VERSION ""

NS_ :

BS_:

BU_:

BO_ 2566631678 DCACAI5CFG1: 13 Vector__XXX
 SG_ DCACAssIvt5ACSdDtFqCdStt : 96|8@1+ (1,0) [0|250] "Hz" Vector__XXX
 SG_ DCACAssIvt5ACSdRMSCtMxLtStt : 48|16@1+ (0.03125,0) [0|2007.96875] "Arms" Vector__XXX
 SG_ DCACAssIvt5ACSdRMSVtMxLtStt : 32|16@1+ (0.03125,0) [0|2007.96875] "Vrms" Vector__XXX
 SG_ DCACAssIvt5DCSdCtMLtStt : 80|16@1+ (0.05,-3212.75) [-3212.75|0] "A" Vector__XXX
 SG_ DCACAssIvt5DCSdCtMxLtStt : 16|16@1+ (0.05,0) [0|3212.75] "A" Vector__XXX
 SG_ DCACAssIvt5DCSdVtMLtStt : 0|16@1+ (0.05,0) [0|3212.75] "V" Vector__XXX
 SG_ DCACAssIvt5DCSdVtMxLtStt : 64|16@1+ (0.05,0) [0|3212.75] "V" Vector__XXX

BO_ 2566631934 DCACAI5LD: 8 Vector__XXX
 SG_ DCACAssrInvrtr5TtlDCInptChrg : 0|32@1+ (100,0) [0|421108121500] "Ah" Vector__XXX
 SG_ DCACAssrInvrtr5TtlDCInptEnrg : 32|32@1+ (100,0) [0|421108121500] "Watt-hour" Vector__XXX

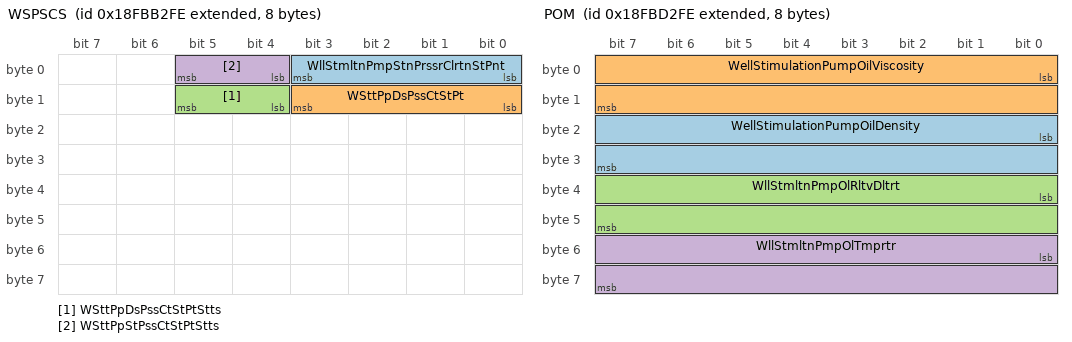
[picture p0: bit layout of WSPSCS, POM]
BO_ 2566632190 WSPSCS: 8 Vector__XXX
 SG_ WllStmltnPmpStnPrssrClrtnStPnt : 0|4@1+ (1,0) [0|15] "" Vector__XXX
 SG_ WSttPpDsPssCtStPt : 8|4@1+ (1,0) [0|15] "" Vector__XXX
 SG_ WSttPpDsPssCtStPtStts : 12|2@1+ (1,0) [0|3] "" Vector__XXX
 SG_ WSttPpStPssCtStPtStts : 4|2@1+ (1,0) [0|3] "" Vector__XXX

BO_ 2566632446 WSPFV: 8 Vector__XXX
 SG_ WllStmltnPmpTrpFldPmpd : 32|32@1+ (0.5,0) [0|2105540607.5] "l" Vector__XXX
 SG_ WllStmltnPmpTtlFldPmpd : 0|32@1+ (0.5,0) [0|2105540607.5] "l" Vector__XXX

BO_ 2566632702 WSPSN: 200 Vector__XXX
 SG_ WllStmltnPmpFldEndSrlNmr : 8|8@1+ (1,0) [0|255] "ASCII" Vector__XXX
 SG_ WllStmltnPmpPwrEndSrlNmr : 0|8@1+ (1,0) [0|255] "ASCII" Vector__XXX

BO_ 2566632958 WSPH2: 8 Vector__XXX
 SG_ WllStmltnPmpFldEndTrpHrs : 0|32@1+ (1,0) [0|4211081215] "s" Vector__XXX
 SG_ WllStmltnPmpPwrEndTrpHrs : 32|32@1+ (1,0) [0|4211081215] "s" Vector__XXX

BO_ 2566633214 AT1OG4: 8 Vector__XXX
 SG_ Aftrtrtmnt1OtltOxgnPmpngCrrnt : 0|16@1+ (0.001,-32.127) [-32.127|32.128] "mA" Vector__XXX
 SG_ Atttt1OttNOxSsPttAPssAst : 16|16@1+ (0.1,0) [0|6425.5] "kPa" Vector__XXX

BO_ 2566633470 AT1IG4: 8 Vector__XXX
 SG_ Aftrtrtmnt1IntkOxgnPmpngCrrnt : 0|16@1+ (0.001,-32.127) [-32.127|32.128] "mA" Vector__XXX
 SG_ Atttt1ItNOxSsPttAPssAst : 16|16@1+ (0.1,0) [0|6425.5] "kPa" Vector__XXX

BO_ 2566633726 DCDC4LD: 16 Vector__XXX
 SG_ DCDC4TotalHighSideCharge : 64|32@1+ (100,0) [0|421108121500] "Ah" Vector__XXX
 SG_ DCDC4TotalHighSideEnergy : 0|32@1+ (100,0) [0|421108121500] "Watt-hour" Vector__XXX
 SG_ DCDC4TotalLowSideCharge : 96|32@1+ (100,0) [0|421108121500] "Ah" Vector__XXX
 SG_ DCDC4TotalLowSideEnergy : 32|32@1+ (100,0) [0|421108121500] "Watt-hour" Vector__XXX

BO_ 2566633982 DCDC4CFG1: 19 Vector__XXX
 SG_ DCDC4HghSdCrrntMxmmLmtSttng : 32|16@1+ (0.05,0) [0|3212.75] "A" Vector__XXX
 SG_ DCDC4HghSdVltgMnmmLmtSttng : 0|16@1+ (0.05,0) [0|3212.75] "V" Vector__XXX
 SG_ DCDC4HghSdVltgMxmmLmtSttng : 16|16@1+ (0.05,0) [0|3212.75] "V" Vector__XXX
 SG_ DCDC4LwSdCrrntMxmmLmtSttng : 80|16@1+ (0.05,0) [0|3212.75] "A" Vector__XXX
 SG_ DCDC4LwSdVltgBkDfltSttng : 136|16@1+ (0.01,0) [0|642.55] "V" Vector__XXX
 SG_ DCDC4LwSdVltgMnmmLmtSttng : 48|16@1+ (0.01,0) [0|642.55] "V" Vector__XXX
 SG_ DCDC4LwSdVltgMxmmLmtSttng : 64|16@1+ (0.01,0) [0|642.55] "V" Vector__XXX
 SG_ DCDC4SLIBttrTmprtrMxmmLmtSttng : 128|8@1+ (1,-40) [-40|210] "degC" Vector__XXX
 SG_ DCDC4SLIBttTCCtMxLtStt : 112|16@1+ (0.05,0) [0|3212.75] "A" Vector__XXX
 SG_ DCDC4SLIBttTVtMxLtStt : 96|16@1+ (0.01,0) [0|642.55] "V" Vector__XXX

BO_ 2566635262 DCDC3LD: 16 Vector__XXX
 SG_ DCDC3TotalHighSideCharge : 64|32@1+ (100,0) [0|421108121500] "Ah" Vector__XXX
 SG_ DCDC3TotalHighSideEnergy : 0|32@1+ (100,0) [0|421108121500] "Watt-hour" Vector__XXX
 SG_ DCDC3TotalLowSideCharge : 96|32@1+ (100,0) [0|421108121500] "Ah" Vector__XXX
 SG_ DCDC3TotalLowSideEnergy : 32|32@1+ (100,0) [0|421108121500] "Watt-hour" Vector__XXX

BO_ 2566635518 DCDC3CFG1: 19 Vector__XXX
 SG_ DCDC3HghSdCrrntMxmmLmtSttng : 32|16@1+ (0.05,0) [0|3212.75] "A" Vector__XXX
 SG_ DCDC3HghSdVltgMnmmLmtSttng : 0|16@1+ (0.05,0) [0|3212.75] "V" Vector__XXX
 SG_ DCDC3HghSdVltgMxmmLmtSttng : 16|16@1+ (0.05,0) [0|3212.75] "V" Vector__XXX
 SG_ DCDC3LwSdCrrntMxmmLmtSttng : 80|16@1+ (0.05,0) [0|3212.75] "A" Vector__XXX
 SG_ DCDC3LwSdVltgBkDfltSttng : 136|16@1+ (0.01,0) [0|642.55] "V" Vector__XXX
 SG_ DCDC3LwSdVltgMnmmLmtSttng : 48|16@1+ (0.01,0) [0|642.55] "V" Vector__XXX
 SG_ DCDC3LwSdVltgMxmmLmtSttng : 64|16@1+ (0.01,0) [0|642.55] "V" Vector__XXX
 SG_ DCDC3SLIBttrTmprtrMxmmLmtSttng : 128|8@1+ (1,-40) [-40|210] "degC" Vector__XXX
 SG_ DCDC3SLIBttTCCtMxLtStt : 112|16@1+ (0.05,0) [0|3212.75] "A" Vector__XXX
 SG_ DCDC3SLIBttTVtMxLtStt : 96|16@1+ (0.01,0) [0|642.55] "V" Vector__XXX

BO_ 2566636798 DCDC2LD: 16 Vector__XXX
 SG_ DCDC2TotalHighSideCharge : 64|32@1+ (100,0) [0|421108121500] "Ah" Vector__XXX
 SG_ DCDC2TotalHighSideEnergy : 0|32@1+ (100,0) [0|421108121500] "Watt-hour" Vector__XXX
 SG_ DCDC2TotalLowSideCharge : 96|32@1+ (100,0) [0|421108121500] "Ah" Vector__XXX
 SG_ DCDC2TotalLowSideEnergy : 32|32@1+ (100,0) [0|421108121500] "Watt-hour" Vector__XXX

BO_ 2566637054 DCDC2CFG1: 19 Vector__XXX
 SG_ DCDC2HghSdCrrntMxmmLmtSttng : 32|16@1+ (0.05,0) [0|3212.75] "A" Vector__XXX
 SG_ DCDC2HghSdVltgMnmmLmtSttng : 0|16@1+ (0.05,0) [0|3212.75] "V" Vector__XXX
 SG_ DCDC2HghSdVltgMxmmLmtSttng : 16|16@1+ (0.05,0) [0|3212.75] "V" Vector__XXX
 SG_ DCDC2LwSdCrrntMxmmLmtSttng : 80|16@1+ (0.05,0) [0|3212.75] "A" Vector__XXX
 SG_ DCDC2LwSdVltgBkDfltSttng : 136|16@1+ (0.01,0) [0|642.55] "V" Vector__XXX
 SG_ DCDC2LwSdVltgMnmmLmtSttng : 48|16@1+ (0.01,0) [0|642.55] "V" Vector__XXX
 SG_ DCDC2LwSdVltgMxmmLmtSttng : 64|16@1+ (0.01,0) [0|642.55] "V" Vector__XXX
 SG_ DCDC2SLIBttrTmprtrMxmmLmtSttng : 128|8@1+ (1,-40) [-40|210] "degC" Vector__XXX
 SG_ DCDC2SLIBttTCCtMxLtStt : 112|16@1+ (0.05,0) [0|3212.75] "A" Vector__XXX
 SG_ DCDC2SLIBttTVtMxLtStt : 96|16@1+ (0.01,0) [0|642.55] "V" Vector__XXX

BO_ 2566638590 EEPCSI: 8 Vector__XXX
 SG_ ExhstPrtltCntrlSstmDgnstCnt : 32|32@1+ (1,0) [0|4211081215] "count" Vector__XXX
 SG_ ExhstPrtltCntrlSstmDgnstTm : 0|32@1+ (1,0) [0|4211081215] "s" Vector__XXX

BO_ 2566638846 WSPH: 16 Vector__XXX
 SG_ WllStmltnPmpMntnnIntrvlHrs : 0|32@1+ (1,0) [0|4211081215] "s" Vector__XXX
 SG_ WllStmltnPmpPkngOprtnHrs : 64|32@1+ (1,0) [0|4211081215] "s" Vector__XXX
 SG_ WllStmltnPmpVlvOprtnHrs : 32|32@1+ (1,0) [0|4211081215] "s" Vector__XXX
 SG_ WllStmltnPmpVlvStOprtnHrs : 96|32@1+ (1,0) [0|4211081215] "s" Vector__XXX

BO_ 2566639102 WSPT2: 19 Vector__XXX
 SG_ WllStmltnPmpPlngrFrngOrdrSttng : 144|4@1+ (1,0) [0|15] "" Vector__XXX
 SG_ WllStmltnPmpRdLdHghThrshldSttng : 128|16@1+ (5,0) [0|321275] "kN" Vector__XXX
 SG_ WSttPpCstSpdHTsdStt : 112|16@1+ (0.125,0) [0|8031.875] "rpm" Vector__XXX
 SG_ WSttPpCstSpdLwTsdStt : 96|16@1+ (0.125,0) [0|8031.875] "rpm" Vector__XXX
 SG_ WSttPpDsPssHTsdStt : 80|16@1+ (5,0) [0|321275] "kPa" Vector__XXX
 SG_ WSttPpGBxOPssHTsdStt : 16|16@1+ (0.1,0) [0|6425.5] "kPa" Vector__XXX
 SG_ WSttPpGBxOPssLwTsdStt : 0|16@1+ (0.1,0) [0|6425.5] "kPa" Vector__XXX
 SG_ WSttPpGBxOTptHTsdStt : 40|8@1+ (1,-40) [-40|210] "degC" Vector__XXX
 SG_ WSttPpGBxOTptLwTsdStt : 32|8@1+ (1,-40) [-40|210] "degC" Vector__XXX
 SG_ WSttPpStPssHTsdStt : 64|16@1+ (0.1,-3212.7) [-3212.7|3212.8] "kPa" Vector__XXX
 SG_ WSttPpStPssLwTsdStt : 48|16@1+ (0.1,-3212.7) [-3212.7|3212.8] "kPa" Vector__XXX

BO_ 2566639614 DCDC1LD: 16 Vector__XXX
 SG_ DCDC1TotalHighSideCharge : 64|32@1+ (100,0) [0|421108121500] "Ah" Vector__XXX
 SG_ DCDC1TotalHighSideEnergy : 0|32@1+ (100,0) [0|421108121500] "Watt-hour" Vector__XXX
 SG_ DCDC1TotalLowSideCharge : 96|32@1+ (100,0) [0|421108121500] "Ah" Vector__XXX
 SG_ DCDC1TotalLowSideEnergy : 32|32@1+ (100,0) [0|421108121500] "Watt-hour" Vector__XXX

BO_ 2566639870 DCDC1CFG1: 19 Vector__XXX
 SG_ DCDC1HghSdCrrntMxmmLmtSttng : 32|16@1+ (0.05,0) [0|3212.75] "A" Vector__XXX
 SG_ DCDC1HghSdVltgMnmmLmtSttng : 0|16@1+ (0.05,0) [0|3212.75] "V" Vector__XXX
 SG_ DCDC1HghSdVltgMxmmLmtSttng : 16|16@1+ (0.05,0) [0|3212.75] "V" Vector__XXX
 SG_ DCDC1LwSdCrrntMxmmLmtSttng : 80|16@1+ (0.05,0) [0|3212.75] "A" Vector__XXX
 SG_ DCDC1LwSdVltgBkDfltSttng : 136|16@1+ (0.01,0) [0|642.55] "V" Vector__XXX
 SG_ DCDC1LwSdVltgMnmmLmtSttng : 48|16@1+ (0.01,0) [0|642.55] "V" Vector__XXX
 SG_ DCDC1LwSdVltgMxmmLmtSttng : 64|16@1+ (0.01,0) [0|642.55] "V" Vector__XXX
 SG_ DCDC1SLIBttrTmprtrMxmmLmtSttng : 128|8@1+ (1,-40) [-40|210] "degC" Vector__XXX
 SG_ DCDC1SLIBttTCCtMxLtStt : 112|16@1+ (0.05,0) [0|3212.75] "A" Vector__XXX
 SG_ DCDC1SLIBttTVtMxLtStt : 96|16@1+ (0.01,0) [0|642.55] "V" Vector__XXX

BO_ 2566640382 POM: 8 Vector__XXX
 SG_ WellStimulationPumpOilDensity : 16|16@1+ (0.00003052,0) [0|1.961] "g/cc" Vector__XXX
 SG_ WellStimulationPumpOilViscosity : 0|16@1+ (0.015625,0) [0|1003.984375] "Cp" Vector__XXX
 SG_ WllStmltnPmpOlRltvDltrt : 32|16@1+ (0.0001220703125,0) [0|7.844] "" Vector__XXX
 SG_ WllStmltnPmpOlTmprtr : 48|16@1+ (0.03125,-273) [-273|1734.96875] "degC" Vector__XXX

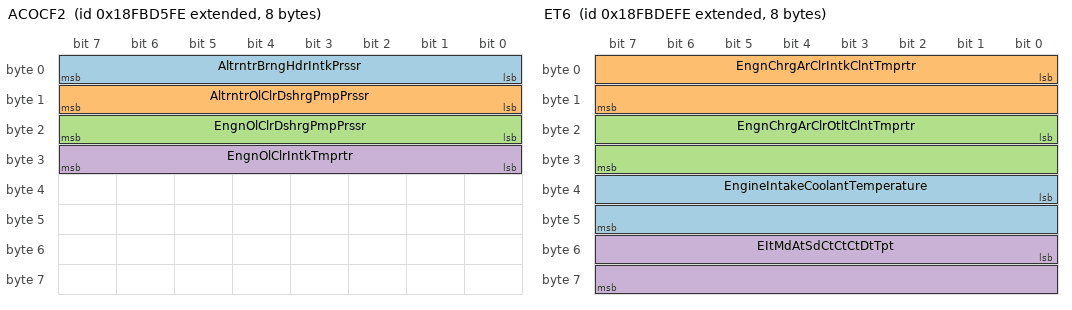
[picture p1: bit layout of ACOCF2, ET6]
BO_ 2566641150 ACOCF2: 8 Vector__XXX
 SG_ AltrntrBrngHdrIntkPrssr : 0|8@1+ (2,0) [0|500] "kPa" Vector__XXX
 SG_ AltrntrOlClrDshrgPmpPrssr : 8|8@1+ (2,0) [0|500] "kPa" Vector__XXX
 SG_ EngnOlClrDshrgPmpPrssr : 16|8@1+ (2,0) [0|500] "kPa" Vector__XXX
 SG_ EngnOlClrIntkTmprtr : 24|8@1+ (1,-40) [-40|210] "degC" Vector__XXX

BO_ 2566641406 EEC21: 8 Vector__XXX
 SG_ EngnExhstMnfldAsltPrssr1 : 0|16@1+ (0.1,0) [0|6425.5] "kPa" Vector__XXX
 SG_ EngnExhstMnfldAsltPrssr2 : 16|16@1+ (0.1,0) [0|6425.5] "kPa" Vector__XXX

BO_ 2566642942 DC4: 8 Vector__XXX
 SG_ EnableStatusofDoor21 : 4|2@1+ (1,0) [0|3] "" Vector__XXX
 SG_ EnableStatusofDoor22 : 10|2@1+ (1,0) [0|3] "" Vector__XXX
 SG_ EnableStatusofDoor23 : 16|2@1+ (1,0) [0|3] "" Vector__XXX
 SG_ EnableStatusofDoor24 : 22|2@1+ (1,0) [0|3] "" Vector__XXX
 SG_ EnableStatusofDoor25 : 28|2@1+ (1,0) [0|3] "" Vector__XXX
 SG_ EnableStatusofDoor26 : 34|2@1+ (1,0) [0|3] "" Vector__XXX
 SG_ EnableStatusofDoor27 : 40|2@1+ (1,0) [0|3] "" Vector__XXX
 SG_ EnableStatusofDoor28 : 46|2@1+ (1,0) [0|3] "" Vector__XXX
 SG_ EnableStatusofDoor29 : 52|2@1+ (1,0) [0|3] "" Vector__XXX
 SG_ EnableStatusofDoor30 : 58|2@1+ (1,0) [0|3] "" Vector__XXX
 SG_ LockStatusofDoor21 : 0|2@1+ (1,0) [0|3] "" Vector__XXX
 SG_ LockStatusofDoor22 : 6|2@1+ (1,0) [0|3] "" Vector__XXX
 SG_ LockStatusofDoor23 : 12|2@1+ (1,0) [0|3] "" Vector__XXX
 SG_ LockStatusofDoor24 : 18|2@1+ (1,0) [0|3] "" Vector__XXX
 SG_ LockStatusofDoor25 : 24|2@1+ (1,0) [0|3] "" Vector__XXX
 SG_ LockStatusofDoor26 : 30|2@1+ (1,0) [0|3] "" Vector__XXX
 SG_ LockStatusofDoor27 : 36|2@1+ (1,0) [0|3] "" Vector__XXX
 SG_ LockStatusofDoor28 : 42|2@1+ (1,0) [0|3] "" Vector__XXX
 SG_ LockStatusofDoor29 : 48|2@1+ (1,0) [0|3] "" Vector__XXX
 SG_ LockStatusofDoor30 : 54|2@1+ (1,0) [0|3] "" Vector__XXX
 SG_ OpenStatusofDoor21 : 2|2@1+ (1,0) [0|3] "" Vector__XXX
 SG_ OpenStatusofDoor22 : 8|2@1+ (1,0) [0|3] "" Vector__XXX
 SG_ OpenStatusofDoor23 : 14|2@1+ (1,0) [0|3] "" Vector__XXX
 SG_ OpenStatusofDoor24 : 20|2@1+ (1,0) [0|3] "" Vector__XXX
 SG_ OpenStatusofDoor25 : 26|2@1+ (1,0) [0|3] "" Vector__XXX
 SG_ OpenStatusofDoor26 : 32|2@1+ (1,0) [0|3] "" Vector__XXX
 SG_ OpenStatusofDoor27 : 38|2@1+ (1,0) [0|3] "" Vector__XXX
 SG_ OpenStatusofDoor28 : 44|2@1+ (1,0) [0|3] "" Vector__XXX
 SG_ OpenStatusofDoor29 : 50|2@1+ (1,0) [0|3] "" Vector__XXX
 SG_ OpenStatusofDoor30 : 56|2@1+ (1,0) [0|3] "" Vector__XXX

BO_ 2566643198 DC3: 8 Vector__XXX
 SG_ EnableStatusofDoor11 : 4|2@1+ (1,0) [0|3] "" Vector__XXX
 SG_ EnableStatusofDoor12 : 10|2@1+ (1,0) [0|3] "" Vector__XXX
 SG_ EnableStatusofDoor13 : 16|2@1+ (1,0) [0|3] "" Vector__XXX
 SG_ EnableStatusofDoor14 : 22|2@1+ (1,0) [0|3] "" Vector__XXX
 SG_ EnableStatusofDoor15 : 28|2@1+ (1,0) [0|3] "" Vector__XXX
 SG_ EnableStatusofDoor16 : 34|2@1+ (1,0) [0|3] "" Vector__XXX
 SG_ EnableStatusofDoor17 : 40|2@1+ (1,0) [0|3] "" Vector__XXX
 SG_ EnableStatusofDoor18 : 46|2@1+ (1,0) [0|3] "" Vector__XXX
 SG_ EnableStatusofDoor19 : 52|2@1+ (1,0) [0|3] "" Vector__XXX
 SG_ EnableStatusofDoor20 : 58|2@1+ (1,0) [0|3] "" Vector__XXX
 SG_ LockStatusofDoor11 : 0|2@1+ (1,0) [0|3] "" Vector__XXX
 SG_ LockStatusofDoor12 : 6|2@1+ (1,0) [0|3] "" Vector__XXX
 SG_ LockStatusofDoor13 : 12|2@1+ (1,0) [0|3] "" Vector__XXX
 SG_ LockStatusofDoor14 : 18|2@1+ (1,0) [0|3] "" Vector__XXX
 SG_ LockStatusofDoor15 : 24|2@1+ (1,0) [0|3] "" Vector__XXX
 SG_ LockStatusofDoor16 : 30|2@1+ (1,0) [0|3] "" Vector__XXX
 SG_ LockStatusofDoor17 : 36|2@1+ (1,0) [0|3] "" Vector__XXX
 SG_ LockStatusofDoor18 : 42|2@1+ (1,0) [0|3] "" Vector__XXX
 SG_ LockStatusofDoor19 : 48|2@1+ (1,0) [0|3] "" Vector__XXX
 SG_ LockStatusofDoor20 : 54|2@1+ (1,0) [0|3] "" Vector__XXX
 SG_ OpenStatusofDoor11 : 2|2@1+ (1,0) [0|3] "" Vector__XXX
 SG_ OpenStatusofDoor12 : 8|2@1+ (1,0) [0|3] "" Vector__XXX
 SG_ OpenStatusofDoor13 : 14|2@1+ (1,0) [0|3] "" Vector__XXX
 SG_ OpenStatusofDoor14 : 20|2@1+ (1,0) [0|3] "" Vector__XXX
 SG_ OpenStatusofDoor15 : 26|2@1+ (1,0) [0|3] "" Vector__XXX
 SG_ OpenStatusofDoor16 : 32|2@1+ (1,0) [0|3] "" Vector__XXX
 SG_ OpenStatusofDoor17 : 38|2@1+ (1,0) [0|3] "" Vector__XXX
 SG_ OpenStatusofDoor18 : 44|2@1+ (1,0) [0|3] "" Vector__XXX
 SG_ OpenStatusofDoor19 : 50|2@1+ (1,0) [0|3] "" Vector__XXX
 SG_ OpenStatusofDoor20 : 56|2@1+ (1,0) [0|3] "" Vector__XXX

BO_ 2566643454 ET6: 8 Vector__XXX
 SG_ EngineIntakeCoolantTemperature : 32|16@1+ (0.03125,-273) [-273|1734.96875] "degC" Vector__XXX
 SG_ EngnChrgArClrIntkClntTmprtr : 0|16@1+ (0.03125,-273) [-273|1734.96875] "degC" Vector__XXX
 SG_ EngnChrgArClrOtltClntTmprtr : 16|16@1+ (0.03125,-273) [-273|1734.96875] "degC" Vector__XXX
 SG_ EItMdAtSdCtCtCtDtTpt : 48|16@1+ (0.03125,-273) [-273|1734.96875] "degC" Vector__XXX

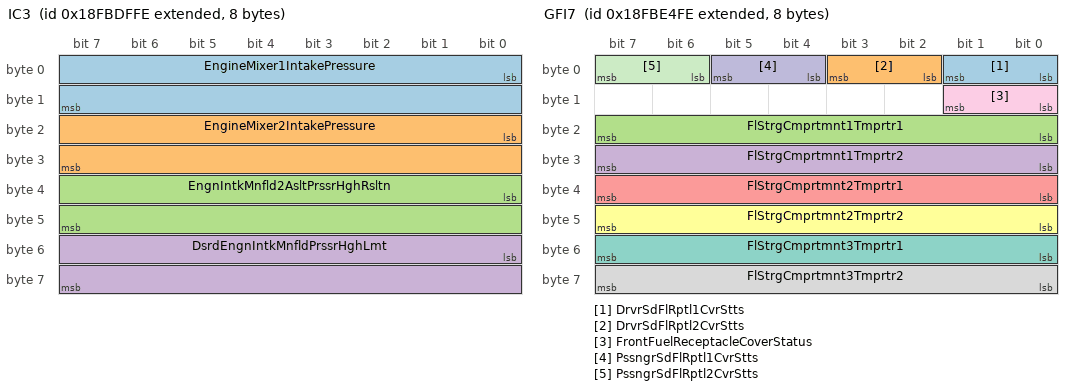
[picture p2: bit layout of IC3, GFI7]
BO_ 2566643710 IC3: 8 Vector__XXX
 SG_ EngineMixer1IntakePressure : 0|16@1+ (0.1,0) [0|6425.5] "kPa" Vector__XXX
 SG_ EngineMixer2IntakePressure : 16|16@1+ (0.1,0) [0|6425.5] "kPa" Vector__XXX
 SG_ EngnIntkMnfld2AsltPrssrHghRsltn : 32|16@1+ (0.1,0) [0|6425.5] "kPa" Vector__XXX
 SG_ DsrdEngnIntkMnfldPrssrHghLmt : 48|16@1+ (0.1,0) [0|6425.5] "kPa" Vector__XXX

BO_ 2566644990 GFI7: 8 Vector__XXX
 SG_ DrvrSdFlRptl1CvrStts : 0|2@1+ (1,0) [0|3] "" Vector__XXX
 SG_ DrvrSdFlRptl2CvrStts : 2|2@1+ (1,0) [0|3] "" Vector__XXX
 SG_ FlStrgCmprtmnt1Tmprtr1 : 16|8@1+ (1,-40) [-40|210] "degC" Vector__XXX
 SG_ FlStrgCmprtmnt1Tmprtr2 : 24|8@1+ (1,-40) [-40|210] "degC" Vector__XXX
 SG_ FlStrgCmprtmnt2Tmprtr1 : 32|8@1+ (1,-40) [-40|210] "degC" Vector__XXX
 SG_ FlStrgCmprtmnt2Tmprtr2 : 40|8@1+ (1,-40) [-40|210] "degC" Vector__XXX
 SG_ FlStrgCmprtmnt3Tmprtr1 : 48|8@1+ (1,-40) [-40|210] "degC" Vector__XXX
 SG_ FlStrgCmprtmnt3Tmprtr2 : 56|8@1+ (1,-40) [-40|210] "degC" Vector__XXX
 SG_ FrontFuelReceptacleCoverStatus : 8|2@1+ (1,0) [0|3] "" Vector__XXX
 SG_ PssngrSdFlRptl1CvrStts : 4|2@1+ (1,0) [0|3] "" Vector__XXX
 SG_ PssngrSdFlRptl2CvrStts : 6|2@1+ (1,0) [0|3] "" Vector__XXX

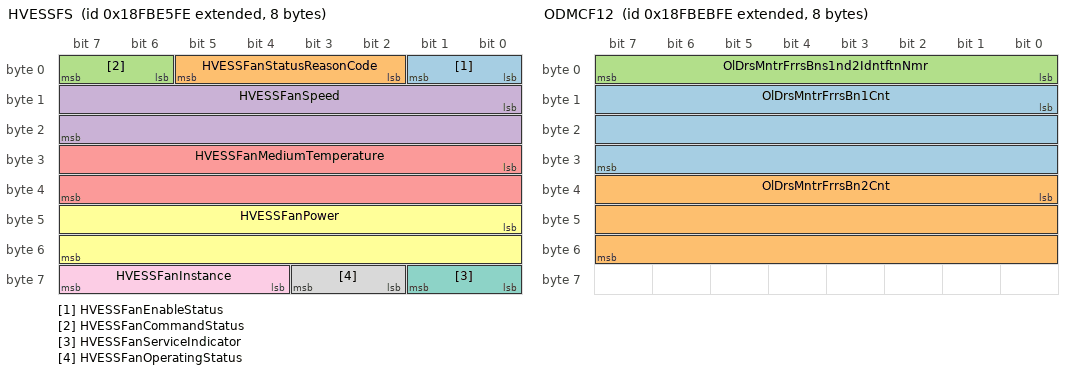
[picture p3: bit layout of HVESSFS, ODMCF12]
BO_ 2566645246 HVESSFS: 8 Vector__XXX
 SG_ HVESSFanEnableStatus : 0|2@1+ (1,0) [0|3] "" Vector__XXX
 SG_ HVESSFanStatusReasonCode : 2|4@1+ (1,0) [0|15] "" Vector__XXX
 SG_ HVESSFanCommandStatus : 6|2@1+ (1,0) [0|3] "" Vector__XXX
 SG_ HVESSFanSpeed : 8|16@1+ (0.5,0) [0|32127.5] "rpm" Vector__XXX
 SG_ HVESSFanMediumTemperature : 24|16@1+ (0.03125,-273) [-273|1734.96875] "degC" Vector__XXX
 SG_ HVESSFanPower : 40|16@1+ (0.5,0) [0|32127.5] "W" Vector__XXX
 SG_ HVESSFanServiceIndicator : 56|2@1+ (1,0) [0|3] "" Vector__XXX
 SG_ HVESSFanOperatingStatus : 58|2@1+ (1,0) [0|3] "" Vector__XXX
 SG_ HVESSFanInstance : 60|4@1+ (1,0) [0|15] "" Vector__XXX

BO_ 2566646782 ODMCF12: 8 Vector__XXX
 SG_ OlDrsMntrFrrsBn1Cnt : 8|24@1+ (1,0) [0|16449535] "count" Vector__XXX
 SG_ OlDrsMntrFrrsBn2Cnt : 32|24@1+ (1,0) [0|16449535] "count" Vector__XXX
 SG_ OlDrsMntrFrrsBns1nd2IdntftnNmr : 0|8@1+ (1,0) [0|250] "count" Vector__XXX

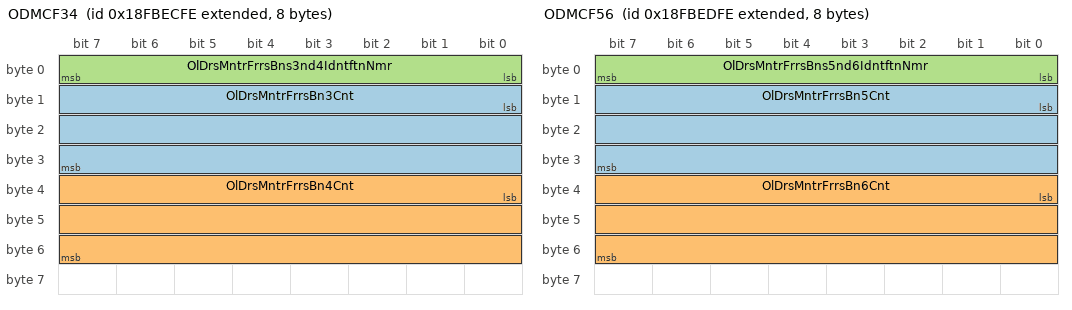
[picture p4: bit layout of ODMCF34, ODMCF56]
BO_ 2566647038 ODMCF34: 8 Vector__XXX
 SG_ OlDrsMntrFrrsBn3Cnt : 8|24@1+ (1,0) [0|16449535] "count" Vector__XXX
 SG_ OlDrsMntrFrrsBn4Cnt : 32|24@1+ (1,0) [0|16449535] "count" Vector__XXX
 SG_ OlDrsMntrFrrsBns3nd4IdntftnNmr : 0|8@1+ (1,0) [0|250] "count" Vector__XXX

BO_ 2566647294 ODMCF56: 8 Vector__XXX
 SG_ OlDrsMntrFrrsBn5Cnt : 8|24@1+ (1,0) [0|16449535] "count" Vector__XXX
 SG_ OlDrsMntrFrrsBn6Cnt : 32|24@1+ (1,0) [0|16449535] "count" Vector__XXX
 SG_ OlDrsMntrFrrsBns5nd6IdntftnNmr : 0|8@1+ (1,0) [0|250] "count" Vector__XXX

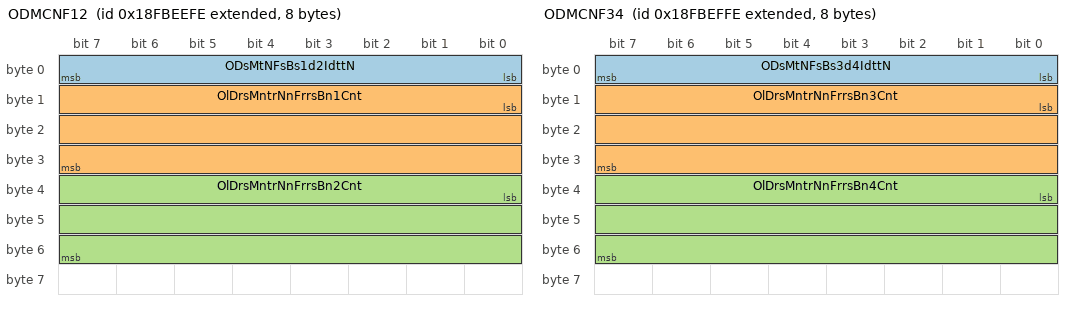
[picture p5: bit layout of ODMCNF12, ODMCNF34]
BO_ 2566647550 ODMCNF12: 8 Vector__XXX
 SG_ ODsMtNFsBs1d2IdttN : 0|8@1+ (1,0) [0|250] "count" Vector__XXX
 SG_ OlDrsMntrNnFrrsBn1Cnt : 8|24@1+ (1,0) [0|16449535] "count" Vector__XXX
 SG_ OlDrsMntrNnFrrsBn2Cnt : 32|24@1+ (1,0) [0|16449535] "count" Vector__XXX

BO_ 2566647806 ODMCNF34: 8 Vector__XXX
 SG_ ODsMtNFsBs3d4IdttN : 0|8@1+ (1,0) [0|250] "count" Vector__XXX
 SG_ OlDrsMntrNnFrrsBn3Cnt : 8|24@1+ (1,0) [0|16449535] "count" Vector__XXX
 SG_ OlDrsMntrNnFrrsBn4Cnt : 32|24@1+ (1,0) [0|16449535] "count" Vector__XXX

BO_ 2566648062 ODMCNF56: 8 Vector__XXX
 SG_ ODsMtNFsBs5d6IdttN : 0|8@1+ (1,0) [0|250] "count" Vector__XXX
 SG_ OlDrsMntrNnFrrsBn5Cnt : 8|24@1+ (1,0) [0|16449535] "count" Vector__XXX
 SG_ OlDrsMntrNnFrrsBn6Cnt : 32|24@1+ (1,0) [0|16449535] "count" Vector__XXX

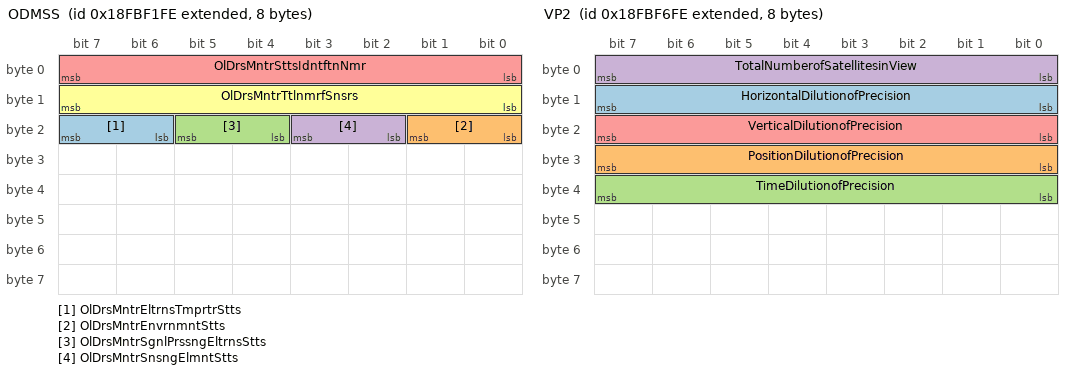
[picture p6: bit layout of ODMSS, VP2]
BO_ 2566648318 ODMSS: 8 Vector__XXX
 SG_ OlDrsMntrEltrnsTmprtrStts : 22|2@1+ (1,0) [0|3] "" Vector__XXX
 SG_ OlDrsMntrEnvrnmntStts : 16|2@1+ (1,0) [0|3] "" Vector__XXX
 SG_ OlDrsMntrSgnlPrssngEltrnsStts : 20|2@1+ (1,0) [0|3] "" Vector__XXX
 SG_ OlDrsMntrSnsngElmntStts : 18|2@1+ (1,0) [0|3] "" Vector__XXX
 SG_ OlDrsMntrSttsIdntftnNmr : 0|8@1+ (1,0) [0|250] "count" Vector__XXX
 SG_ OlDrsMntrTtlnmrfSnsrs : 8|8@1+ (1,0) [0|250] "count" Vector__XXX

BO_ 2566649086 A2DOC2: 8 Vector__XXX
 SG_ Atttt2DOCIttDPFOttDtPss : 32|16@1+ (0.1,0) [0|6425.5] "kPa" Vector__XXX
 SG_ Atttt2DsOxdtCtstItPss : 0|16@1+ (0.1,0) [0|6425.5] "kPa" Vector__XXX
 SG_ Atttt2DsOxdtCtstOttPss : 16|16@1+ (0.1,0) [0|6425.5] "kPa" Vector__XXX

BO_ 2566649342 A1DOC2: 8 Vector__XXX
 SG_ Atttt1DOCIttDPFOttDtPss : 32|16@1+ (0.1,0) [0|6425.5] "kPa" Vector__XXX
 SG_ Atttt1DsOxdtCtstItPss : 0|16@1+ (0.1,0) [0|6425.5] "kPa" Vector__XXX
 SG_ Atttt1DsOxdtCtstOttPss : 16|16@1+ (0.1,0) [0|6425.5] "kPa" Vector__XXX

BO_ 2566649598 VP2: 8 Vector__XXX
 SG_ HorizontalDilutionofPrecision : 8|8@1+ (0.1,0) [0|25] "Ratio" Vector__XXX
 SG_ PositionDilutionofPrecision : 24|8@1+ (0.1,0) [0|25] "Ratio" Vector__XXX
 SG_ TimeDilutionofPrecision : 32|8@1+ (0.1,0) [0|25] "Ratio" Vector__XXX
 SG_ TotalNumberofSatellitesinView : 0|8@1+ (1,0) [0|250] "count" Vector__XXX
 SG_ VerticalDilutionofPrecision : 16|8@1+ (0.1,0) [0|25] "Ratio" Vector__XXX

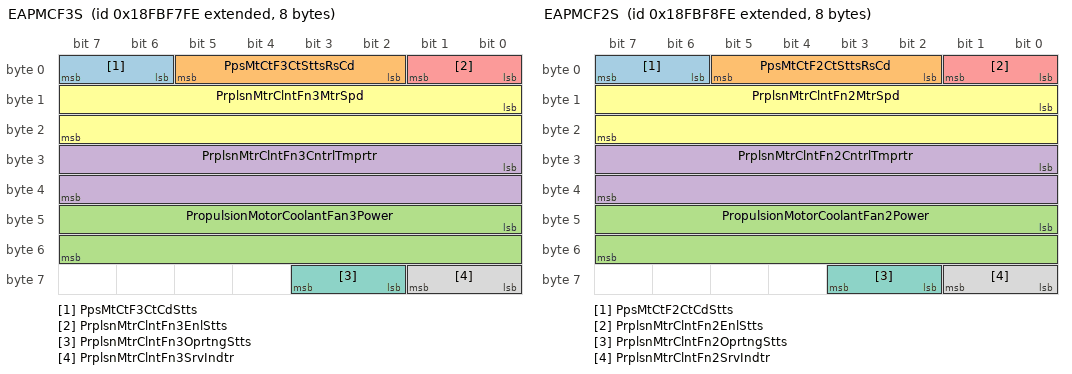
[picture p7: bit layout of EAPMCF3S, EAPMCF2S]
BO_ 2566649854 EAPMCF3S: 8 Vector__XXX
 SG_ PpsMtCtF3CtCdStts : 6|2@1+ (1,0) [0|3] "" Vector__XXX
 SG_ PpsMtCtF3CtSttsRsCd : 2|4@1+ (1,0) [0|15] "" Vector__XXX
 SG_ PropulsionMotorCoolantFan3Power : 40|16@1+ (0.5,0) [0|32127.5] "W" Vector__XXX
 SG_ PrplsnMtrClntFn3CntrlTmprtr : 24|16@1+ (0.03125,-273) [-273|1734.96875] "degC" Vector__XXX
 SG_ PrplsnMtrClntFn3EnlStts : 0|2@1+ (1,0) [0|3] "" Vector__XXX
 SG_ PrplsnMtrClntFn3MtrSpd : 8|16@1+ (0.5,0) [0|32127.5] "rpm" Vector__XXX
 SG_ PrplsnMtrClntFn3OprtngStts : 58|2@1+ (1,0) [0|3] "" Vector__XXX
 SG_ PrplsnMtrClntFn3SrvIndtr : 56|2@1+ (1,0) [0|3] "" Vector__XXX

BO_ 2566650110 EAPMCF2S: 8 Vector__XXX
 SG_ PpsMtCtF2CtCdStts : 6|2@1+ (1,0) [0|3] "" Vector__XXX
 SG_ PpsMtCtF2CtSttsRsCd : 2|4@1+ (1,0) [0|15] "" Vector__XXX
 SG_ PropulsionMotorCoolantFan2Power : 40|16@1+ (0.5,0) [0|32127.5] "W" Vector__XXX
 SG_ PrplsnMtrClntFn2CntrlTmprtr : 24|16@1+ (0.03125,-273) [-273|1734.96875] "degC" Vector__XXX
 SG_ PrplsnMtrClntFn2EnlStts : 0|2@1+ (1,0) [0|3] "" Vector__XXX
 SG_ PrplsnMtrClntFn2MtrSpd : 8|16@1+ (0.5,0) [0|32127.5] "rpm" Vector__XXX
 SG_ PrplsnMtrClntFn2OprtngStts : 58|2@1+ (1,0) [0|3] "" Vector__XXX
 SG_ PrplsnMtrClntFn2SrvIndtr : 56|2@1+ (1,0) [0|3] "" Vector__XXX

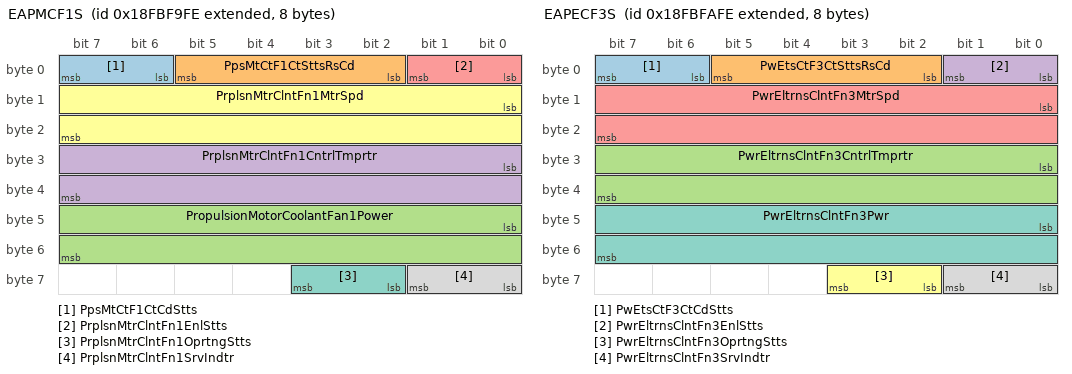
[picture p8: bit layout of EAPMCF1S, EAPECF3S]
BO_ 2566650366 EAPMCF1S: 8 Vector__XXX
 SG_ PpsMtCtF1CtCdStts : 6|2@1+ (1,0) [0|3] "" Vector__XXX
 SG_ PpsMtCtF1CtSttsRsCd : 2|4@1+ (1,0) [0|15] "" Vector__XXX
 SG_ PropulsionMotorCoolantFan1Power : 40|16@1+ (0.5,0) [0|32127.5] "W" Vector__XXX
 SG_ PrplsnMtrClntFn1CntrlTmprtr : 24|16@1+ (0.03125,-273) [-273|1734.96875] "degC" Vector__XXX
 SG_ PrplsnMtrClntFn1EnlStts : 0|2@1+ (1,0) [0|3] "" Vector__XXX
 SG_ PrplsnMtrClntFn1MtrSpd : 8|16@1+ (0.5,0) [0|32127.5] "rpm" Vector__XXX
 SG_ PrplsnMtrClntFn1OprtngStts : 58|2@1+ (1,0) [0|3] "" Vector__XXX
 SG_ PrplsnMtrClntFn1SrvIndtr : 56|2@1+ (1,0) [0|3] "" Vector__XXX

BO_ 2566650622 EAPECF3S: 8 Vector__XXX
 SG_ PwEtsCtF3CtCdStts : 6|2@1+ (1,0) [0|3] "" Vector__XXX
 SG_ PwEtsCtF3CtSttsRsCd : 2|4@1+ (1,0) [0|15] "" Vector__XXX
 SG_ PwrEltrnsClntFn3CntrlTmprtr : 24|16@1+ (0.03125,-273) [-273|1734.96875] "degC" Vector__XXX
 SG_ PwrEltrnsClntFn3EnlStts : 0|2@1+ (1,0) [0|3] "" Vector__XXX
 SG_ PwrEltrnsClntFn3MtrSpd : 8|16@1+ (0.5,0) [0|32127.5] "rpm" Vector__XXX
 SG_ PwrEltrnsClntFn3OprtngStts : 58|2@1+ (1,0) [0|3] "" Vector__XXX
 SG_ PwrEltrnsClntFn3Pwr : 40|16@1+ (0.5,0) [0|32127.5] "W" Vector__XXX
 SG_ PwrEltrnsClntFn3SrvIndtr : 56|2@1+ (1,0) [0|3] "" Vector__XXX

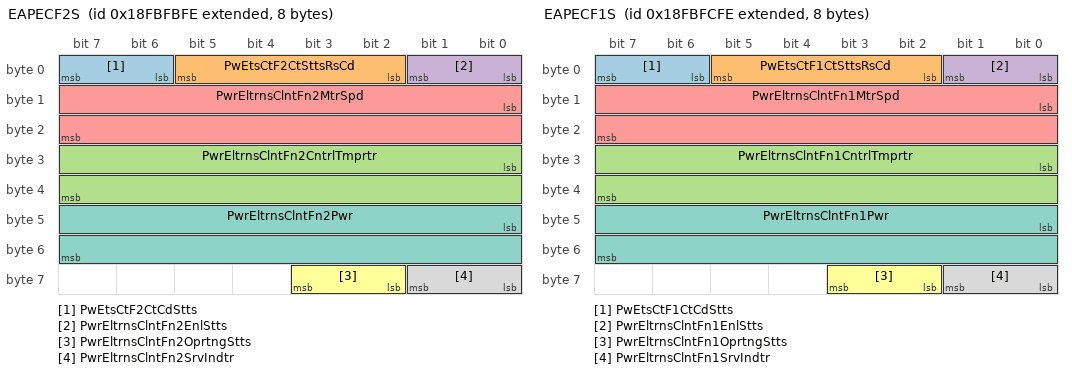
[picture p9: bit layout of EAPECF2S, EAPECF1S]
BO_ 2566650878 EAPECF2S: 8 Vector__XXX
 SG_ PwEtsCtF2CtCdStts : 6|2@1+ (1,0) [0|3] "" Vector__XXX
 SG_ PwEtsCtF2CtSttsRsCd : 2|4@1+ (1,0) [0|15] "" Vector__XXX
 SG_ PwrEltrnsClntFn2CntrlTmprtr : 24|16@1+ (0.03125,-273) [-273|1734.96875] "degC" Vector__XXX
 SG_ PwrEltrnsClntFn2EnlStts : 0|2@1+ (1,0) [0|3] "" Vector__XXX
 SG_ PwrEltrnsClntFn2MtrSpd : 8|16@1+ (0.5,0) [0|32127.5] "rpm" Vector__XXX
 SG_ PwrEltrnsClntFn2OprtngStts : 58|2@1+ (1,0) [0|3] "" Vector__XXX
 SG_ PwrEltrnsClntFn2Pwr : 40|16@1+ (0.5,0) [0|32127.5] "W" Vector__XXX
 SG_ PwrEltrnsClntFn2SrvIndtr : 56|2@1+ (1,0) [0|3] "" Vector__XXX

BO_ 2566651134 EAPECF1S: 8 Vector__XXX
 SG_ PwEtsCtF1CtCdStts : 6|2@1+ (1,0) [0|3] "" Vector__XXX
 SG_ PwEtsCtF1CtSttsRsCd : 2|4@1+ (1,0) [0|15] "" Vector__XXX
 SG_ PwrEltrnsClntFn1CntrlTmprtr : 24|16@1+ (0.03125,-273) [-273|1734.96875] "degC" Vector__XXX
 SG_ PwrEltrnsClntFn1EnlStts : 0|2@1+ (1,0) [0|3] "" Vector__XXX
 SG_ PwrEltrnsClntFn1MtrSpd : 8|16@1+ (0.5,0) [0|32127.5] "rpm" Vector__XXX
 SG_ PwrEltrnsClntFn1OprtngStts : 58|2@1+ (1,0) [0|3] "" Vector__XXX
 SG_ PwrEltrnsClntFn1Pwr : 40|16@1+ (0.5,0) [0|32127.5] "W" Vector__XXX
 SG_ PwrEltrnsClntFn1SrvIndtr : 56|2@1+ (1,0) [0|3] "" Vector__XXX

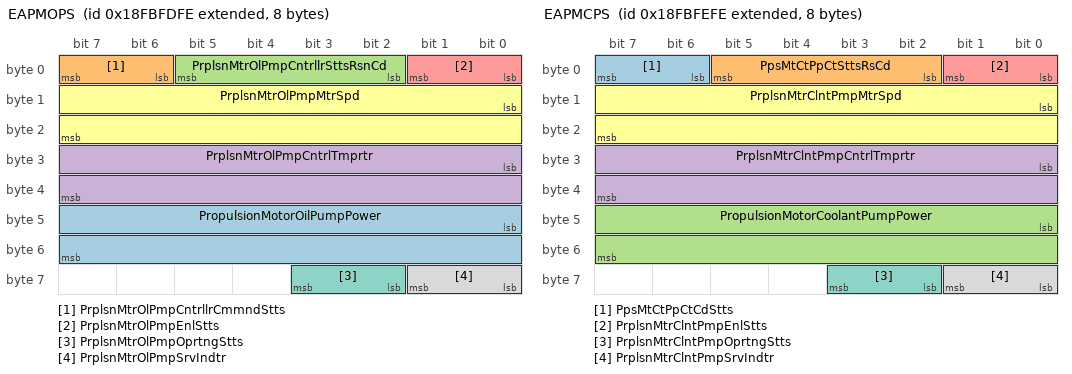
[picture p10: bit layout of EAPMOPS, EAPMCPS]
BO_ 2566651390 EAPMOPS: 8 Vector__XXX
 SG_ PropulsionMotorOilPumpPower : 40|16@1+ (0.5,0) [0|32127.5] "W" Vector__XXX
 SG_ PrplsnMtrOlPmpCntrllrCmmndStts : 6|2@1+ (1,0) [0|3] "" Vector__XXX
 SG_ PrplsnMtrOlPmpCntrllrSttsRsnCd : 2|4@1+ (1,0) [0|15] "" Vector__XXX
 SG_ PrplsnMtrOlPmpCntrlTmprtr : 24|16@1+ (0.03125,-273) [-273|1734.96875] "degC" Vector__XXX
 SG_ PrplsnMtrOlPmpEnlStts : 0|2@1+ (1,0) [0|3] "" Vector__XXX
 SG_ PrplsnMtrOlPmpMtrSpd : 8|16@1+ (0.5,0) [0|32127.5] "rpm" Vector__XXX
 SG_ PrplsnMtrOlPmpOprtngStts : 58|2@1+ (1,0) [0|3] "" Vector__XXX
 SG_ PrplsnMtrOlPmpSrvIndtr : 56|2@1+ (1,0) [0|3] "" Vector__XXX

BO_ 2566651646 EAPMCPS: 8 Vector__XXX
 SG_ PpsMtCtPpCtCdStts : 6|2@1+ (1,0) [0|3] "" Vector__XXX
 SG_ PpsMtCtPpCtSttsRsCd : 2|4@1+ (1,0) [0|15] "" Vector__XXX
 SG_ PropulsionMotorCoolantPumpPower : 40|16@1+ (0.5,0) [0|32127.5] "W" Vector__XXX
 SG_ PrplsnMtrClntPmpCntrlTmprtr : 24|16@1+ (0.03125,-273) [-273|1734.96875] "degC" Vector__XXX
 SG_ PrplsnMtrClntPmpEnlStts : 0|2@1+ (1,0) [0|3] "" Vector__XXX
 SG_ PrplsnMtrClntPmpMtrSpd : 8|16@1+ (0.5,0) [0|32127.5] "rpm" Vector__XXX
 SG_ PrplsnMtrClntPmpOprtngStts : 58|2@1+ (1,0) [0|3] "" Vector__XXX
 SG_ PrplsnMtrClntPmpSrvIndtr : 56|2@1+ (1,0) [0|3] "" Vector__XXX

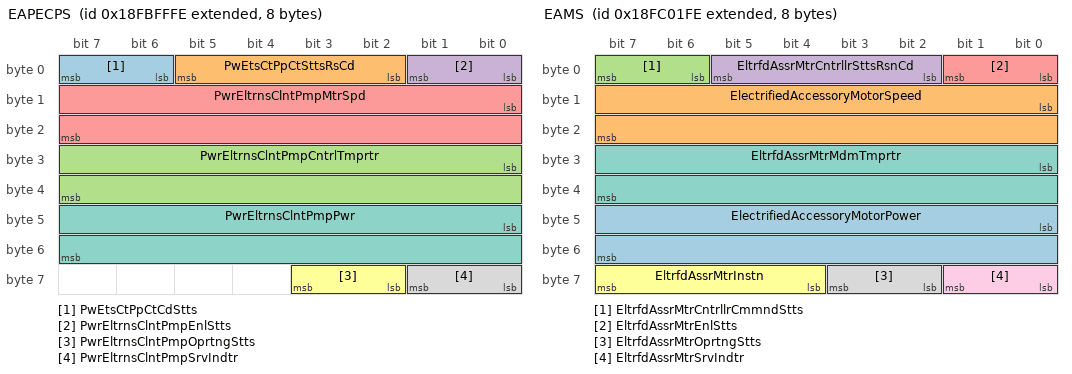
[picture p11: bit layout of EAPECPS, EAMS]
BO_ 2566651902 EAPECPS: 8 Vector__XXX
 SG_ PwEtsCtPpCtCdStts : 6|2@1+ (1,0) [0|3] "" Vector__XXX
 SG_ PwEtsCtPpCtSttsRsCd : 2|4@1+ (1,0) [0|15] "" Vector__XXX
 SG_ PwrEltrnsClntPmpCntrlTmprtr : 24|16@1+ (0.03125,-273) [-273|1734.96875] "degC" Vector__XXX
 SG_ PwrEltrnsClntPmpEnlStts : 0|2@1+ (1,0) [0|3] "" Vector__XXX
 SG_ PwrEltrnsClntPmpMtrSpd : 8|16@1+ (0.5,0) [0|32127.5] "rpm" Vector__XXX
 SG_ PwrEltrnsClntPmpOprtngStts : 58|2@1+ (1,0) [0|3] "" Vector__XXX
 SG_ PwrEltrnsClntPmpPwr : 40|16@1+ (0.5,0) [0|32127.5] "W" Vector__XXX
 SG_ PwrEltrnsClntPmpSrvIndtr : 56|2@1+ (1,0) [0|3] "" Vector__XXX

BO_ 2566652414 EAMS: 8 Vector__XXX
 SG_ ElectrifiedAccessoryMotorPower : 40|16@1+ (0.5,0) [0|32127.5] "W" Vector__XXX
 SG_ ElectrifiedAccessoryMotorSpeed : 8|16@1+ (0.5,0) [0|32127.5] "rpm" Vector__XXX
 SG_ EltrfdAssrMtrCntrllrCmmndStts : 6|2@1+ (1,0) [0|3] "" Vector__XXX
 SG_ EltrfdAssrMtrCntrllrSttsRsnCd : 2|4@1+ (1,0) [0|15] "" Vector__XXX
 SG_ EltrfdAssrMtrEnlStts : 0|2@1+ (1,0) [0|3] "" Vector__XXX
 SG_ EltrfdAssrMtrInstn : 60|4@1+ (1,0) [0|15] "" Vector__XXX
 SG_ EltrfdAssrMtrMdmTmprtr : 24|16@1+ (0.03125,-273) [-273|1734.96875] "degC" Vector__XXX
 SG_ EltrfdAssrMtrOprtngStts : 58|2@1+ (1,0) [0|3] "" Vector__XXX
 SG_ EltrfdAssrMtrSrvIndtr : 56|2@1+ (1,0) [0|3] "" Vector__XXX

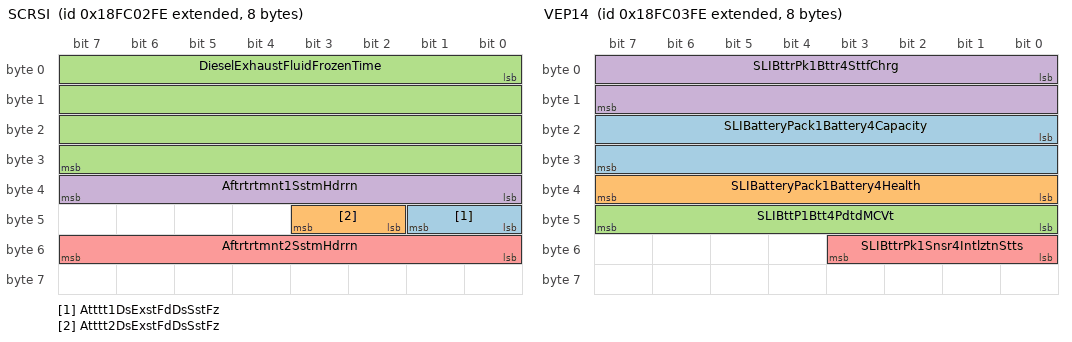
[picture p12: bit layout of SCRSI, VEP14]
BO_ 2566652670 SCRSI: 8 Vector__XXX
 SG_ Atttt1DsExstFdDsSstFz : 40|2@1+ (1,0) [0|3] "" Vector__XXX
 SG_ Atttt2DsExstFdDsSstFz : 42|2@1+ (1,0) [0|3] "" Vector__XXX
 SG_ DieselExhaustFluidFrozenTime : 0|32@1+ (1,0) [0|4211081215] "s" Vector__XXX
 SG_ Aftrtrtmnt1SstmHdrrn : 32|8@1+ (1,0) [0|250] "%" Vector__XXX
 SG_ Aftrtrtmnt2SstmHdrrn : 48|8@1+ (1,0) [0|250] "%" Vector__XXX

BO_ 2566652926 VEP14: 8 Vector__XXX
 SG_ SLIBatteryPack1Battery4Capacity : 16|16@1+ (1,0) [0|64255] "Ah" Vector__XXX
 SG_ SLIBatteryPack1Battery4Health : 32|8@1+ (0.5,0) [0|125] "%" Vector__XXX
 SG_ SLIBttP1Btt4PdtdMCVt : 40|8@1+ (0.2,0) [0|50] "V" Vector__XXX
 SG_ SLIBttrPk1Bttr4SttfChrg : 0|16@1+ (0.0025,0) [0|160.6375] "%" Vector__XXX
 SG_ SLIBttrPk1Snsr4IntlztnStts : 48|4@1+ (1,0) [0|15] "" Vector__XXX

BO_ 2566653182 VEP13: 8 Vector__XXX
 SG_ SLIBatteryPack1Battery4Voltage : 24|16@1+ (0.05,0) [0|3212.75] "V" Vector__XXX
 SG_ SLIBttrPk1Bttr4NtCrrnt : 0|16@1+ (0.05,-1600) [-1600|1612.75] "A" Vector__XXX
 SG_ SLIBttrPk1Bttr4Tmprtr : 16|8@1+ (1,-40) [-40|210] "degC" Vector__XXX

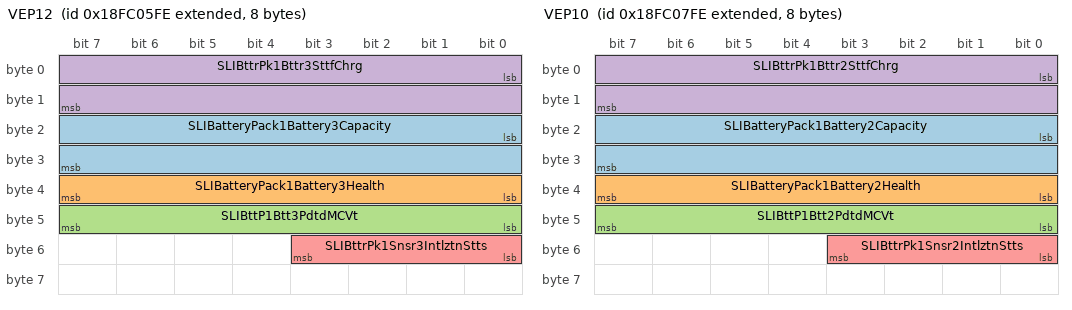
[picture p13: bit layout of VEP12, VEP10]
BO_ 2566653438 VEP12: 8 Vector__XXX
 SG_ SLIBatteryPack1Battery3Capacity : 16|16@1+ (1,0) [0|64255] "Ah" Vector__XXX
 SG_ SLIBatteryPack1Battery3Health : 32|8@1+ (0.5,0) [0|125] "%" Vector__XXX
 SG_ SLIBttP1Btt3PdtdMCVt : 40|8@1+ (0.2,0) [0|50] "V" Vector__XXX
 SG_ SLIBttrPk1Bttr3SttfChrg : 0|16@1+ (0.0025,0) [0|160.6375] "%" Vector__XXX
 SG_ SLIBttrPk1Snsr3IntlztnStts : 48|4@1+ (1,0) [0|15] "" Vector__XXX

BO_ 2566653694 VEP11: 8 Vector__XXX
 SG_ SLIBatteryPack1Battery3Voltage : 24|16@1+ (0.05,0) [0|3212.75] "V" Vector__XXX
 SG_ SLIBttrPk1Bttr3NtCrrnt : 0|16@1+ (0.05,-1600) [-1600|1612.75] "A" Vector__XXX
 SG_ SLIBttrPk1Bttr3Tmprtr : 16|8@1+ (1,-40) [-40|210] "degC" Vector__XXX

BO_ 2566653950 VEP10: 8 Vector__XXX
 SG_ SLIBatteryPack1Battery2Capacity : 16|16@1+ (1,0) [0|64255] "Ah" Vector__XXX
 SG_ SLIBatteryPack1Battery2Health : 32|8@1+ (0.5,0) [0|125] "%" Vector__XXX
 SG_ SLIBttP1Btt2PdtdMCVt : 40|8@1+ (0.2,0) [0|50] "V" Vector__XXX
 SG_ SLIBttrPk1Bttr2SttfChrg : 0|16@1+ (0.0025,0) [0|160.6375] "%" Vector__XXX
 SG_ SLIBttrPk1Snsr2IntlztnStts : 48|4@1+ (1,0) [0|15] "" Vector__XXX

BO_ 2566654206 VEP9: 8 Vector__XXX
 SG_ SLIBatteryPack1Battery2Voltage : 24|16@1+ (0.05,0) [0|3212.75] "V" Vector__XXX
 SG_ SLIBttrPk1Bttr2NtCrrnt : 0|16@1+ (0.05,-1600) [-1600|1612.75] "A" Vector__XXX
 SG_ SLIBttrPk1Bttr2Tmprtr : 16|8@1+ (1,-40) [-40|210] "degC" Vector__XXX

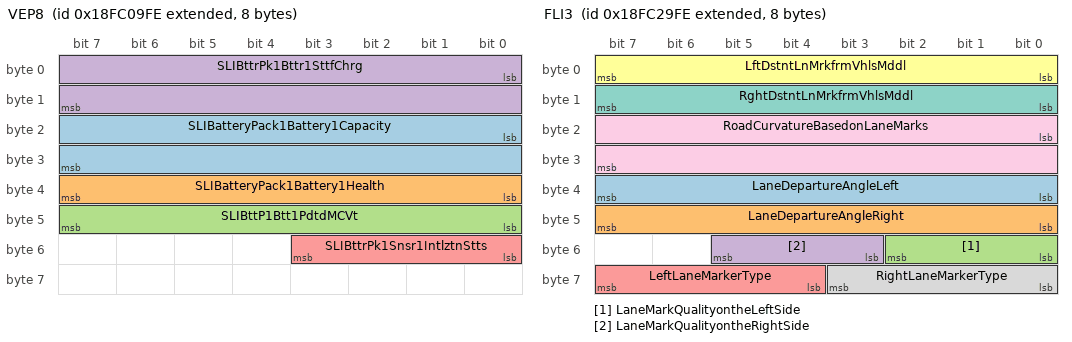
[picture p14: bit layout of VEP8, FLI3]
BO_ 2566654462 VEP8: 8 Vector__XXX
 SG_ SLIBatteryPack1Battery1Capacity : 16|16@1+ (1,0) [0|64255] "Ah" Vector__XXX
 SG_ SLIBatteryPack1Battery1Health : 32|8@1+ (0.5,0) [0|125] "%" Vector__XXX
 SG_ SLIBttP1Btt1PdtdMCVt : 40|8@1+ (0.2,0) [0|50] "V" Vector__XXX
 SG_ SLIBttrPk1Bttr1SttfChrg : 0|16@1+ (0.0025,0) [0|160.6375] "%" Vector__XXX
 SG_ SLIBttrPk1Snsr1IntlztnStts : 48|4@1+ (1,0) [0|15] "" Vector__XXX

BO_ 2566654718 VEP7: 8 Vector__XXX
 SG_ SLIBatteryPack1Battery1Voltage : 24|16@1+ (0.05,0) [0|3212.75] "V" Vector__XXX
 SG_ SLIBttrPk1Bttr1NtCrrnt : 0|16@1+ (0.05,-1600) [-1600|1612.75] "A" Vector__XXX
 SG_ SLIBttrPk1Bttr1Tmprtr : 16|8@1+ (1,-40) [-40|210] "degC" Vector__XXX

BO_ 2566654974 EEC20: 8 Vector__XXX
 SG_ AtlMxmmAvllEngnPrntFl : 16|8@1+ (0.4,0) [0|100] "%" Vector__XXX
 SG_ EsttdEPstLsssPtTqHRst : 0|16@1+ (0.0015625,0) [0|100.3984375] "%" Vector__XXX
 SG_ NmnlFrtnPrntTrqHghRsltn : 24|16@1+ (0.0015625,0) [0|100.3984375] "%" Vector__XXX

BO_ 2566655742 PHRPS: 8 Vector__XXX
 SG_ RearHitchPitchSensitivity : 8|8@1+ (0.4,0) [0|100] "%" Vector__XXX
 SG_ RearHitchRollSensitivity : 0|8@1+ (0.4,0) [0|100] "%" Vector__XXX

BO_ 2566656254 AMB3: 8 Vector__XXX
 SG_ BarometricAbsolutePressure2 : 0|16@1+ (0.1,0) [0|6425.5] "kPa" Vector__XXX
 SG_ EngineIntake2AirTemperature : 16|8@1+ (1,-40) [-40|210] "degC" Vector__XXX
 SG_ EngnPwrDrtRltvHmdtDffrn : 24|16@1+ (0.01,-321.27) [-321.27|321.28] "%" Vector__XXX

BO_ 2566656510 TGFI: 8 Vector__XXX
 SG_ EngnTtlGssFlVlmUsd : 0|32@1+ (0.5,0) [0|2105540607.5] "m*m*m" Vector__XXX
 SG_ EngnTtlGssIdlFlVlmUsd : 32|32@1+ (0.5,0) [0|2105540607.5] "m*m*m" Vector__XXX

BO_ 2566658302 PLST2: 8 Vector__XXX
 SG_ TotalPayloadTransactionCount : 0|32@1+ (1,0) [0|4211081215] "count" Vector__XXX

BO_ 2566658558 PLST1: 8 Vector__XXX
 SG_ TotalDeliveredPayloadWeight : 0|32@1+ (100,0) [0|421108121500] "kg" Vector__XXX
 SG_ TotalHaulCycleCount : 32|32@1+ (1,0) [0|4211081215] "count" Vector__XXX

BO_ 2566661118 LFC2: 8 Vector__XXX
 SG_ EngineTotalDieselFuelDemand : 0|32@1+ (0.5,0) [0|2105540607.5] "l" Vector__XXX

BO_ 2566661374 AT2T1I2: 8 Vector__XXX
 SG_ Aftrtrtmnt2DslExhstFldTnkHtr2 : 16|8@1+ (0.4,0) [0|100] "%" Vector__XXX
 SG_ Aftrtrtmnt2DslExhstFldTnkVlm2 : 0|8@1+ (0.4,0) [0|100] "%" Vector__XXX
 SG_ Atttt2DsExstFdTTpt2 : 8|8@1+ (1,-40) [-40|210] "degC" Vector__XXX

BO_ 2566661630 AT1T1I2: 8 Vector__XXX
 SG_ Aftrtrtmnt1DslExhstFldTnkHtr2 : 16|8@1+ (0.4,0) [0|100] "%" Vector__XXX
 SG_ Aftrtrtmnt1DslExhstFldTnkVlm2 : 0|8@1+ (0.4,0) [0|100] "%" Vector__XXX
 SG_ Atttt1DsExstFdTTpt2 : 8|8@1+ (1,-40) [-40|210] "degC" Vector__XXX

BO_ 2566661886 A2DEFI2: 8 Vector__XXX
 SG_ Atttt2DsExstFdCt2Tpt : 8|8@1+ (1,-40) [-40|210] "degC" Vector__XXX
 SG_ Atttt2DsExstFdCtTpt : 0|8@1+ (1,-40) [-40|210] "degC" Vector__XXX

BO_ 2566662142 A1DEFI2: 8 Vector__XXX
 SG_ Atttt1DsExstFdCt1Tpt : 0|8@1+ (1,-40) [-40|210] "degC" Vector__XXX
 SG_ Atttt1DsExstFdCt2Tpt : 8|8@1+ (1,-40) [-40|210] "degC" Vector__XXX

BO_ 2566662654 FLI3: 8 Vector__XXX
 SG_ LaneDepartureAngleLeft : 32|8@1+ (0.1,-12.5) [-12.5|12.5] "deg" Vector__XXX
 SG_ LaneDepartureAngleRight : 40|8@1+ (0.1,-12.5) [-12.5|12.5] "deg" Vector__XXX
 SG_ LaneMarkQualityontheLeftSide : 48|3@1+ (1,0) [0|7] "" Vector__XXX
 SG_ LaneMarkQualityontheRightSide : 51|3@1+ (1,0) [0|7] "" Vector__XXX
 SG_ LeftLaneMarkerType : 60|4@1+ (1,0) [0|15] "" Vector__XXX
 SG_ LftDstntLnMrkfrmVhlsMddl : 0|8@1+ (0.02,0) [0|5] "m" Vector__XXX
 SG_ RghtDstntLnMrkfrmVhlsMddl : 8|8@1+ (0.02,0) [0|5] "m" Vector__XXX
 SG_ RightLaneMarkerType : 56|4@1+ (1,0) [0|15] "" Vector__XXX
 SG_ RoadCurvatureBasedonLaneMarks : 16|16@1+ (0.0078125,-250) [-250|251.992] "1/km" Vector__XXX

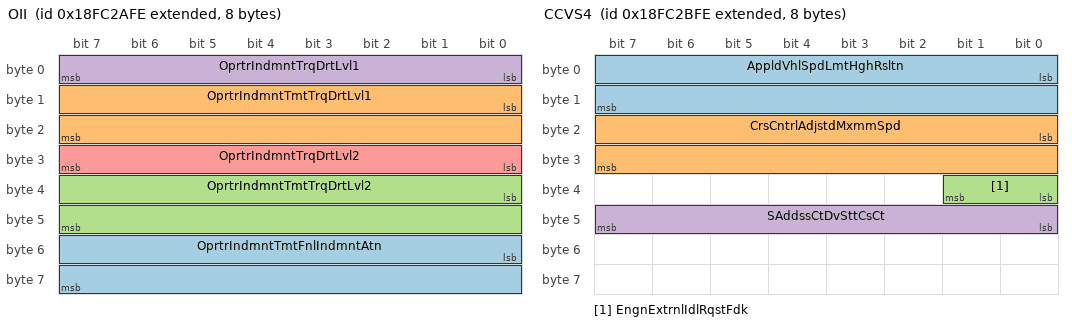
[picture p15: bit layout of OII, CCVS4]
BO_ 2566662910 OII: 8 Vector__XXX
 SG_ OprtrIndmntTmtFnlIndmntAtn : 48|16@1+ (1,0) [0|64255] "min" Vector__XXX
 SG_ OprtrIndmntTmtTrqDrtLvl1 : 8|16@1+ (1,0) [0|64255] "min" Vector__XXX
 SG_ OprtrIndmntTmtTrqDrtLvl2 : 32|16@1+ (1,0) [0|64255] "min" Vector__XXX
 SG_ OprtrIndmntTrqDrtLvl1 : 0|8@1+ (1,0) [0|250] "%" Vector__XXX
 SG_ OprtrIndmntTrqDrtLvl2 : 24|8@1+ (1,0) [0|250] "%" Vector__XXX

BO_ 2566663166 CCVS4: 8 Vector__XXX
 SG_ AppldVhlSpdLmtHghRsltn : 0|16@1+ (0.00390625,0) [0|250.996] "km/h" Vector__XXX
 SG_ CrsCntrlAdjstdMxmmSpd : 16|16@1+ (0.00390625,0) [0|250.996] "km/h" Vector__XXX
 SG_ EngnExtrnlIdlRqstFdk : 32|2@1+ (1,0) [0|3] "" Vector__XXX
 SG_ SAddssCtDvSttCsCt : 40|8@1+ (1,0) [0|255] "SA" Vector__XXX

BO_ 2566663422 BCLC: 8 Vector__XXX
 SG_ TrlrBrkClprLnngClrnAxl1Lft : 20|2@1+ (1,0) [0|3] "" Vector__XXX
 SG_ TrlrBrkClprLnngClrnAxl1Rght : 22|2@1+ (1,0) [0|3] "" Vector__XXX
 SG_ TrlrBrkClprLnngClrnAxl2Lft : 24|2@1+ (1,0) [0|3] "" Vector__XXX
 SG_ TrlrBrkClprLnngClrnAxl2Rght : 26|2@1+ (1,0) [0|3] "" Vector__XXX
 SG_ TrlrBrkClprLnngClrnAxl3Lft : 28|2@1+ (1,0) [0|3] "" Vector__XXX
 SG_ TrlrBrkClprLnngClrnAxl3Rght : 30|2@1+ (1,0) [0|3] "" Vector__XXX
 SG_ TrlrBrkClprLnngClrnAxl4Lft : 32|2@1+ (1,0) [0|3] "" Vector__XXX
 SG_ TrlrBrkClprLnngClrnAxl4Rght : 34|2@1+ (1,0) [0|3] "" Vector__XXX
 SG_ TrlrBrkClprLnngClrnAxl5Lft : 36|2@1+ (1,0) [0|3] "" Vector__XXX
 SG_ TrlrBrkClprLnngClrnAxl5Rght : 38|2@1+ (1,0) [0|3] "" Vector__XXX
 SG_ TrtrBrkClprLnngClrnAxl1Lft : 0|2@1+ (1,0) [0|3] "" Vector__XXX
 SG_ TrtrBrkClprLnngClrnAxl1Rght : 2|2@1+ (1,0) [0|3] "" Vector__XXX
 SG_ TrtrBrkClprLnngClrnAxl2Lft : 4|2@1+ (1,0) [0|3] "" Vector__XXX
 SG_ TrtrBrkClprLnngClrnAxl2Rght : 6|2@1+ (1,0) [0|3] "" Vector__XXX
 SG_ TrtrBrkClprLnngClrnAxl3Lft : 8|2@1+ (1,0) [0|3] "" Vector__XXX
 SG_ TrtrBrkClprLnngClrnAxl3Rght : 10|2@1+ (1,0) [0|3] "" Vector__XXX
 SG_ TrtrBrkClprLnngClrnAxl4Lft : 12|2@1+ (1,0) [0|3] "" Vector__XXX
 SG_ TrtrBrkClprLnngClrnAxl4Rght : 14|2@1+ (1,0) [0|3] "" Vector__XXX
 SG_ TrtrBrkClprLnngClrnAxl5Lft : 16|2@1+ (1,0) [0|3] "" Vector__XXX
 SG_ TrtrBrkClprLnngClrnAxl5Rght : 18|2@1+ (1,0) [0|3] "" Vector__XXX

BO_ 2566663678 AF5: 8 Vector__XXX
 SG_ EngnFl2InjtrMtrngRl1Tmprtr2 : 32|8@1+ (1,-40) [-40|210] "degC" Vector__XXX
 SG_ LNGTank1VaporPressure : 0|16@1+ (0.1,0) [0|6425.5] "kPa" Vector__XXX
 SG_ LNGTank2VaporPressure : 16|16@1+ (0.1,0) [0|6425.5] "kPa" Vector__XXX

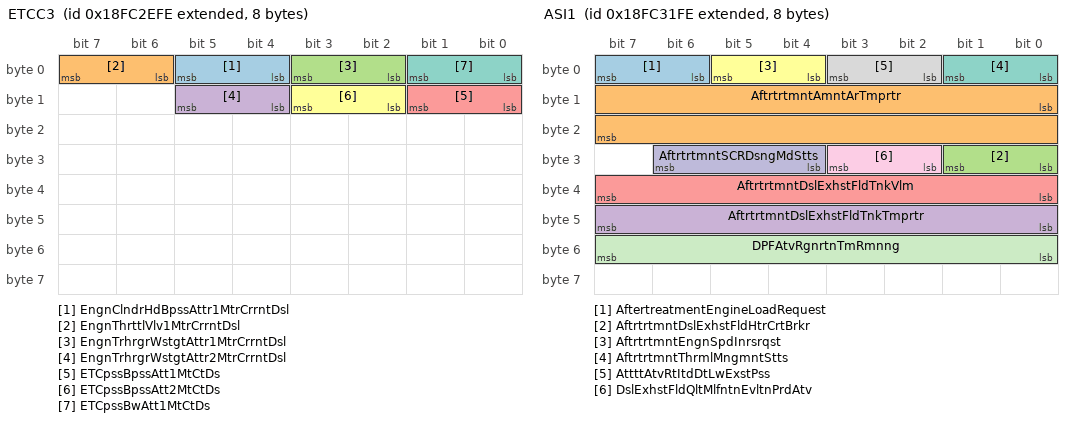
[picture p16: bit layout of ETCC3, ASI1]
BO_ 2566663934 ETCC3: 8 Vector__XXX
 SG_ EngnClndrHdBpssAttr1MtrCrrntDsl : 4|2@1+ (1,0) [0|3] "" Vector__XXX
 SG_ EngnThrttlVlv1MtrCrrntDsl : 6|2@1+ (1,0) [0|3] "" Vector__XXX
 SG_ EngnTrhrgrWstgtAttr1MtrCrrntDsl : 2|2@1+ (1,0) [0|3] "" Vector__XXX
 SG_ EngnTrhrgrWstgtAttr2MtrCrrntDsl : 12|2@1+ (1,0) [0|3] "" Vector__XXX
 SG_ ETCpssBpssAtt1MtCtDs : 8|2@1+ (1,0) [0|3] "" Vector__XXX
 SG_ ETCpssBpssAtt2MtCtDs : 10|2@1+ (1,0) [0|3] "" Vector__XXX
 SG_ ETCpssBwAtt1MtCtDs : 0|2@1+ (1,0) [0|3] "" Vector__XXX

BO_ 2566664702 ASI1: 8 Vector__XXX
 SG_ AftertreatmentEngineLoadRequest : 6|2@1+ (1,0) [0|3] "" Vector__XXX
 SG_ AftrtrtmntAmntArTmprtr : 8|16@1+ (0.03125,-273) [-273|1734.96875] "degC" Vector__XXX
 SG_ AftrtrtmntDslExhstFldHtrCrtBrkr : 24|2@1+ (1,0) [0|3] "" Vector__XXX
 SG_ AftrtrtmntDslExhstFldTnkTmprtr : 40|8@1+ (1,-40) [-40|210] "degC" Vector__XXX
 SG_ AftrtrtmntDslExhstFldTnkVlm : 32|8@1+ (0.4,0) [0|100] "%" Vector__XXX
 SG_ AftrtrtmntEngnSpdInrsrqst : 4|2@1+ (1,0) [0|3] "" Vector__XXX
 SG_ AftrtrtmntThrmlMngmntStts : 0|2@1+ (1,0) [0|3] "" Vector__XXX
 SG_ AttttAtvRtItdDtLwExstPss : 2|2@1+ (1,0) [0|3] "" Vector__XXX
 SG_ DslExhstFldQltMlfntnEvltnPrdAtv : 26|2@1+ (1,0) [0|3] "" Vector__XXX
 SG_ AftrtrtmntSCRDsngMdStts : 28|3@1+ (1,0) [0|7] "" Vector__XXX
 SG_ DPFAtvRgnrtnTmRmnng : 48|8@1+ (1,0) [0|250] "min" Vector__XXX

BO_ 2566665726 AT2P1I: 8 Vector__XXX
 SG_ Aftrtrtmnt2DslExhstFldPmpHtr : 0|8@1+ (0.4,0) [0|100] "%" Vector__XXX
 SG_ Atttt2DsExstFdPp2MtSpd : 8|16@1+ (0.5,0) [0|32127.5] "rpm" Vector__XXX

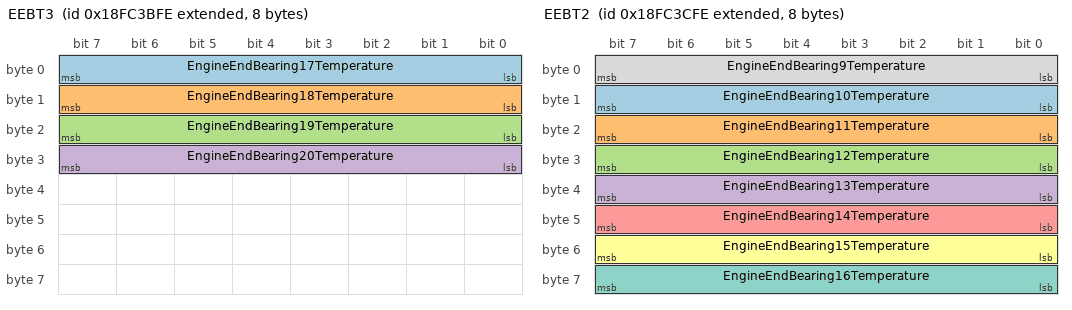
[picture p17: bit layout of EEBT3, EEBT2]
BO_ 2566667262 EEBT3: 8 Vector__XXX
 SG_ EngineEndBearing17Temperature : 0|8@1+ (1,-40) [-40|210] "degC" Vector__XXX
 SG_ EngineEndBearing18Temperature : 8|8@1+ (1,-40) [-40|210] "degC" Vector__XXX
 SG_ EngineEndBearing19Temperature : 16|8@1+ (1,-40) [-40|210] "degC" Vector__XXX
 SG_ EngineEndBearing20Temperature : 24|8@1+ (1,-40) [-40|210] "degC" Vector__XXX

BO_ 2566667518 EEBT2: 8 Vector__XXX
 SG_ EngineEndBearing10Temperature : 8|8@1+ (1,-40) [-40|210] "degC" Vector__XXX
 SG_ EngineEndBearing11Temperature : 16|8@1+ (1,-40) [-40|210] "degC" Vector__XXX
 SG_ EngineEndBearing12Temperature : 24|8@1+ (1,-40) [-40|210] "degC" Vector__XXX
 SG_ EngineEndBearing13Temperature : 32|8@1+ (1,-40) [-40|210] "degC" Vector__XXX
 SG_ EngineEndBearing14Temperature : 40|8@1+ (1,-40) [-40|210] "degC" Vector__XXX
 SG_ EngineEndBearing15Temperature : 48|8@1+ (1,-40) [-40|210] "degC" Vector__XXX
 SG_ EngineEndBearing16Temperature : 56|8@1+ (1,-40) [-40|210] "degC" Vector__XXX
 SG_ EngineEndBearing9Temperature : 0|8@1+ (1,-40) [-40|210] "degC" Vector__XXX

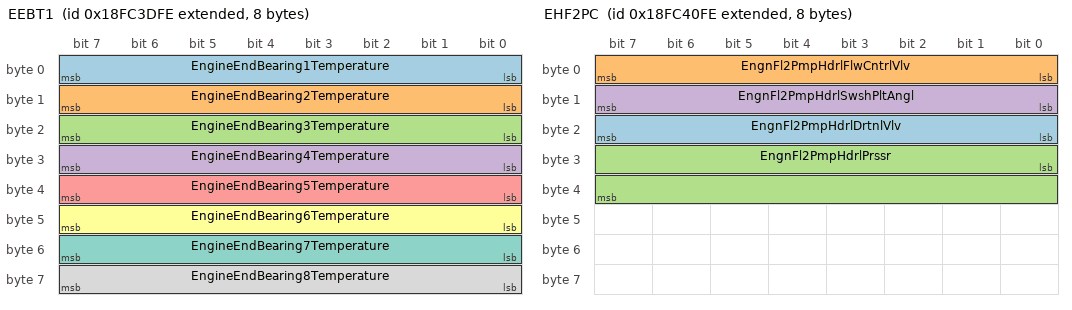
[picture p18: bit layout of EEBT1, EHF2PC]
BO_ 2566667774 EEBT1: 8 Vector__XXX
 SG_ EngineEndBearing1Temperature : 0|8@1+ (1,-40) [-40|210] "degC" Vector__XXX
 SG_ EngineEndBearing2Temperature : 8|8@1+ (1,-40) [-40|210] "degC" Vector__XXX
 SG_ EngineEndBearing3Temperature : 16|8@1+ (1,-40) [-40|210] "degC" Vector__XXX
 SG_ EngineEndBearing4Temperature : 24|8@1+ (1,-40) [-40|210] "degC" Vector__XXX
 SG_ EngineEndBearing5Temperature : 32|8@1+ (1,-40) [-40|210] "degC" Vector__XXX
 SG_ EngineEndBearing6Temperature : 40|8@1+ (1,-40) [-40|210] "degC" Vector__XXX
 SG_ EngineEndBearing7Temperature : 48|8@1+ (1,-40) [-40|210] "degC" Vector__XXX
 SG_ EngineEndBearing8Temperature : 56|8@1+ (1,-40) [-40|210] "degC" Vector__XXX

BO_ 2566668030 HEDPI: 8 Vector__XXX
 SG_ HeatExchangerDebrisPurgeStatus : 0|2@1+ (1,0) [0|3] "" Vector__XXX
 SG_ HtExhngrDrsPrgApprhng : 2|2@1+ (1,0) [0|3] "" Vector__XXX

BO_ 2566668286 ETCC2: 8 Vector__XXX
 SG_ EngnStgdTrhrgrSlndStts : 0|8@1+ (0.4,0) [0|100] "%" Vector__XXX

BO_ 2566668542 EHF2PC: 8 Vector__XXX
 SG_ EngnFl2PmpHdrlDrtnlVlv : 16|8@1+ (0.4,0) [0|100] "%" Vector__XXX
 SG_ EngnFl2PmpHdrlFlwCntrlVlv : 0|8@1+ (0.4,0) [0|100] "%" Vector__XXX
 SG_ EngnFl2PmpHdrlPrssr : 24|16@1+ (2,0) [0|128510] "kPa" Vector__XXX
 SG_ EngnFl2PmpHdrlSwshPltAngl : 8|8@1+ (0.4,0) [0|100] "%" Vector__XXX

BO_ 2566668798 AF4: 8 Vector__XXX
 SG_ EngnFl2InjtrMtrngRl1Prssr : 0|16@1+ (2,0) [0|128510] "kPa" Vector__XXX
 SG_ EngnFl2InjtrMtrngRl1Prssr2 : 48|16@1+ (2,0) [0|128510] "kPa" Vector__XXX
 SG_ EngnFl2InjtrMtrngRl1Tmprtr : 32|8@1+ (1,-40) [-40|210] "degC" Vector__XXX
 SG_ EngnFl2InjtrMtrngRl2Prssr : 16|16@1+ (2,0) [0|128510] "kPa" Vector__XXX
 SG_ EngnFl2InjtrMtrngRl2Tmprtr : 40|8@1+ (1,-40) [-40|210] "degC" Vector__XXX

BO_ 2566669054 TIRE2: 8 Vector__XXX
 SG_ RequiredTirePressure : 24|16@1+ (1,0) [0|64255] "kPa" Vector__XXX
 SG_ TireLocation : 0|8@1+ (8,0) [0|0] "bit-mapped" Vector__XXX
 SG_ TirePressureExtendedRange : 8|16@1+ (1,0) [0|64255] "kPa" Vector__XXX

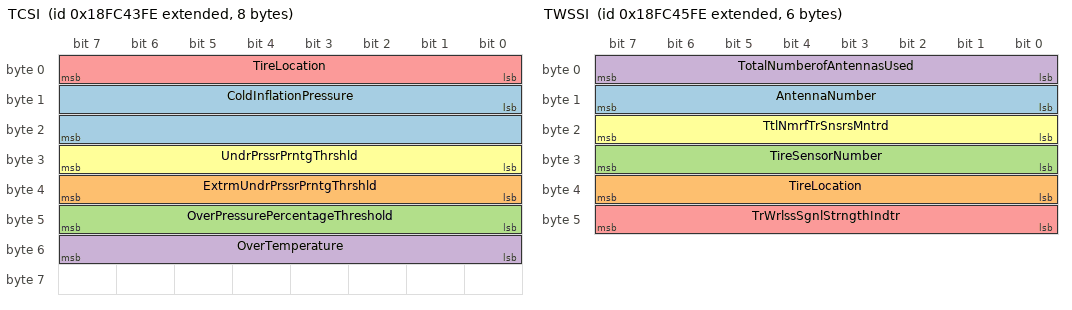
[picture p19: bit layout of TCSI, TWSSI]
BO_ 2566669310 TCSI: 8 Vector__XXX
 SG_ ColdInflationPressure : 8|16@1+ (1,0) [0|64255] "kPa" Vector__XXX
 SG_ ExtrmUndrPrssrPrntgThrshld : 32|8@1+ (0.5,0) [0|125] "%" Vector__XXX
 SG_ OverPressurePercentageThreshold : 40|8@1+ (0.5,0) [0|125] "%" Vector__XXX
 SG_ OverTemperature : 48|8@1+ (1,-40) [-40|210] "degC" Vector__XXX
 SG_ TireLocation : 0|8@1+ (8,0) [0|0] "bit-mapped" Vector__XXX
 SG_ UndrPrssrPrntgThrshld : 24|8@1+ (0.5,0) [0|125] "%" Vector__XXX

BO_ 2566669822 TWSSI: 6 Vector__XXX
 SG_ AntennaNumber : 8|8@1+ (1,0) [0|250] "count" Vector__XXX
 SG_ TireLocation : 32|8@1+ (8,0) [0|0] "bit-mapped" Vector__XXX
 SG_ TireSensorNumber : 24|8@1+ (1,0) [0|250] "count" Vector__XXX
 SG_ TotalNumberofAntennasUsed : 0|8@1+ (1,0) [0|250] "count" Vector__XXX
 SG_ TrWrlssSgnlStrngthIndtr : 40|8@1+ (0.5,-125) [-125|0] "dBm" Vector__XXX
 SG_ TtlNmrfTrSnsrsMntrd : 16|8@1+ (1,0) [0|250] "count" Vector__XXX

BO_ 2566670078 TSIS: 200 Vector__XXX
 SG_ NumberofTireSensors : 0|8@1+ (1,0) [0|250] "count" Vector__XXX
 SG_ TireLocation : 16|8@1+ (1,0) [0|255] "count" Vector__XXX
 SG_ TireNumber : 8|8@1+ (1,0) [0|250] "count" Vector__XXX
 SG_ TireSensorIdentificationNumber : 24|8@1+ (1,0) [0|255] "ASCII" Vector__XXX

CM_ BO_ 2566631678 "DC/AC Accessory Inverter 5 Configuration 1";
CM_ SG_ 2566631678 DCACAssIvt5ACSdDtFqCdStt "DC/AC Accessory Inverter 5 AC Side Default Frequency Command Setting: Reports the active AC Side Default Frequency Command Setting of the DC/AC Accessory Inverter.  The setting may be requested by a separate device (via SPN 9527).Note: Report Not Ava...";
CM_ SG_ 2566631678 DCACAssIvt5ACSdRMSCtMxLtStt "DC/AC Accessory Inverter 5 AC Side RMS Current Maximum Limit Setting: Reports the active maximum limit on the AC side output RMS line current of the DC/AC Accessory Inverter.  The setting may be requested by a separate device (via SPN 9360) or determ...";
CM_ SG_ 2566631678 DCACAssIvt5ACSdRMSVtMxLtStt "DC/AC Accessory Inverter 5 AC Side RMS Voltage Maximum Limit Setting: Reports the active maximum limit on the AC Side output line to line RMS voltage of the DC/AC Accessory Inverter.  The setting may be requested by a separate device (via SPN 9359) o...";
CM_ SG_ 2566631678 DCACAssIvt5DCSdCtMLtStt "DC/AC Accessory Inverter 5 DC Side Current Minimum Limit Setting: Reports the active minimum limit on the DC Side input current of the DC/AC Accessory Inverter.  The setting may be requested by a separate device (via SPN 9554) or determined by the DC...";
CM_ SG_ 2566631678 DCACAssIvt5DCSdCtMxLtStt "DC/AC Accessory Inverter 5 DC Side Current Maximum Limit Setting: Reports the active maximum limit on the DC Side input current of the DC/AC Accessory Inverter.  The setting may be requested by a separate device (via SPN 9358) or determined by the DC...";
CM_ SG_ 2566631678 DCACAssIvt5DCSdVtMLtStt "DC/AC Accessory Inverter 5 DC Side Voltage Minimum Limit Setting: Reports the active minimum limit on the DC Side input voltage of the DC/AC Accessory Inverter.  The setting may be requested by a separate device (via SPN 9357) or determined by the DC...";
CM_ SG_ 2566631678 DCACAssIvt5DCSdVtMxLtStt "DC/AC Accessory Inverter 5 DC Side Voltage Maximum Limit Setting: Reports the active maximum limit on the DC Side input voltage of the DC/AC Accessory Inverter.  The setting may be requested by a separate device (via SPN 9553) or determined by the DC...";
CM_ BO_ 2566631934 "DC/AC Accessory Inverter 5 Lifetime Data";
CM_ SG_ 2566631934 DCACAssrInvrtr5TtlDCInptChrg "DC/AC Accessory Inverter 5 Total DC Input Charge : Total lifetime charge converted by the DC/AC from the DC Side.  ";
CM_ SG_ 2566631934 DCACAssrInvrtr5TtlDCInptEnrg "DC/AC Accessory Inverter 5 Total DC Input Energy : Total lifetime energy converted by the DC/AC from the DC Side.";
CM_ BO_ 2566632190 "Well Stimulation Pump Sensor Calibration Status";
CM_ SG_ 2566632190 WllStmltnPmpStnPrssrClrtnStPnt "Well Stimulation Pump Suction Pressure Calibration Set Point: Specifies the current suction pressure whose calibration status is being reported. Multipoint calibration of the suction pressure system is performed by increasing the pressure with up to ...";
CM_ SG_ 2566632190 WSttPpDsPssCtStPt "Well Stimulation Pump Discharge Pressure Calibration Set Point: Specifies the current discharge pressure whose calibration status is being reported. Multipoint calibration of the discharge pressure system is performed by increasing the pressure with ...";
CM_ SG_ 2566632190 WSttPpDsPssCtStPtStts "Well Stimulation Pump Discharge Pressure Calibration Set Point Status: Indicates the state of the Calibrated Sensor.00b = Not OK01b = OK10b = Error11b = Not available";
CM_ SG_ 2566632190 WSttPpStPssCtStPtStts "Well Stimulation Pump Suction Pressure Calibration Set Point Status: Indicates the state of the Calibrated Sensor.00b = Not OK01b = OK10b = Error11b = Not available";
CM_ BO_ 2566632446 "Well Stimulation Pump Fluid Volume";
CM_ SG_ 2566632446 WllStmltnPmpTrpFldPmpd "Well Stimulation Pump Trip Fluid Pumped: Fluid pumped during all or part of a well stimulation operation.";
CM_ SG_ 2566632446 WllStmltnPmpTtlFldPmpd "Well Stimulation Pump Total Fluid Pumped: Accumulated amount of fluid pumped during well stimulation operation.";
CM_ BO_ 2566632702 "Well Stimulation Pump Serial Number";
CM_ SG_ 2566632702 WllStmltnPmpFldEndSrlNmr "Well Stimulation Pump Fluid End Serial Number: The serial number of the fluid end of a well stimulation pump.";
CM_ SG_ 2566632702 WllStmltnPmpPwrEndSrlNmr "Well Stimulation Pump Power End Serial Number: The serial number of the power end of a well stimulation pump.";
CM_ BO_ 2566632958 "Well Stimulation Pump Trip Hours";
CM_ SG_ 2566632958 WllStmltnPmpFldEndTrpHrs "Well Stimulation Pump Fluid End Trip Hours: The hours accumulated since the last fluid end replacement on the well stimulation pump (since the last reset of the trip meter).This value will be reset by the user.";
CM_ SG_ 2566632958 WllStmltnPmpPwrEndTrpHrs "Well Stimulation Pump Power End Trip Hours: The hours accumulated since the last power end replacement on the well stimulation pump (since the last reset of the trip meter).This value will be reset by the user.";
CM_ BO_ 2566633214 "Aftertreatment 1 Outlet Gas 4";
CM_ SG_ 2566633214 Aftrtrtmnt1OtltOxgnPmpngCrrnt "Aftertreatment 1 Outlet Oxygen Pumping Current: Electrical pumping current directly measured from a Lambda sensor for the purpose of calculating an air/fuel ratio.  This sensor is located closest to the outlet of aftertreatment 1 system.Negative elec...";
CM_ SG_ 2566633214 Atttt1OttNOxSsPttAPssAst "Aftertreatment 1 Outlet NOx Sensor Protection Air Pressure (Absolute): The absolute pressure of the air supplied for the outlet NOx sensor protection of aftertreatment 1.";
CM_ BO_ 2566633470 "Aftertreatment 1 Intake Gas 4";
CM_ SG_ 2566633470 Aftrtrtmnt1IntkOxgnPmpngCrrnt "Aftertreatment 1 Intake Oxygen Pumping Current: Electrical pumping current directly measured from a Lambda sensor for the purpose of calculating an air/fuel ratio.  This sensor is located furthest upstream of the intake of aftertreatment 1 system.Neg...";
CM_ SG_ 2566633470 Atttt1ItNOxSsPttAPssAst "Aftertreatment 1 Intake NOx Sensor Protection Air Pressure (Absolute): The absolute pressure of the air supplied for the intake NOx sensor protection of aftertreatment 1.";
CM_ BO_ 2566633726 "DC/DC Converter 4 Lifetime Data";
CM_ SG_ 2566633726 DCDC4TotalHighSideCharge "DC/DC 4 Total High Side Charge: Indicates the total lifetime charge converted by the DC/DC from the high side (e.g. HVES) during buck mode.  ";
CM_ SG_ 2566633726 DCDC4TotalHighSideEnergy "DC/DC 4 Total High Side Energy: Indicates the total lifetime energy converted by the DC/DC from the high side (e.g. HVES) during buck mode.";
CM_ SG_ 2566633726 DCDC4TotalLowSideCharge "DC/DC 4 Total Low Side Charge: Indicates the total lifetime charge converted by the DC/DC  from the low side (e.g. SLI battery) during boost mode.";
CM_ SG_ 2566633726 DCDC4TotalLowSideEnergy "DC/DC 4 Total Low Side Energy: Indicates the total lifetime energy converted by the DC/DC  from the low side (e.g. SLI battery) during boost mode.";
CM_ BO_ 2566633982 "DC/DC Converter 4 Configuration 1";
CM_ SG_ 2566633982 DCDC4HghSdCrrntMxmmLmtSttng "DC/DC 4 High Side Current Maximum Limit Setting: Reports the active maximum limit on the high side current of the DC/DC Converter.  The setting may be requested by a separate device (see SPN 9056) or determined by the DC/DC Controller based on operat...";
CM_ SG_ 2566633982 DCDC4HghSdVltgMnmmLmtSttng "DC/DC 4 High Side Voltage Minimum Limit Setting: Reports the active minimum limit on the high side voltage of the DC/DC Converter.  The setting may be requested by a separate device (see SPN 9054) or determined by the DC/DC Controller based on operat...";
CM_ SG_ 2566633982 DCDC4HghSdVltgMxmmLmtSttng "DC/DC 4 High Side Voltage Maximum Limit Setting: Reports the active maximum limit on the high side voltage of the DC/DC Converter.  The setting may be requested by a separate device (see SPN 9055) or determined by the DC/DC Controller based on operat...";
CM_ SG_ 2566633982 DCDC4LwSdCrrntMxmmLmtSttng "DC/DC 4 Low Side Current Maximum Limit Setting: Reports the active maximum limit on the low side current of the DC/DC Converter.  The setting may be requested by a separate device (see SPN 9053) or determined by the DC/DC Controller based on operatin...";
CM_ SG_ 2566633982 DCDC4LwSdVltgBkDfltSttng "DC/DC 4 Low Side Voltage Buck Default Setting: Reports the converter active Low Side Voltage Buck Default Setting.  The default may be requested by a separate device (via SPN 9518).Note: Report Not Available (FFFFh) when no default has been set.";
CM_ SG_ 2566633982 DCDC4LwSdVltgMnmmLmtSttng "DC/DC 4 Low Side Voltage Minimum Limit Setting: Reports the active minimum limit on the low side voltage of the DC/DC Converter.  The setting may be requested by a separate device(see SPN 9051) or determined by the DC/DC Controller based on operating...";
CM_ SG_ 2566633982 DCDC4LwSdVltgMxmmLmtSttng "DC/DC 4 Low Side Voltage Maximum Limit Setting: Reports the active maximum limit on the low side voltage of the DC/DC Converter.  The setting may be requested by a separate device (see SPN 9052) or determined by the DC/DC Controller based on operatin...";
CM_ SG_ 2566633982 DCDC4SLIBttrTmprtrMxmmLmtSttng "DC/DC 4 SLI Battery Temperature Maximum Limit Setting: Reports the active SLI Battery Temperature maximum limit.  The setting may be requested by a separate device (see SPN 9045) or determined by the DC/DC Controller based on operating conditions.";
CM_ SG_ 2566633982 DCDC4SLIBttTCCtMxLtStt "DC/DC 4 SLI Battery Terminal Charge Current Maximum Limit Setting: Reports the active SLI Battery charging current maximum limit (at the battery terminals).  The setting may be requested by a separate device (see SPN 9044) or determined by the DC/DC ...";
CM_ SG_ 2566633982 DCDC4SLIBttTVtMxLtStt "DC/DC 4 SLI Battery Terminal Voltage Maximum Limit Setting: Reports the active SLI Battery Voltage maximum limit (at the battery terminals).  The setting may be requested by a separate device (see SPN 9043) or determined by the DC/DC Controller based...";
CM_ BO_ 2566635262 "DC/DC Converter 3 Lifetime Data";
CM_ SG_ 2566635262 DCDC3TotalHighSideCharge "DC/DC 3 Total High Side Charge: Indicates the total lifetime charge converted by the DC/DC from the high side (e.g. HVES) during buck mode.  ";
CM_ SG_ 2566635262 DCDC3TotalHighSideEnergy "DC/DC 3 Total High Side Energy: Indicates the total lifetime energy converted by the DC/DC from the high side (e.g. HVES) during buck mode.";
CM_ SG_ 2566635262 DCDC3TotalLowSideCharge "DC/DC 3 Total Low Side Charge: Indicates the total lifetime charge converted by the DC/DC  from the low side (e.g. SLI battery) during boost mode.";
CM_ SG_ 2566635262 DCDC3TotalLowSideEnergy "DC/DC 3 Total Low Side Energy: Indicates the total lifetime energy converted by the DC/DC  from the low side (e.g. SLI battery) during boost mode.";
CM_ BO_ 2566635518 "DC/DC Converter 3 Configuration 1";
CM_ SG_ 2566635518 DCDC3HghSdCrrntMxmmLmtSttng "DC/DC 3 High Side Current Maximum Limit Setting: Reports the active maximum limit on the high side current of the DC/DC Converter.  The setting may be requested by a separate device (see SPN 9001) or determined by the DC/DC Controller based on operat...";
CM_ SG_ 2566635518 DCDC3HghSdVltgMnmmLmtSttng "DC/DC 3 High Side Voltage Minimum Limit Setting: Reports the active minimum limit on the high side voltage of the DC/DC Converter.  The setting may be requested by a separate device (see SPN 8999) or determined by the DC/DC Controller based on operat...";
CM_ SG_ 2566635518 DCDC3HghSdVltgMxmmLmtSttng "DC/DC 3 High Side Voltage Maximum Limit Setting: Reports the active maximum limit on the high side voltage of the DC/DC Converter.  The setting may be requested by a separate device (see SPN 9000) or determined by the DC/DC Controller based on operat...";
CM_ SG_ 2566635518 DCDC3LwSdCrrntMxmmLmtSttng "DC/DC 3 Low Side Current Maximum Limit Setting: Reports the active maximum limit on the low side current of the DC/DC Converter.  The setting may be requested by a separate device (see SPN 8998) or determined by the DC/DC Controller based on operatin...";
CM_ SG_ 2566635518 DCDC3LwSdVltgBkDfltSttng "DC/DC 3 Low Side Voltage Buck Default Setting: Reports the converter active Low Side Voltage Buck Default Setting.  The default may be requested by a separate device (via SPN 9517).Note: Report Not Available (FFFFh) when no default has been set.";
CM_ SG_ 2566635518 DCDC3LwSdVltgMnmmLmtSttng "DC/DC 3 Low Side Voltage Minimum Limit Setting: Reports the active minimum limit on the low side voltage of the DC/DC Converter.  The setting may be requested by a separate device(see SPN 8996) or determined by the DC/DC Controller based on operating...";
CM_ SG_ 2566635518 DCDC3LwSdVltgMxmmLmtSttng "DC/DC 3 Low Side Voltage Maximum Limit Setting: Reports the active maximum limit on the low side voltage of the DC/DC Converter.  The setting may be requested by a separate device (see SPN 8997) or determined by the DC/DC Controller based on operatin...";
CM_ SG_ 2566635518 DCDC3SLIBttrTmprtrMxmmLmtSttng "DC/DC 3 SLI Battery Temperature Maximum Limit Setting: Reports the active SLI Battery Temperature maximum limit.  The setting may be requested by a separate device (see SPN 8990) or determined by the DC/DC Controller based on operating conditions.";
CM_ SG_ 2566635518 DCDC3SLIBttTCCtMxLtStt "DC/DC 3 SLI Battery Terminal Charge Current Maximum Limit Setting: Reports the active SLI Battery charging current maximum limit (at the battery terminals).  The setting may be requested by a separate device (see SPN 8989) or determined by the DC/DC ...";
CM_ SG_ 2566635518 DCDC3SLIBttTVtMxLtStt "DC/DC 3 SLI Battery Terminal Voltage Maximum Limit Setting: Reports the active SLI Battery Voltage maximum limit (at the battery terminals).  The setting may be requested by a separate device (see SPN 8988) or determined by the DC/DC Controller based...";
CM_ BO_ 2566636798 "DC/DC Converter 2 Lifetime Data";
CM_ SG_ 2566636798 DCDC2TotalHighSideCharge "DC/DC 2 Total High Side Charge: Indicates the total lifetime charge converted by the DC/DC from the high side (e.g. HVES) during buck mode.  ";
CM_ SG_ 2566636798 DCDC2TotalHighSideEnergy "DC/DC 2 Total High Side Energy: Indicates the total lifetime energy converted by the DC/DC from the high side (e.g. HVES) during buck mode.";
CM_ SG_ 2566636798 DCDC2TotalLowSideCharge "DC/DC 2 Total Low Side Charge: Indicates the total lifetime charge converted by the DC/DC  from the low side (e.g. SLI battery) during boost mode.";
CM_ SG_ 2566636798 DCDC2TotalLowSideEnergy "DC/DC 2 Total Low Side Energy: Indicates the total lifetime energy converted by the DC/DC  from the low side (e.g. SLI battery) during boost mode.";
CM_ BO_ 2566637054 "DC/DC Converter 2 Configuration 1";
CM_ SG_ 2566637054 DCDC2HghSdCrrntMxmmLmtSttng "DC/DC 2 High Side Current Maximum Limit Setting: Reports the active maximum limit on the high side current of the DC/DC Converter.  The setting may be requested by a separate device (see SPN 8946) or determined by the DC/DC Controller based on operat...";
CM_ SG_ 2566637054 DCDC2HghSdVltgMnmmLmtSttng "DC/DC 2 High Side Voltage Minimum Limit Setting: Reports the active minimum limit on the high side voltage of the DC/DC Converter.  The setting may be requested by a separate device (see SPN 8944) or determined by the DC/DC Controller based on operat...";
CM_ SG_ 2566637054 DCDC2HghSdVltgMxmmLmtSttng "DC/DC 2 High Side Voltage Maximum Limit Setting: Reports the active maximum limit on the high side voltage of the DC/DC Converter.  The setting may be requested by a separate device (see SPN 8945) or determined by the DC/DC Controller based on operat...";
CM_ SG_ 2566637054 DCDC2LwSdCrrntMxmmLmtSttng "DC/DC 2 Low Side Current Maximum Limit Setting: Reports the active maximum limit on the low side current of the DC/DC Converter.  The setting may be requested by a separate device (see SPN 8943) or determined by the DC/DC Controller based on operatin...";
CM_ SG_ 2566637054 DCDC2LwSdVltgBkDfltSttng "DC/DC 2 Low Side Voltage Buck Default Setting: Reports the converter active Low Side Voltage Buck Default Setting.  The default may be requested by a separate device (via SPN 9516).Note: Report Not Available (FFFFh) when no default has been set.";
CM_ SG_ 2566637054 DCDC2LwSdVltgMnmmLmtSttng "DC/DC 2 Low Side Voltage Minimum Limit Setting: Reports the active minimum limit on the low side voltage of the DC/DC Converter.  The setting may be requested by a separate device(see SPN 8941) or determined by the DC/DC Controller based on operating...";
CM_ SG_ 2566637054 DCDC2LwSdVltgMxmmLmtSttng "DC/DC 2 Low Side Voltage Maximum Limit Setting: Reports the active maximum limit on the low side voltage of the DC/DC Converter.  The setting may be requested by a separate device (see SPN 8942) or determined by the DC/DC Controller based on operatin...";
CM_ SG_ 2566637054 DCDC2SLIBttrTmprtrMxmmLmtSttng "DC/DC 2 SLI Battery Temperature Maximum Limit Setting: Reports the active SLI Battery Temperature maximum limit.  The setting may be requested by a separate device (see SPN 8935) or determined by the DC/DC Controller based on operating conditions.";
CM_ SG_ 2566637054 DCDC2SLIBttTCCtMxLtStt "DC/DC 2 SLI Battery Terminal Charge Current Maximum Limit Setting: Reports the active SLI Battery charging current maximum limit (at the battery terminals).  The setting may be requested by a separate device (see SPN 8934) or determined by the DC/DC ...";
CM_ SG_ 2566637054 DCDC2SLIBttTVtMxLtStt "DC/DC 2 SLI Battery Terminal Voltage Maximum Limit Setting: Reports the active SLI Battery Voltage maximum limit (at the battery terminals).  The setting may be requested by a separate device (see SPN 8933) or determined by the DC/DC Controller based...";
CM_ BO_ 2566638590 "Engine Exhaust Particulate Control System Info";
CM_ SG_ 2566638590 ExhstPrtltCntrlSstmDgnstCnt "Exhaust Particulate Control System Diagnostic Count: The total occurrences of diagnostic codes for the exhaust particulate control system that have been active above a predetermined time threshold. A code that has been active less than the predetermi...";
CM_ SG_ 2566638590 ExhstPrtltCntrlSstmDgnstTm "Exhaust Particulate Control System Diagnostic Time: The total time the exhaust particulate control diagnostic codes have been active. Total time only includes the active time for codes which have been active above a predetermined time threshold. The ...";
CM_ BO_ 2566638846 "Well Stimulation Pump Hours";
CM_ SG_ 2566638846 WllStmltnPmpMntnnIntrvlHrs "Well Stimulation Pump Maintenance Interval Hours: The hours accumulated since the last maintenance interval on the well stimulation pump.";
CM_ SG_ 2566638846 WllStmltnPmpPkngOprtnHrs "Well Stimulation Pump Packing Operation Hours: The hours accumulated since the last time a packing replacement was performed on the well stimulation pump.";
CM_ SG_ 2566638846 WllStmltnPmpVlvOprtnHrs "Well Stimulation Pump Valve Operation Hours: The hours accumulated since the last time a valve replacement was performed on the well stimulation pump.";
CM_ SG_ 2566638846 WllStmltnPmpVlvStOprtnHrs "Well Stimulation Pump Valve Seat Operation Hours: The hours accumulated since the last time a valve seat replacement was performed on the well stimulation pump.";
CM_ BO_ 2566639102 "Well Stimulation Pump System Configuration Status";
CM_ SG_ 2566639102 WllStmltnPmpPlngrFrngOrdrSttng "Well Stimulation Pump Plunger Firing Order Setting: Well stimulation pump plunger firing order0000b = Firing order 1-2-30001b = Firing order 1-5-2-3-40010b = Reserved0011b = Reserved0100b = Reserved0101b = Reserved0110b = Reserved0111b = Reserved1000...";
CM_ SG_ 2566639102 WllStmltnPmpRdLdHghThrshldSttng "Well Stimulation Pump Rod Load High Threshold Setting: Rod load force at which the rod load is considered at the highest acceptable force.";
CM_ SG_ 2566639102 WSttPpCstSpdHTsdStt "Well Stimulation Pump Crankshaft Speed High Threshold Setting: Configurable well stimulation pump crankshaft speed that has been considered to be the highest acceptable speed.";
CM_ SG_ 2566639102 WSttPpCstSpdLwTsdStt "Well Stimulation Pump Crankshaft Speed Low Threshold Setting: Configurable well stimulation pump crankshaft speed that has been considered to be the lowest acceptable speed.";
CM_ SG_ 2566639102 WSttPpDsPssHTsdStt "Well Stimulation Pump Discharge Pressure High Threshold Setting: Configurable pressure at which the discharge pressure is considered at the highest acceptable pressure.";
CM_ SG_ 2566639102 WSttPpGBxOPssHTsdStt "Well Stimulation Pump Gear Box Oil Pressure High Threshold Setting: Configurable pressure at which the gearbox oil pressure is considered at the highest acceptable pressure.";
CM_ SG_ 2566639102 WSttPpGBxOPssLwTsdStt "Well Stimulation Pump Gear Box Oil Pressure Low Threshold Setting: Configurable pressure at which the gearbox oil pressure is considered at the lowest acceptable pressure.";
CM_ SG_ 2566639102 WSttPpGBxOTptHTsdStt "Well Stimulation Pump Gear Box Oil Temperature High Threshold Setting: Configurable temperature at which the gearbox oil temperature is considered at the highest acceptable temperature.";
CM_ SG_ 2566639102 WSttPpGBxOTptLwTsdStt "Well Stimulation Pump Gear Box Oil Temperature Low Threshold Setting: Configurable temperature at which the gearbox oil temperature is considered at the lowest acceptable temperature.";
CM_ SG_ 2566639102 WSttPpStPssHTsdStt "Well Stimulation Pump Suction Pressure High Threshold Setting: Configurable pressure at which the suction pressure is considered at the highest acceptable pressure.";
CM_ SG_ 2566639102 WSttPpStPssLwTsdStt "Well Stimulation Pump Suction Pressure Low Threshold Setting: Configurable pressure at which the suction pressure is considered at the lowest acceptable pressure.";
CM_ BO_ 2566639614 "DC/DC Converter 1 Lifetime Data";
CM_ SG_ 2566639614 DCDC1TotalHighSideCharge "DC/DC 1 Total High Side Charge: Indicates the total lifetime charge converted by the DC/DC from the high side (e.g. HVES) during buck mode.  ";
CM_ SG_ 2566639614 DCDC1TotalHighSideEnergy "DC/DC 1 Total High Side Energy: Indicates the total lifetime energy converted by the DC/DC from the high side (e.g. HVES) during buck mode.";
CM_ SG_ 2566639614 DCDC1TotalLowSideCharge "DC/DC 1 Total Low Side Charge: Indicates the total lifetime charge converted by the DC/DC  from the low side (e.g. SLI battery) during boost mode.";
CM_ SG_ 2566639614 DCDC1TotalLowSideEnergy "DC/DC 1 Total Low Side Energy: Indicates the total lifetime energy converted by the DC/DC  from the low side (e.g. SLI battery) during boost mode.";
CM_ BO_ 2566639870 "DC/DC Converter 1 Configuration 1";
CM_ SG_ 2566639870 DCDC1HghSdCrrntMxmmLmtSttng "DC/DC 1 High Side Current Maximum Limit Setting: Reports the active maximum limit on the high side current of the DC/DC Converter.  The setting may be requested by a separate device (via SPN 8565) or determined by the DC/DC Controller based on operat...";
CM_ SG_ 2566639870 DCDC1HghSdVltgMnmmLmtSttng "DC/DC 1 High Side Voltage Minimum Limit Setting: Reports the active minimum limit on the high side voltage of the DC/DC Converter.  The setting may be requested by a separate device (via SPN 8563) or determined by the DC/DC Controller based on operat...";
CM_ SG_ 2566639870 DCDC1HghSdVltgMxmmLmtSttng "DC/DC 1 High Side Voltage Maximum Limit Setting: Reports the active maximum limit on the high side voltage of the DC/DC Converter.  The setting may be requested by a separate device (via SPN 8564) or determined by the DC/DC Controller based on operat...";
CM_ SG_ 2566639870 DCDC1LwSdCrrntMxmmLmtSttng "DC/DC 1 Low Side Current Maximum Limit Setting: Reports the active maximum limit on the low side current of the DC/DC Converter.  The setting may be requested by a separate device (via SPN 8568) or determined by the DC/DC Controller based on operatin...";
CM_ SG_ 2566639870 DCDC1LwSdVltgBkDfltSttng "DC/DC 1 Low Side Voltage Buck Default Setting: Reports the converter active Low Side Voltage Buck Default Setting.  The default may be requested by a separate device (via SPN 9515).Note: Report Not Available (FFFFh) when no default has been set.";
CM_ SG_ 2566639870 DCDC1LwSdVltgMnmmLmtSttng "DC/DC 1 Low Side Voltage Minimum Limit Setting: Reports the active minimum limit on the low side voltage of the DC/DC Converter.  The setting may be requested by a separate device (via SPN 8566) or determined by the DC/DC Controller based on operatin...";
CM_ SG_ 2566639870 DCDC1LwSdVltgMxmmLmtSttng "DC/DC 1 Low Side Voltage Maximum Limit Setting: Reports the active maximum limit on the low side voltage of the DC/DC Converter.  The setting may be requested by a separate device (via SPN 8567) or determined by the DC/DC Controller based on operatin...";
CM_ SG_ 2566639870 DCDC1SLIBttrTmprtrMxmmLmtSttng "DC/DC 1 SLI Battery Temperature Maximum Limit Setting: Reports the active SLI Battery Temperature maximum limit.  The setting may be requested by a separate device (via SPN 8819) or determined by the DC/DC Controller based on operating conditions.";
CM_ SG_ 2566639870 DCDC1SLIBttTCCtMxLtStt "DC/DC 1 SLI Battery Terminal Charge Current Maximum Limit Setting: Reports the active SLI Battery charging current maximum limit (at the battery terminals).  The setting may be requested by a separate device (via SPN 8818) or determined by the DC/DC ...";
CM_ SG_ 2566639870 DCDC1SLIBttTVtMxLtStt "DC/DC 1 SLI Battery Terminal Voltage Maximum Limit Setting: Reports the active SLI Battery Voltage maximum limit (at the battery terminals).  The setting may be requested by a separate device (via SPN 8817) or determined by the DC/DC Controller based...";
CM_ BO_ 2566640382 "Pump Oil Message";
CM_ SG_ 2566640382 WellStimulationPumpOilDensity "Well Stimulation Pump Oil Density: Density of the well stimulation pump oil.";
CM_ SG_ 2566640382 WellStimulationPumpOilViscosity "Well Stimulation Pump Oil Viscosity: Dynamic viscosity of the well stimulation pump oil.";
CM_ SG_ 2566640382 WllStmltnPmpOlRltvDltrt "Well Stimulation Pump Oil Relative Dielectricity: Well stimulation pump oil relative dielectricity used to describe the well stimulation pump oil quality.";
CM_ SG_ 2566640382 WllStmltnPmpOlTmprtr "Well Stimulation Pump Oil Temperature: Temperature of the well stimulation pump lubricant.";
CM_ BO_ 2566641150 "Aftercooler and Oil Cooler Fluids 2";
CM_ SG_ 2566641150 AltrntrBrngHdrIntkPrssr "Alternator Bearing Header Intake Pressure: Pressure of the lube oil at the intake of alternator bearing header.";
CM_ SG_ 2566641150 AltrntrOlClrDshrgPmpPrssr "Alternator Oil Cooler Discharge Pump Pressure: Pressure of the lube oil at the alternator oil cooler discharge pump.";
CM_ SG_ 2566641150 EngnOlClrDshrgPmpPrssr "Engine Oil Cooler Discharge Pump Pressure: Pressure of the lube oil at engine oil cooler discharge pump.";
CM_ SG_ 2566641150 EngnOlClrIntkTmprtr "Engine Oil Cooler Intake Temperature: Temperature of lube oil at engine cooler intake.";
CM_ BO_ 2566641406 "Electronic Engine Controller 21";
CM_ SG_ 2566641406 EngnExhstMnfldAsltPrssr1 "Engine Exhaust Manifold Absolute Pressure 1: Absolute pressure of the exhaust gasses as measured at the engine exhaust manifold, location 1.";
CM_ SG_ 2566641406 EngnExhstMnfldAsltPrssr2 "Engine Exhaust Manifold Absolute Pressure 2: Absolute pressure of the exhaust gasses as measured at the engine exhaust manifold, location 2.";
CM_ BO_ 2566642942 "Door Control 4";
CM_ SG_ 2566642942 EnableStatusofDoor21 "Enable Status of Door 21: Enable status of bus door 21.  Enabled means the bus doors are able to be automatically opened or closed.00b = Door disabled01b = Door enabled10b = Error11b = Not available";
CM_ SG_ 2566642942 EnableStatusofDoor22 "Enable Status of Door 22: Enable status of bus door 22.  Enabled means the bus doors are able to be automatically opened or closed.00b = Door disabled01b = Door enabled10b = Error11b = Not available";
CM_ SG_ 2566642942 EnableStatusofDoor23 "Enable Status of Door 23: Enable status of bus door 23.  Enabled means the bus doors are able to be automatically opened or closed.00b = Door disabled01b = Door enabled10b = Error11b = Not available";
CM_ SG_ 2566642942 EnableStatusofDoor24 "Enable Status of Door 24: Enable status of bus door 24.  Enabled means the bus doors are able to be automatically opened or closed.00b = Door disabled01b = Door enabled10b = Error11b = Not available";
CM_ SG_ 2566642942 EnableStatusofDoor25 "Enable Status of Door 25: Enable status of bus door 25.  Enabled means the bus doors are able to be automatically opened or closed.00b = Door disabled01b = Door enabled10b = Error11b = Not available";
CM_ SG_ 2566642942 EnableStatusofDoor26 "Enable Status of Door 26: Enable status of bus door 26.  Enabled means the bus doors are able to be automatically opened or closed.00b = Door disabled01b = Door enabled10b = Error11b = Not available";
CM_ SG_ 2566642942 EnableStatusofDoor27 "Enable Status of Door 27: Enable status of bus door 27.  Enabled means the bus doors are able to be automatically opened or closed.00b = Door disabled01b = Door enabled10b = Error11b = Not available";
CM_ SG_ 2566642942 EnableStatusofDoor28 "Enable Status of Door 28: Enable status of bus door 28.  Enabled means the bus doors are able to be automatically opened or closed.00b = Door disabled01b = Door enabled10b = Error11b = Not available";
CM_ SG_ 2566642942 EnableStatusofDoor29 "Enable Status of Door 29: Enable status of bus door 29.  Enabled means the bus doors are able to be automatically opened or closed.00b = Door disabled01b = Door enabled10b = Error11b = Not available";
CM_ SG_ 2566642942 EnableStatusofDoor30 "Enable Status of Door 30: Enable status of bus door 30.  Enabled means the bus doors are able to be automatically opened or closed.00b = Door disabled01b = Door enabled10b = Error11b = Not available";
CM_ SG_ 2566642942 LockStatusofDoor21 "Lock Status of Door 21: Lock status of bus door 2100b = Unlocked01b = Locked10b = Error11b = Not available";
CM_ SG_ 2566642942 LockStatusofDoor22 "Lock Status of Door 22: Lock status of bus door 2200b = Unlocked01b = Locked10b = Error11b = Not available";
CM_ SG_ 2566642942 LockStatusofDoor23 "Lock Status of Door 23: Lock status of bus door 2300b = Unlocked01b = Locked10b = Error11b = Not available";
CM_ SG_ 2566642942 LockStatusofDoor24 "Lock Status of Door 24: Lock status of bus door 2400b = Unlocked01b = Locked10b = Error11b = Not available";
CM_ SG_ 2566642942 LockStatusofDoor25 "Lock Status of Door 25: Lock status of bus door 2500b = Unlocked01b = Locked10b = Error11b = Not available";
CM_ SG_ 2566642942 LockStatusofDoor26 "Lock Status of Door 26: Lock status of bus door 2600b = Unlocked01b = Locked10b = Error11b = Not available";
CM_ SG_ 2566642942 LockStatusofDoor27 "Lock Status of Door 27: Lock status of bus door 2700b = Unlocked01b = Locked10b = Error11b = Not available";
CM_ SG_ 2566642942 LockStatusofDoor28 "Lock Status of Door 28: Lock status of bus door 2800b = Unlocked01b = Locked10b = Error11b = Not available";
CM_ SG_ 2566642942 LockStatusofDoor29 "Lock Status of Door 29: Lock status of bus door 2900b = Unlocked01b = Locked10b = Error11b = Not available";
CM_ SG_ 2566642942 LockStatusofDoor30 "Lock Status of Door 30: Lock status of bus door 3000b = Unlocked01b = Locked10b = Error11b = Not available";
CM_ SG_ 2566642942 OpenStatusofDoor21 "Open Status of Door 21: Open status of bus door 2100b = Door closed01b = Door opened10b = Error11b = Not available";
CM_ SG_ 2566642942 OpenStatusofDoor22 "Open Status of Door 22: Open status of bus door 2200b = Door closed01b = Door opened10b = Error11b = Not available";
CM_ SG_ 2566642942 OpenStatusofDoor23 "Open Status of Door 23: Open status of bus door 2300b = Door closed01b = Door opened10b = Error11b = Not available";
CM_ SG_ 2566642942 OpenStatusofDoor24 "Open Status of Door 24: Open status of bus door 2400b = Door closed01b = Door opened10b = Error11b = Not available";
CM_ SG_ 2566642942 OpenStatusofDoor25 "Open Status of Door 25: Open status of bus door 2500b = Door closed01b = Door opened10b = Error11b = Not available";
CM_ SG_ 2566642942 OpenStatusofDoor26 "Open Status of Door 26: Open status of bus door 2600b = Door closed01b = Door opened10b = Error11b = Not available";
CM_ SG_ 2566642942 OpenStatusofDoor27 "Open Status of Door 27: Open status of bus door 2700b = Door closed01b = Door opened10b = Error11b = Not available";
CM_ SG_ 2566642942 OpenStatusofDoor28 "Open Status of Door 28: Open status of bus door 2800b = Door closed01b = Door opened10b = Error11b = Not available";
CM_ SG_ 2566642942 OpenStatusofDoor29 "Open Status of Door 29: Open status of bus door 2900b = Door closed01b = Door opened10b = Error11b = Not available";
CM_ SG_ 2566642942 OpenStatusofDoor30 "Open Status of Door 30: Open status of bus door 3000b = Door closed01b = Door opened10b = Error11b = Not available";
CM_ BO_ 2566643198 "Door Control 3";
CM_ SG_ 2566643198 EnableStatusofDoor11 "Enable Status of Door 11: Enable status of bus door 11.  Enabled means the bus doors are able to be automatically opened or closed.00b = Door disabled01b = Door enabled10b = Error11b = Not available";
CM_ SG_ 2566643198 EnableStatusofDoor12 "Enable Status of Door 12: Enable status of bus door 12.  Enabled means the bus doors are able to be automatically opened or closed.00b = Door disabled01b = Door enabled10b = Error11b = Not available";
CM_ SG_ 2566643198 EnableStatusofDoor13 "Enable Status of Door 13: Enable status of bus door 13.  Enabled means the bus doors are able to be automatically opened or closed.00b = Door disabled01b = Door enabled10b = Error11b = Not available";
CM_ SG_ 2566643198 EnableStatusofDoor14 "Enable Status of Door 14: Enable status of bus door 14.  Enabled means the bus doors are able to be automatically opened or closed.00b = Door disabled01b = Door enabled10b = Error11b = Not available";
CM_ SG_ 2566643198 EnableStatusofDoor15 "Enable Status of Door 15: Enable status of bus door 15.  Enabled means the bus doors are able to be automatically opened or closed.00b = Door disabled01b = Door enabled10b = Error11b = Not available";
CM_ SG_ 2566643198 EnableStatusofDoor16 "Enable Status of Door 16: Enable status of bus door 16.  Enabled means the bus doors are able to be automatically opened or closed.00b = Door disabled01b = Door enabled10b = Error11b = Not available";
CM_ SG_ 2566643198 EnableStatusofDoor17 "Enable Status of Door 17: Enable status of bus door 17.  Enabled means the bus doors are able to be automatically opened or closed.00b = Door disabled01b = Door enabled10b = Error11b = Not available";
CM_ SG_ 2566643198 EnableStatusofDoor18 "Enable Status of Door 18: Enable status of bus door 18.  Enabled means the bus doors are able to be automatically opened or closed.00b = Door disabled01b = Door enabled10b = Error11b = Not available";
CM_ SG_ 2566643198 EnableStatusofDoor19 "Enable Status of Door 19: Enable status of bus door 19.  Enabled means the bus doors are able to be automatically opened or closed.00b = Door disabled01b = Door enabled10b = Error11b = Not available";
CM_ SG_ 2566643198 EnableStatusofDoor20 "Enable Status of Door 20: Enable status of bus door 20.  Enabled means the bus doors are able to be automatically opened or closed.00b = Door disabled01b = Door enabled10b = Error11b = Not available";
CM_ SG_ 2566643198 LockStatusofDoor11 "Lock Status of Door 11: Lock status of bus door 1100b = Unlocked 01b = Locked10b = Error11b = Not available";
CM_ SG_ 2566643198 LockStatusofDoor12 "Lock Status of Door 12: Lock status of bus door 1200b = Unlocked01b = Locked10b = Error11b = Not available";
CM_ SG_ 2566643198 LockStatusofDoor13 "Lock Status of Door 13: Lock status of bus door 1300b = Unlocked01b = Locked10b = Error11b = Not available";
CM_ SG_ 2566643198 LockStatusofDoor14 "Lock Status of Door 14: Lock status of bus door 1400b = Unlocked01b = Locked10b = Error11b = Not available";
CM_ SG_ 2566643198 LockStatusofDoor15 "Lock Status of Door 15: Lock status of bus door 1500b = Unlocked01b = Locked10b = Error11b = Not available";
CM_ SG_ 2566643198 LockStatusofDoor16 "Lock Status of Door 16: Lock status of bus door 1600b = Unlocked01b = Locked10b = Error11b = Not available";
CM_ SG_ 2566643198 LockStatusofDoor17 "Lock Status of Door 17: Lock status of bus door 1700b = Unlocked01b = Locked10b = Error11b = Not available";
CM_ SG_ 2566643198 LockStatusofDoor18 "Lock Status of Door 18: Lock status of bus door 1800b = Unlocked01b = Locked10b = Error11b = Not available";
CM_ SG_ 2566643198 LockStatusofDoor19 "Lock Status of Door 19: Lock status of bus door 1900b = Unlocked01b = Locked10b = Error11b = Not available";
CM_ SG_ 2566643198 LockStatusofDoor20 "Lock Status of Door 20: Lock status of bus door 2000b = Unlocked01b = Locked10b = Error11b = Not available";
CM_ SG_ 2566643198 OpenStatusofDoor11 "Open Status of Door 11: Open status of bus door 1100b = Door closed01b = Door opened10b = Error11b = Not available";
CM_ SG_ 2566643198 OpenStatusofDoor12 "Open Status of Door 12: Open status of bus door 1200b = Door closed01b = Door opened10b = Error11b = Not available";
CM_ SG_ 2566643198 OpenStatusofDoor13 "Open Status of Door 13: Open status of bus door 1300b = Door closed01b = Door opened10b = Error11b = Not available";
CM_ SG_ 2566643198 OpenStatusofDoor14 "Open Status of Door 14: Open status of bus door 1400b = Door closed01b = Door opened10b = Error11b = Not available";
CM_ SG_ 2566643198 OpenStatusofDoor15 "Open Status of Door 15: Open status of bus door 1500b = Door closed01b = Door opened10b = Error11b = Not available";
CM_ SG_ 2566643198 OpenStatusofDoor16 "Open Status of Door 16: Open status of bus door 1600b = Door closed01b = Door opened10b = Error11b = Not available";
CM_ SG_ 2566643198 OpenStatusofDoor17 "Open Status of Door 17: Open status of bus door 1700b = Door closed01b = Door opened10b = Error11b = Not available";
CM_ SG_ 2566643198 OpenStatusofDoor18 "Open Status of Door 18: Open status of bus door 1800b = Door closed01b = Door opened10b = Error11b = Not available";
CM_ SG_ 2566643198 OpenStatusofDoor19 "Open Status of Door 19: Open status of bus door 1900b = Door closed01b = Door opened10b = Error11b = Not available";
CM_ SG_ 2566643198 OpenStatusofDoor20 "Open Status of Door 20: Open status of bus door 2000b = Door closed01b = Door opened10b = Error11b = Not available";
CM_ BO_ 2566643454 "Engine Temperature 6";
CM_ SG_ 2566643454 EngineIntakeCoolantTemperature "Engine Intake Coolant Temperature: Temperature of the coolant at the intake of the engine block.";
CM_ SG_ 2566643454 EngnChrgArClrIntkClntTmprtr "Engine Charge Air Cooler Intake Coolant Temperature: Temperature of the fluid in the low temperature circuit measured at the fluid intake of the charge air cooler.";
CM_ SG_ 2566643454 EngnChrgArClrOtltClntTmprtr "Engine Charge Air Cooler Outlet Coolant Temperature: Temperature of the fluid in the low temperature circuit measured at the fluid outlet of the charge air cooler.";
CM_ SG_ 2566643454 EItMdAtSdCtCtCtDtTpt "Engine Intake Manifold Air to Secondary Coolant Circuit Coolant Differential Temperature: Indicates the differential temperature between the engine intake manifold air to secondary coolant circuit coolant.";
CM_ BO_ 2566643710 "Intake/Exhaust Conditions 3";
CM_ SG_ 2566643710 EngineMixer1IntakePressure "Engine Mixer 1 Intake Pressure: The pressure at the intake of the air and fuel mixer.";
CM_ SG_ 2566643710 EngineMixer2IntakePressure "Engine Mixer 2 Intake Pressure: The pressure at the intake of the second air and fuel mixer.";
CM_ SG_ 2566643710 EngnIntkMnfld2AsltPrssrHghRsltn "Engine Intake Manifold 2 Absolute Pressure (High Resolution): The absolute pressure measurement of the air intake manifold for bank 2 or the second air intake manifold.  If there are multiple air pressure sensors in the intake stream, this is the las...";
CM_ SG_ 2566643710 DsrdEngnIntkMnfldPrssrHghLmt "Desired Engine Intake Manifold Pressure High Limit: The desired pressure high limit of the air intake manifold. This SP is a high resolution measurement.";
CM_ BO_ 2566644990 "Fuel Information 7 (Gaseous)";
CM_ SG_ 2566644990 DrvrSdFlRptl1CvrStts "Driver Side Fuel Receptacle 1 Cover Status: Indicates if the cover for the first fuel receptacle on the driver side is attached or detached.00b = Receptacle cover is detached01b = Receptacle cover is attached10b = Error11b = Not available";
CM_ SG_ 2566644990 DrvrSdFlRptl2CvrStts "Driver Side Fuel Receptacle 2 Cover Status: Indicates if the cover for the second fuel receptacle on the driver side is attached or detached.00b = Receptacle cover is detached01b = Receptacle cover is attached10b = Error11b = Not available";
CM_ SG_ 2566644990 FlStrgCmprtmnt1Tmprtr1 "Fuel Storage Compartment 1 Temperature 1: The ambient temperature in the first fuel storage compartment.  If there is more than 1 sensor, then this is the first sensor. Note that this is not the temperature of the fuel in the fuel tank.";
CM_ SG_ 2566644990 FlStrgCmprtmnt1Tmprtr2 "Fuel Storage Compartment 1 Temperature 2: The ambient temperature as measured by the second temperature sensor in the first fuel storage compartment. Note that this is not the temperature of the fuel in the fuel tank.";
CM_ SG_ 2566644990 FlStrgCmprtmnt2Tmprtr1 "Fuel Storage Compartment 2 Temperature 1: The ambient temperature in the second fuel storage compartment.  If there is more than 1 sensor, then this is the first sensor. Note that this is not the temperature of the fuel in the fuel tank.";
CM_ SG_ 2566644990 FlStrgCmprtmnt2Tmprtr2 "Fuel Storage Compartment 2 Temperature 2: The ambient temperature as measured by the second temperature sensor in the second fuel storage compartment. Note that this is not the temperature of the fuel in the fuel tank.";
CM_ SG_ 2566644990 FlStrgCmprtmnt3Tmprtr1 "Fuel Storage Compartment 3 Temperature 1: The ambient temperature in the third fuel storage compartment.  If there is more than 1 sensor, then this is the first sensor. Note that this is not the temperature of the fuel in the fuel tank.";
CM_ SG_ 2566644990 FlStrgCmprtmnt3Tmprtr2 "Fuel Storage Compartment 3 Temperature 2: The ambient temperature as measured by the second temperature sensor in the third fuel storage compartment. Note that this is not the temperature of the fuel in the fuel tank.";
CM_ SG_ 2566644990 FrontFuelReceptacleCoverStatus "Front Fuel Receptacle Cover Status: Indicates if the cover for the fuel receptacle at the front of the vehicle is attached or detached.00b = Receptacle cover is detached01b = Receptacle cover is attached10b = Error11b = Not available";
CM_ SG_ 2566644990 PssngrSdFlRptl1CvrStts "Passenger Side Fuel Receptacle 1 Cover Status: Indicates if the cover for the first fuel receptacle on the passenger side is attached or detached.00b = Receptacle cover is detached01b = Receptacle cover is attached10b = Error11b = Not available...";
CM_ SG_ 2566644990 PssngrSdFlRptl2CvrStts "Passenger Side Fuel Receptacle 2 Cover Status: Indicates if the cover for the second fuel receptacle on the passenger side is attached or detached.00b = Receptacle cover is detached01b = Receptacle cover is attached10b = Error11b = Not available...";
CM_ BO_ 2566645246 "High Voltage Energy Storage System Fan Status";
CM_ SG_ 2566645246 HVESSFanEnableStatus "HVESS Fan Enable Status: Enable and direction status of this HVES fan.00b = Fan Off01b = Fan On - Normal, Forward, or Default Direction10b = Fan On - Reverse Direction11b = Not available";
CM_ SG_ 2566645246 HVESSFanStatusReasonCode "HVESS Fan Status Reason Code: Provides the reason code describing the unique failure of this HVES fan.  If a detailed reason code is not used by the supporting application, or this reason code is Not Available, the SPN 8409 (HVESS Fan Service Indicat...";
CM_ SG_ 2566645246 HVESSFanCommandStatus "HVESS Fan Command Status: Indicates the source of the speed command to this HVES fan.00b is communicated when the fan is self-controlled (e.g. based on a temperature sensor).  01b is communicated when responding to SPN 8386  (HVESS Fan Speed Command)...";
CM_ SG_ 2566645246 HVESSFanSpeed "HVESS Fan Speed: Speed of this HVES fan. ";
CM_ SG_ 2566645246 HVESSFanMediumTemperature "HVESS Fan Medium Temperature: A temperature measured and reported by the device.  It may be used for direct or remote (e.g. by another controller) control of the pump.  For example, this may be the temperature of the fluid flowing through the pump, o...";
CM_ SG_ 2566645246 HVESSFanPower "HVESS Fan Power: Calculated electrical power consumed by this HVES fan.";
CM_ SG_ 2566645246 HVESSFanServiceIndicator "HVESS Fan Service Indicator: Indicates that service is required for this HVES fan.  An active indication may convey a need for component replacement or periodic service.  SPN 8404 (HVESS Fan Status Reason Code) may provide additional detail as to the...";
CM_ SG_ 2566645246 HVESSFanOperatingStatus "HVESS Fan Operating Status: Indicates the operating status of this HVES fan.  This parameter is used to inform other devices that this system or component is no longer performing to its operational capacity and that reduced, or no flow of the medium ...";
CM_ SG_ 2566645246 HVESSFanInstance "HVESS Fan Instance: Indicates the instance of the HVES fan that is providing status in systems controlled by a master ECU.0000b = Instance 10001b = Instance 20010b = Instance 30011b = Instance 40100b = Instance 50101b = Instance 60110b = Instance 701...";
CM_ BO_ 2566646782 "Oil Debris Monitor Counts Ferrous Bins 1 & 2";
CM_ SG_ 2566646782 OlDrsMntrFrrsBn1Cnt "Oil Debris Monitor Ferrous Bin 1 Count: Total number of particles detected in Ferrous bin 1. Bin sizes are application specific.";
CM_ SG_ 2566646782 OlDrsMntrFrrsBn2Cnt "Oil Debris Monitor Ferrous Bin 2 Count: Total number of particles detected in Ferrous bin 2. Bin sizes are application specific.";
CM_ SG_ 2566646782 OlDrsMntrFrrsBns1nd2IdntftnNmr "Oil Debris Monitor Ferrous Bins 1 and 2 Identification Number: Identification number of the Oil Debris Monitoring (ODM) sensor being reported for Ferrous bins 1 and 2. Identification numbers are application specific.";
CM_ BO_ 2566647038 "Oil Debris Monitor Counts Ferrous Bins 3 & 4";
CM_ SG_ 2566647038 OlDrsMntrFrrsBn3Cnt "Oil Debris Monitor Ferrous Bin 3 Count: Total number of particles detected in Ferrous bin 3. Bin sizes are application specific.";
CM_ SG_ 2566647038 OlDrsMntrFrrsBn4Cnt "Oil Debris Monitor Ferrous Bin 4 Count: Total number of particles detected in Ferrous bin 4. Bin sizes are application specific.";
CM_ SG_ 2566647038 OlDrsMntrFrrsBns3nd4IdntftnNmr "Oil Debris Monitor Ferrous Bins 3 and 4 Identification Number: Identification number of the Oil Debris Monitoring (ODM) sensor being reported for Ferrous bins 3 and 4. Identification numbers are application specific.";
CM_ BO_ 2566647294 "Oil Debris Monitor Counts Ferrous Bins 5 & 6";
CM_ SG_ 2566647294 OlDrsMntrFrrsBn5Cnt "Oil Debris Monitor Ferrous Bin 5 Count: Total number of particles detected in Ferrous bin 5. Bin sizes are application specific.";
CM_ SG_ 2566647294 OlDrsMntrFrrsBn6Cnt "Oil Debris Monitor Ferrous Bin 6 Count: Total number of particles detected in Ferrous bin 6. Bin sizes are application specific.";
CM_ SG_ 2566647294 OlDrsMntrFrrsBns5nd6IdntftnNmr "Oil Debris Monitor Ferrous Bins 5 and 6 Identification Number: Identification number of the Oil Debris Monitoring (ODM) sensor being reported for Ferrous bins 5 and 6. Identification numbers are application specific.";
CM_ BO_ 2566647550 "Oil Debris Monitor Counts Non-Ferrous Bins 1 & 2";
CM_ SG_ 2566647550 ODsMtNFsBs1d2IdttN "Oil Debris Monitor Non-Ferrous Bins 1 and 2 Identification Number: Identification number of the Oil Debris Monitoring (ODM) sensor being reported for Non-Ferrous bins 1 and 2.  Identification numbers are application specific.";
CM_ SG_ 2566647550 OlDrsMntrNnFrrsBn1Cnt "Oil Debris Monitor Non-Ferrous Bin 1 Count: Total number of particles detected in Non-Ferrous bin 1. Bin sizes are application specific.";
CM_ SG_ 2566647550 OlDrsMntrNnFrrsBn2Cnt "Oil Debris Monitor Non-Ferrous Bin 2 Count: Total number of particles detected in Non-Ferrous bin 2. Bin sizes are application specific.";
CM_ BO_ 2566647806 "Oil Debris Monitor Counts Non-Ferrous Bins 3 & 4";
CM_ SG_ 2566647806 ODsMtNFsBs3d4IdttN "Oil Debris Monitor Non-Ferrous Bins 3 and 4 Identification Number: Identification number of the Oil Debris Monitoring (ODM) sensor being reported for Non-Ferrous bins 3 and 4. Identification numbers are application specific.";
CM_ SG_ 2566647806 OlDrsMntrNnFrrsBn3Cnt "Oil Debris Monitor Non-Ferrous Bin 3 Count: Total number of particles detected in Non-Ferrous bin 3. Bin sizes are application specific.";
CM_ SG_ 2566647806 OlDrsMntrNnFrrsBn4Cnt "Oil Debris Monitor Non-Ferrous Bin 4 Count: Total number of particles detected in Non-Ferrous bin 4. Bin sizes are application specific.";
CM_ BO_ 2566648062 "Oil Debris Monitor Counts Non-Ferrous Bins 5 & 6";
CM_ SG_ 2566648062 ODsMtNFsBs5d6IdttN "Oil Debris Monitor Non-Ferrous Bins 5 and 6 Identification Number: Identification number of the Oil Debris Monitoring (ODM) sensor being reported for Non-Ferrous bins 5 and 6. Identification numbers are application specific.";
CM_ SG_ 2566648062 OlDrsMntrNnFrrsBn5Cnt "Oil Debris Monitor Non-Ferrous Bin 5 Count: Total number of particles detected in Non-Ferrous bin 5. Bin sizes are application specific.";
CM_ SG_ 2566648062 OlDrsMntrNnFrrsBn6Cnt "Oil Debris Monitor Non-Ferrous Bin 6 Count: Total number of particles detected in Non-Ferrous bin 6. Bin sizes are application specific.";
CM_ BO_ 2566648318 "Oil Debris Monitoring System Status";
CM_ SG_ 2566648318 OlDrsMntrEltrnsTmprtrStts "Oil Debris Monitor Electronics Temperature Status: Temperature indicator for the Oil Debris Monitor (ODM) Electronics.00b = Acceptable temperature01b = Temperature is outside of limits10b = Reserved11b = Not available";
CM_ SG_ 2566648318 OlDrsMntrEnvrnmntStts "Oil Debris Monitor Environment Status: Status of the electrical and mechanical environment surrounding the Oil Debris Monitor (ODM) Sensor.00b = Acceptable environment01b = Excessive noise in signal10b = Reserved11b = Not available";
CM_ SG_ 2566648318 OlDrsMntrSgnlPrssngEltrnsStts "Oil Debris Monitor Signal Processing Electronics Status: Status of the Oil Debris Monitor (ODM) signal processing electronics.00b = Electronics functioning normally01b = Fault in electronics10b = Reserved11b = Not available";
CM_ SG_ 2566648318 OlDrsMntrSnsngElmntStts "Oil Debris Monitor Sensing Element Status: Status of the Oil Debris Monitor (ODM) sensing element.00b = Sensing element OK01b = Fault with sensing element10b = Reserved11b = Not available";
CM_ SG_ 2566648318 OlDrsMntrSttsIdntftnNmr "Oil Debris Monitor Status Identification Number: Identification number of the Oil Debris Monitoring (ODM) sensor being reported. Identification numbers are application specific.";
CM_ SG_ 2566648318 OlDrsMntrTtlnmrfSnsrs "Oil Debris Monitor Total number of Sensors: Total number of Oil Debris Monitoring (ODM) sensors configured for this application.";
CM_ BO_ 2566649086 "Aftertreatment 2 Diesel Oxidation Catalyst 2";
CM_ SG_ 2566649086 Atttt2DOCIttDPFOttDtPss "Aftertreatment 2 DOC Intake to DPF Outlet Delta Pressure: Aftertreatment 2 Diesel Oxidation Catalyst intake to Diesel Particulate Filter outlet differential pressure in exhaust bank 1.";
CM_ SG_ 2566649086 Atttt2DsOxdtCtstItPss "Aftertreatment 2 Diesel Oxidation Catalyst Intake Pressure: Aftertreatment 2 Diesel Oxidation Catalyst absolute pressure measured at the DOC intake in exhaust bank 1.";
CM_ SG_ 2566649086 Atttt2DsOxdtCtstOttPss "Aftertreatment 2 Diesel Oxidation Catalyst Outlet Pressure: Aftertreatment 2 Diesel Oxidation Catalyst absolute pressure measured at the DOC outlet in exhaust bank 1.";
CM_ BO_ 2566649342 "Aftertreatment 1 Diesel Oxidation Catalyst 2";
CM_ SG_ 2566649342 Atttt1DOCIttDPFOttDtPss "Aftertreatment 1 DOC Intake to DPF Outlet Delta Pressure: Aftertreatment 1 Diesel Oxidation Catalyst intake to Diesel Particulate Filter outlet differential pressure in exhaust bank 1.";
CM_ SG_ 2566649342 Atttt1DsOxdtCtstItPss "Aftertreatment 1 Diesel Oxidation Catalyst Intake Pressure: Aftertreatment 1 Diesel Oxidation Catalyst absolute pressure measured at the DOC intake in exhaust bank 1.";
CM_ SG_ 2566649342 Atttt1DsOxdtCtstOttPss "Aftertreatment 1 Diesel Oxidation Catalyst Outlet Pressure: Aftertreatment 1 Diesel Oxidation Catalyst absolute pressure measured at the DOC outlet in exhaust bank 1.";
CM_ BO_ 2566649598 "Vehicle Position 2";
CM_ SG_ 2566649598 HorizontalDilutionofPrecision "Horizontal Dilution of Precision: Provides the dilution of precision in the horizontal (X-Y plane axis) direction as calculated by the positioning and locating system receiver. The dilution of precision factor is calculated from the observed position...";
CM_ SG_ 2566649598 PositionDilutionofPrecision "Position Dilution of Precision: Provides the dilution of precision for the overall position (X-Y-Z coordinate system) as calculated by the positioning and locating system receiver. The dilution of precision factor is calculated from the observed sate...";
CM_ SG_ 2566649598 TimeDilutionofPrecision "Time Dilution of Precision: Provides the estimated receiver clock error as calculated by the positioning and locating system receiver from the satellites’ clock data. The dilution of precision factor is calculated from the observed satellites (at lea...";
CM_ SG_ 2566649598 TotalNumberofSatellitesinView "Total Number of Satellites in View: Indicates the number of satellites in view of the positioning and locating system receiver.";
CM_ SG_ 2566649598 VerticalDilutionofPrecision "Vertical Dilution of Precision: Provides the dilution of precision in the vertical (Z axis) direction as calculated by the positioning and locating system receiver. The dilution of precision factor is calculated from the observed positions of the obs...";
CM_ BO_ 2566649854 "Electrified Accessory Propulsion Motor Coolant Fan 3 Status";
CM_ SG_ 2566649854 PpsMtCtF3CtCdStts "Propulsion Motor Coolant Fan 3 Controller Command Status: Indicates the source of the speed command to the Propulsion Motor Coolant Fan 3 system or component.00b is communicated when the controller is self-controlled  (e.g. based on a temperature sen...";
CM_ SG_ 2566649854 PpsMtCtF3CtSttsRsCd "Propulsion Motor Coolant Fan 3 Controller Status Reason Code: Provides the reason code describing the unique failure of the Propulsion Motor Coolant Fan 3 system or component.If a detailed reason code is not used by the supporting application, or thi...";
CM_ SG_ 2566649854 PropulsionMotorCoolantFan3Power "Propulsion Motor Coolant Fan 3 Power: Calculated electrical power consumed by the Propulsion Motor Coolant Fan 3.";
CM_ SG_ 2566649854 PrplsnMtrClntFn3CntrlTmprtr "Propulsion Motor Coolant Fan 3 Control Temperature: A temperature measured and reported by the device.  It may be used for direct or remote (by another controller) control of the Fan 3.  For example, this may be the temperature of the fluid flowing t...";
CM_ SG_ 2566649854 PrplsnMtrClntFn3EnlStts "Propulsion Motor Coolant Fan 3 Enable Status: Enable and direction status of the Propulsion Motor Coolant Fan 3 system or component.00b = Accessory Motor Off01b = Accessory Motor On - Normal, Forward, or Default Direction10b = Accessory Motor On - Re...";
CM_ SG_ 2566649854 PrplsnMtrClntFn3MtrSpd "Propulsion Motor Coolant Fan 3 Motor Speed: Motor Speed of the Propulsion Motor Coolant Fan 3. ";
CM_ SG_ 2566649854 PrplsnMtrClntFn3OprtngStts "Propulsion Motor Coolant Fan 3 Operating Status: Indicates the operating status of the Propulsion Motor Coolant Fan 3 system or component.This parameter is used to inform other devices that this system or component is no longer performing to its oper...";
CM_ SG_ 2566649854 PrplsnMtrClntFn3SrvIndtr "Propulsion Motor Coolant Fan 3 Service Indicator: Indicates that service is required for the Propulsion Motor Coolant Fan 3 system or component.An active indication may convey a need for component replacement or periodic service.  The Propulsion Moto...";
CM_ BO_ 2566650110 "Electrified Accessory Propulsion Motor Coolant Fan 2 Status";
CM_ SG_ 2566650110 PpsMtCtF2CtCdStts "Propulsion Motor Coolant Fan 2 Controller Command Status: Indicates the source of the speed command to the Propulsion Motor Coolant Fan 2 system or component.00b is communicated when the controller is self-controlled  (e.g. based on a temperature sen...";
CM_ SG_ 2566650110 PpsMtCtF2CtSttsRsCd "Propulsion Motor Coolant Fan 2 Controller Status Reason Code: Provides the reason code describing the unique failure of the Propulsion Motor Coolant Fan 2 system or component.If a detailed reason code is not used by the supporting application, or thi...";
CM_ SG_ 2566650110 PropulsionMotorCoolantFan2Power "Propulsion Motor Coolant Fan 2 Power: Calculated electrical power consumed by the Propulsion Motor Coolant Fan 2.";
CM_ SG_ 2566650110 PrplsnMtrClntFn2CntrlTmprtr "Propulsion Motor Coolant Fan 2 Control Temperature: A temperature measured and reported by the device.  It may be used for direct or remote (by another controller) control of the Fan 2.  For example, this may be the temperature of the fluid flowing t...";
CM_ SG_ 2566650110 PrplsnMtrClntFn2EnlStts "Propulsion Motor Coolant Fan 2 Enable Status: Enable and direction status of the Propulsion Motor Coolant Fan 2 system or component.00b = Accessory Motor Off01b = Accessory Motor On - Normal, Forward, or Default Direction10b = Accessory Motor On - Re...";
CM_ SG_ 2566650110 PrplsnMtrClntFn2MtrSpd "Propulsion Motor Coolant Fan 2 Motor Speed: Motor Speed of the Propulsion Motor Coolant Fan 2. ";
CM_ SG_ 2566650110 PrplsnMtrClntFn2OprtngStts "Propulsion Motor Coolant Fan 2 Operating Status: Indicates the operating status of the Propulsion Motor Coolant Fan 2 system or component.This parameter is used to inform other devices that this system or component is no longer performing to its oper...";
CM_ SG_ 2566650110 PrplsnMtrClntFn2SrvIndtr "Propulsion Motor Coolant Fan 2 Service Indicator: Indicates that service is required for the Propulsion Motor Coolant Fan 2 system or component.An active indication may convey a need for component replacement or periodic service.  The Propulsion Moto...";
CM_ BO_ 2566650366 "Electrified Accessory Propulsion Motor Coolant Fan 1 Status";
CM_ SG_ 2566650366 PpsMtCtF1CtCdStts "Propulsion Motor Coolant Fan 1 Controller Command Status: Indicates the source of the speed command to the Propulsion Motor Coolant Fan 1 system or component.00b is communicated when the controller is self-controlled  (e.g. based on a temperature sen...";
CM_ SG_ 2566650366 PpsMtCtF1CtSttsRsCd "Propulsion Motor Coolant Fan 1 Controller Status Reason Code: Provides the reason code describing the unique failure of the Propulsion Motor Coolant Fan 1 system or component.If a detailed reason code is not used by the supporting application, or thi...";
CM_ SG_ 2566650366 PropulsionMotorCoolantFan1Power "Propulsion Motor Coolant Fan 1 Power: Calculated electrical power consumed by the Propulsion Motor Coolant Fan 1.";
CM_ SG_ 2566650366 PrplsnMtrClntFn1CntrlTmprtr "Propulsion Motor Coolant Fan 1 Control Temperature: A temperature measured and reported by the device.  It may be used for direct or remote (by another controller) control of the Fan 1.  For example, this may be the temperature of the fluid flowing t...";
CM_ SG_ 2566650366 PrplsnMtrClntFn1EnlStts "Propulsion Motor Coolant Fan 1 Enable Status: Enable and direction status of the Propulsion Motor Coolant Fan 1 system or component.00b = Accessory Motor Off01b = Accessory Motor On - Normal, Forward, or Default Direction10b = Accessory Motor On - Re...";
CM_ SG_ 2566650366 PrplsnMtrClntFn1MtrSpd "Propulsion Motor Coolant Fan 1 Motor Speed: Motor Speed of the Propulsion Motor Coolant Fan 1. ";
CM_ SG_ 2566650366 PrplsnMtrClntFn1OprtngStts "Propulsion Motor Coolant Fan 1 Operating Status: Indicates the operating status of the Propulsion Motor Coolant Fan 1 system or component.This parameter is used to inform other devices that this system or component is no longer performing to its oper...";
CM_ SG_ 2566650366 PrplsnMtrClntFn1SrvIndtr "Propulsion Motor Coolant Fan 1 Service Indicator: Indicates that service is required for the Propulsion Motor Coolant Fan 1 system or component.An active indication may convey a need for component replacement or periodic service.  The Propulsion Moto...";
CM_ BO_ 2566650622 "Electrified Accessory Power Electronics Coolant Fan 3 Status";
CM_ SG_ 2566650622 PwEtsCtF3CtCdStts "Power Electronics Coolant Fan 3 Controller Command Status: Indicates the source of the speed command to the Power Electronics Coolant Fan 3 system or component.00b is communicated when the controller is self-controlled  (e.g. based on a temperature s...";
CM_ SG_ 2566650622 PwEtsCtF3CtSttsRsCd "Power Electronics Coolant Fan 3 Controller Status Reason Code: Provides the reason code describing the unique failure of the Power Electronics Coolant Fan 3 system or component.  If a detailed reason code is not used by the supporting application, or...";
CM_ SG_ 2566650622 PwrEltrnsClntFn3CntrlTmprtr "Power Electronics Coolant Fan 3 Control Temperature: A temperature measured and reported by the device.  It may be used for direct or remote (by another controller) control of the Fan 3.  For example, this may be the temperature of the fluid flowing ...";
CM_ SG_ 2566650622 PwrEltrnsClntFn3EnlStts "Power Electronics Coolant Fan 3 Enable Status: Enable and direction status of the Power Electronics Coolant Fan 3 system or component.00b = Accessory Motor Off01b = Accessory Motor On - Normal, Forward, or Default Direction10b = Accessory Motor On - ...";
CM_ SG_ 2566650622 PwrEltrnsClntFn3MtrSpd "Power Electronics Coolant Fan 3 Motor Speed: Motor Speed of the Power Electronics Coolant Fan 3. ";
CM_ SG_ 2566650622 PwrEltrnsClntFn3OprtngStts "Power Electronics Coolant Fan 3 Operating Status: Indicates the operating status of the Power Electronics Coolant Fan 3 system or component.This parameter is used to inform other devices that this system or component is no longer performing to its op...";
CM_ SG_ 2566650622 PwrEltrnsClntFn3Pwr "Power Electronics Coolant Fan 3 Power: Calculated electrical power consumed by the Power Electronics Coolant Fan 3.";
CM_ SG_ 2566650622 PwrEltrnsClntFn3SrvIndtr "Power Electronics Coolant Fan 3 Service Indicator: Indicates that service is required for the Power Electronics Coolant Fan 3 system or component.An active indication may convey a need for component replacement or periodic service.  The Power Electro...";
CM_ BO_ 2566650878 "Electrified Accessory Power Electronics Coolant Fan 2 Status";
CM_ SG_ 2566650878 PwEtsCtF2CtCdStts "Power Electronics Coolant Fan 2 Controller Command Status: Indicates the source of the speed command to the Power Electronics Coolant Fan 2 system or component.00b is communicated when the controller is self-controlled  (e.g. based on a temperature s...";
CM_ SG_ 2566650878 PwEtsCtF2CtSttsRsCd "Power Electronics Coolant Fan 2 Controller Status Reason Code: Provides the reason code describing the unique failure of the Power Electronics Coolant Fan 2 system or component.If a detailed reason code is not used by the supporting application, or t...";
CM_ SG_ 2566650878 PwrEltrnsClntFn2CntrlTmprtr "Power Electronics Coolant Fan 2 Control Temperature: A temperature measured and reported by the device.  It may be used for direct or remote (by another controller) control of the Fan 2.  For example, this may be the temperature of the fluid flowing ...";
CM_ SG_ 2566650878 PwrEltrnsClntFn2EnlStts "Power Electronics Coolant Fan 2 Enable Status: Enable and direction status of the Power Electronics Coolant Fan 2 system or component.00b = Accessory Motor Off01b = Accessory Motor On - Normal, Forward, or Default Direction10b = Accessory Motor On - ...";
CM_ SG_ 2566650878 PwrEltrnsClntFn2MtrSpd "Power Electronics Coolant Fan 2 Motor Speed: Motor Speed of the Power Electronics Coolant Fan 2. ";
CM_ SG_ 2566650878 PwrEltrnsClntFn2OprtngStts "Power Electronics Coolant Fan 2 Operating Status: Indicates the operating status of the Power Electronics Coolant Fan 2 system or component.This parameter is used to inform other devices that this system or component is no longer performing to its op...";
CM_ SG_ 2566650878 PwrEltrnsClntFn2Pwr "Power Electronics Coolant Fan 2 Power: Calculated electrical power consumed by the Power Electronics Coolant Fan 2.";
CM_ SG_ 2566650878 PwrEltrnsClntFn2SrvIndtr "Power Electronics Coolant Fan 2 Service Indicator: Indicates that service is required for the Power Electronics Coolant Fan 2 system or component.An active indication may convey a need for component replacement or periodic service.  The Power Electro...";
CM_ BO_ 2566651134 "Electrified Accessory Power Electronics Coolant Fan 1 Status";
CM_ SG_ 2566651134 PwEtsCtF1CtCdStts "Power Electronics Coolant Fan 1 Controller Command Status: Indicates the source of the speed command to the Power Electronics Coolant Fan 1 system or component.00b is communicated when the controller is self-controlled  (e.g. based on a temperature s...";
CM_ SG_ 2566651134 PwEtsCtF1CtSttsRsCd "Power Electronics Coolant Fan 1 Controller Status Reason Code: Provides the reason code describing the unique failure of the Power Electronics Coolant Fan 1 system or component.If a detailed reason code is not used by the supporting application, or t...";
CM_ SG_ 2566651134 PwrEltrnsClntFn1CntrlTmprtr "Power Electronics Coolant Fan 1 Control Temperature: A temperature measured and reported by the device.  It may be used for direct or remote (by another controller) control of the Fan 1.  For example, this may be the temperature of the fluid flowing ...";
CM_ SG_ 2566651134 PwrEltrnsClntFn1EnlStts "Power Electronics Coolant Fan 1 Enable Status: Enable and direction status of the Power Electronics Coolant Fan 1 system or component.00b = Accessory Motor Off01b = Accessory Motor On - Normal, Forward, or Default Direction10b = Accessory Motor On - ...";
CM_ SG_ 2566651134 PwrEltrnsClntFn1MtrSpd "Power Electronics Coolant Fan 1 Motor Speed: Motor Speed of the Power Electronics Coolant Fan 1. ";
CM_ SG_ 2566651134 PwrEltrnsClntFn1OprtngStts "Power Electronics Coolant Fan 1 Operating Status: Indicates the operating status of the Power Electronics Coolant Fan 1 system or component.This parameter is used to inform other devices that this system or component is no longer performing to its op...";
CM_ SG_ 2566651134 PwrEltrnsClntFn1Pwr "Power Electronics Coolant Fan 1 Power: Calculated electrical power consumed by the Power Electronics Coolant Fan 1.";
CM_ SG_ 2566651134 PwrEltrnsClntFn1SrvIndtr "Power Electronics Coolant Fan 1 Service Indicator: Indicates that service is required for the Power Electronics Coolant Fan 1 system or component.An active indication may convey a need for component replacement or periodic service.  The Power Electro...";
CM_ BO_ 2566651390 "Electrified Accessory Propulsion Motor Oil Pump Status";
CM_ SG_ 2566651390 PropulsionMotorOilPumpPower "Propulsion Motor Oil Pump Power: Calculated electrical power consumed by the Propulsion Motor Oil Pump.";
CM_ SG_ 2566651390 PrplsnMtrOlPmpCntrllrCmmndStts "Propulsion Motor Oil Pump Controller Command Status: Indicates the source of the speed command to the Propulsion Motor Oil Pump system or component.00b is communicated when the controller is self-controlled  (e.g. based on a temperature sensor).01b i...";
CM_ SG_ 2566651390 PrplsnMtrOlPmpCntrllrSttsRsnCd "Propulsion Motor Oil Pump Controller Status Reason Code: Provides the reason code describing the unique failure of the Propulsion Motor Oil Pump system or component.If a detailed reason code is not used by the supporting application, or this reason c...";
CM_ SG_ 2566651390 PrplsnMtrOlPmpCntrlTmprtr "Propulsion Motor Oil Pump Control Temperature: A temperature measured and reported by the device.  It may be used for direct or remote (e.g. by another controller) control of the pump.  For example, this may be the temperature of the fluid flowing th...";
CM_ SG_ 2566651390 PrplsnMtrOlPmpEnlStts "Propulsion Motor Oil Pump Enable Status: Enable and direction status of the Propulsion Motor Oil Pump system or component.00b = Accessory Motor Off01b = Accessory Motor On - Normal, Forward, or Default Direction10b = Accessory Motor On - Reverse Dire...";
CM_ SG_ 2566651390 PrplsnMtrOlPmpMtrSpd "Propulsion Motor Oil Pump Motor Speed: Motor Speed of the Propulsion Motor Oil Pump. ";
CM_ SG_ 2566651390 PrplsnMtrOlPmpOprtngStts "Propulsion Motor Oil Pump Operating Status: Indicates the operating status of the Propulsion Motor Oil Pump system or component.This parameter is used to inform other devices that this system or component is no longer performing to its operational ca...";
CM_ SG_ 2566651390 PrplsnMtrOlPmpSrvIndtr "Propulsion Motor Oil Pump Service Indicator: Indicates that service is required for the Propulsion Motor Oil Pump system or component.An active indication may convey a need for component replacement or periodic service.  The Propulsion Motor Oil Pump...";
CM_ BO_ 2566651646 "Electrified Accessory Propulsion Motor Coolant Pump Status";
CM_ SG_ 2566651646 PpsMtCtPpCtCdStts "Propulsion Motor Coolant Pump Controller Command Status: Indicates the source of the speed command to the Propulsion Motor Coolant Pump system or component.00b is communicated when the controller is self-controlled  (e.g. based on a temperature senso...";
CM_ SG_ 2566651646 PpsMtCtPpCtSttsRsCd "Propulsion Motor Coolant Pump Controller Status Reason Code: Provides the reason code describing the unique failure of the Propulsion Motor Coolant Pump system or component.If a detailed reason code is not used by the supporting application, or this ...";
CM_ SG_ 2566651646 PropulsionMotorCoolantPumpPower "Propulsion Motor Coolant Pump Power: Calculated electrical power consumed by the Propulsion Motor Coolant Pump.";
CM_ SG_ 2566651646 PrplsnMtrClntPmpCntrlTmprtr "Propulsion Motor Coolant Pump Control Temperature: A temperature measured and reported by the device.  It may be used for direct or remote (e.g. by another controller) control of the pump.  For example, this may be the temperature of the fluid flowin...";
CM_ SG_ 2566651646 PrplsnMtrClntPmpEnlStts "Propulsion Motor Coolant Pump Enable Status: Enable and direction status of the Propulsion Motor Coolant Pump system or component.00b = Accessory Motor Off01b = Accessory Motor On - Normal, Forward, or Default Direction10b = Accessory Motor On - Reve...";
CM_ SG_ 2566651646 PrplsnMtrClntPmpMtrSpd "Propulsion Motor Coolant Pump Motor Speed: Motor Speed of the Propulsion Motor Coolant Pump. ";
CM_ SG_ 2566651646 PrplsnMtrClntPmpOprtngStts "Propulsion Motor Coolant Pump Operating Status: Indicates the operating status of the Propulsion Motor Coolant Pump system or component.This parameter is used to inform other devices that this system or component is no longer performing to its operat...";
CM_ SG_ 2566651646 PrplsnMtrClntPmpSrvIndtr "Propulsion Motor Coolant Pump Service Indicator: Indicates that service is required for the Propulsion Motor Coolant Pump system or component.An active indication may convey a need for component replacement or periodic service.  The Propulsion Motor ...";
CM_ BO_ 2566651902 "Electrified Accessory Power Electronics Coolant Pump Status";
CM_ SG_ 2566651902 PwEtsCtPpCtCdStts "Power Electronics Coolant Pump Controller Command Status: Indicates the source of the speed command to the Power Electronics Coolant Pump system or component.00b is communicated when the controller is self-controlled  (e.g. based on a temperature sen...";
CM_ SG_ 2566651902 PwEtsCtPpCtSttsRsCd "Power Electronics Coolant Pump Controller Status Reason Code: Provides the reason code describing the unique failure of the Power Electronics Coolant Pump system or component.If a detailed reason code is not used by the supporting application, or thi...";
CM_ SG_ 2566651902 PwrEltrnsClntPmpCntrlTmprtr "Power Electronics Coolant Pump Control Temperature: A temperature measured and reported by the device.  It may be used for direct or remote (e.g. by another controller) control of the pump.  For example, this may be the temperature of the fluid flowi...";
CM_ SG_ 2566651902 PwrEltrnsClntPmpEnlStts "Power Electronics Coolant Pump Enable Status: Enable and direction status of the Power Electronics Coolant Pump system or component.00b = Accessory Motor Off01b = Accessory Motor On - Normal, Forward, or Default Direction10b = Accessory Motor On - Re...";
CM_ SG_ 2566651902 PwrEltrnsClntPmpMtrSpd "Power Electronics Coolant Pump Motor Speed: Motor Speed of the Power Electronics Coolant Pump. ";
CM_ SG_ 2566651902 PwrEltrnsClntPmpOprtngStts "Power Electronics Coolant Pump Operating Status: Indicates the operating status of the Power Electronics Coolant Pump system or component.This parameter is used to inform other devices that this system or component is no longer performing to its oper...";
CM_ SG_ 2566651902 PwrEltrnsClntPmpPwr "Power Electronics Coolant Pump Power: Calculated electrical power consumed by the Power Electronics Coolant Pump.";
CM_ SG_ 2566651902 PwrEltrnsClntPmpSrvIndtr "Power Electronics Coolant Pump Service Indicator: Indicates that service is required for the Power Electronics Coolant Pump system or component.An active indication may convey a need for component replacement or periodic service.  The Power Electroni...";
CM_ BO_ 2566652414 "Electrified Accessory Motor Status";
CM_ SG_ 2566652414 ElectrifiedAccessoryMotorPower "Electrified Accessory Motor Power: Calculated electrical power consumed by this Electrified Accessory Motor.";
CM_ SG_ 2566652414 ElectrifiedAccessoryMotorSpeed "Electrified Accessory Motor Speed: Speed of this Electrified Accessory Motor. ";
CM_ SG_ 2566652414 EltrfdAssrMtrCntrllrCmmndStts "Electrified Accessory Motor Controller Command Status: Indicates the source of the speed command to this Electrified Accessory Motor system or component.00b is communicated when the controller is self-controlled (e.g. based on a temperature sensor).0...";
CM_ SG_ 2566652414 EltrfdAssrMtrCntrllrSttsRsnCd "Electrified Accessory Motor Controller Status Reason Code: Provides the reason code describing the unique failure of this Electrified Accessory Motor system or component.If a detailed reason code is not used by the supporting application, or this rea...";
CM_ SG_ 2566652414 EltrfdAssrMtrEnlStts "Electrified Accessory Motor Enable Status: Enable and direction status of this Electrified Accessory Motor system or component.00b = Accessory Motor Off01b = Accessory Motor On - Normal, Forward, or Default Direction10b = Accessory Motor On - Reverse...";
CM_ SG_ 2566652414 EltrfdAssrMtrInstn "Electrified Accessory Motor Instance: Indicates the electrified accessory instance that is providing status.0000b = Instance 10001b = Instance 20010b = Instance 30011b = Instance 40100b = Instance 50101b = Instance 60110b = Instance 70111b = Instance...";
CM_ SG_ 2566652414 EltrfdAssrMtrMdmTmprtr "Electrified Accessory Motor Medium Temperature: A temperature measured and reported by the device.  It may be used for direct or remote (e.g. by another controller) control of the pump.  For example, this may be the temperature of the fluid flowing t...";
CM_ SG_ 2566652414 EltrfdAssrMtrOprtngStts "Electrified Accessory Motor Operating Status: Indicates the operating status of this Electrified Accessory Motor system or component.  This parameter is used to inform other devices that this system or component is no longer performing to its operati...";
CM_ SG_ 2566652414 EltrfdAssrMtrSrvIndtr "Electrified Accessory Motor Service Indicator: Indicates that service is required for this Electrified Accessory Motor system or component.  An active indication may convey a need for component replacement or periodic service.  The Electrified Access...";
CM_ BO_ 2566652670 "SCR System Information";
CM_ SG_ 2566652670 Atttt1DsExstFdDsSstFz "Aftertreatment 1 Diesel Exhaust Fluid Dosing System Frozen: All or part of the diesel exhaust fluid system (DEF tank, DEF supply lines, DEF pump, and DEF doser, etc.) in bank 1 is frozen.In situations where it is desired to report the DEF system froz...";
CM_ SG_ 2566652670 Atttt2DsExstFdDsSstFz "Aftertreatment 2 Diesel Exhaust Fluid Dosing System Frozen: All or part of the diesel exhaust fluid system (DEF tank, DEF supply lines, DEF pump, and DEF doser, etc.) in bank 2 is frozen.In situations where it is desired to report the DEF system froz...";
CM_ SG_ 2566652670 DieselExhaustFluidFrozenTime "Diesel Exhaust Fluid Frozen Time: Indicates the amount of time the diesel exhaust fluid is frozen while key switch is on. This will accumulate over the life of the product, and will never be reset.This parameter is not for engine applications that ar...";
CM_ SG_ 2566652670 Aftrtrtmnt1SstmHdrrn "Aftertreatment 1 System Hydrocarbon: The ratio of the mass of hydrocarbon present in the aftertreatment system compared to the maximum allowable mass of hydrocarbon for the aftertreatment system. 100% represents the maximum percentage of hydrocarbon ...";
CM_ SG_ 2566652670 Aftrtrtmnt2SstmHdrrn "Aftertreatment 2 System Hydrocarbon: The ratio of the mass of hydrocarbon present in the aftertreatment 2 system compared to the maximum allowable mass of hydrocarbon for the aftertreatment system. 100% represents the maximum percentage of hydrocarbo...";
CM_ BO_ 2566652926 "Vehicle Electrical Power 14";
CM_ SG_ 2566652926 SLIBatteryPack1Battery4Capacity "SLI Battery Pack 1 Battery 4 Capacity: Total reserve capacity of the fourth battery in the first battery pack used for starting the engine, for lighting, and for ignition (SLI).  This value could be the original capacity, rated capacity, or the capac...";
CM_ SG_ 2566652926 SLIBatteryPack1Battery4Health "SLI Battery Pack 1 Battery 4 Health: Capacity of the fourth battery in the first battery pack relative to its original specification for the battery pack used for starting the engine, for lighting, and for ignition (SLI). 0% means battery pack is not...";
CM_ SG_ 2566652926 SLIBttP1Btt4PdtdMCVt "SLI Battery Pack 1 Battery 4 Predicted Minimum Cranking Voltage: Prediction of the minimum battery voltage of the fourth battery in the first battery pack used for starting the engine, for lighting, and for ignition (SLI) during a crank event, under ...";
CM_ SG_ 2566652926 SLIBttrPk1Bttr4SttfChrg "SLI Battery Pack 1 Battery 4 State of Charge: Indicates the remaining charge of the fourth battery in the first battery pack used for starting the engine, for lighting, and for ignition (SLI). 0% means no charge remaining, 100% means full capacity at...";
CM_ SG_ 2566652926 SLIBttrPk1Snsr4IntlztnStts "SLI Battery Pack 1 Sensor 4 Initialization Status: The battery sensor may go through an initialization process when it is first connected to a battery.  This parameter reports the battery sensor's progress through the initialization process.0 = Initi...";
CM_ BO_ 2566653182 "Vehicle Electrical Power 13";
CM_ SG_ 2566653182 SLIBatteryPack1Battery4Voltage "SLI Battery Pack 1 Battery 4 Voltage: Voltage of the fourth battery in the first set of batteries (battery pack) used for starting the engine, for lighting, and for ignition (SLI). The relation to physical location is determined by the equipment manu...";
CM_ SG_ 2566653182 SLIBttrPk1Bttr4NtCrrnt "SLI Battery Pack 1 Battery 4 Net Current: Net flow of electrical current into/out of the fourth battery in the first set of batteries (battery pack) used for starting the engine, for lighting, and for ignition (SLI). ";
CM_ SG_ 2566653182 SLIBttrPk1Bttr4Tmprtr "SLI Battery Pack 1 Battery 4 Temperature: Temperature of the fourth battery in the first set of batteries (battery pack) used for starting the engine, for lighting, and for ignition (SLI). The relation to physical location is determined by the equipm...";
CM_ BO_ 2566653438 "Vehicle Electrical Power 12";
CM_ SG_ 2566653438 SLIBatteryPack1Battery3Capacity "SLI Battery Pack 1 Battery 3 Capacity: Total reserve capacity of the third battery in the first battery pack used for starting the engine, for lighting, and for ignition (SLI).  This value could be the original capacity, rated capacity, or the capaci...";
CM_ SG_ 2566653438 SLIBatteryPack1Battery3Health "SLI Battery Pack 1 Battery 3 Health: Capacity of the third battery in the first battery pack relative to its original specification for the battery pack used for starting the engine, for lighting, and for ignition (SLI). 0% means battery pack is not ...";
CM_ SG_ 2566653438 SLIBttP1Btt3PdtdMCVt "SLI Battery Pack 1 Battery 3 Predicted Minimum Cranking Voltage: Prediction of the minimum battery voltage of the third battery in the first battery pack used for starting the engine, for lighting, and for ignition (SLI) during a crank event, under p...";
CM_ SG_ 2566653438 SLIBttrPk1Bttr3SttfChrg "SLI Battery Pack 1 Battery 3 State of Charge: Indicates the remaining charge of the third battery in the first battery pack used for starting the engine, for lighting, and for ignition (SLI). 0% means no charge remaining, 100% means full capacity at ...";
CM_ SG_ 2566653438 SLIBttrPk1Snsr3IntlztnStts "SLI Battery Pack 1 Sensor 3 Initialization Status: The battery sensor may go through an initialization process when it is first connected to a battery.  This parameter reports the battery sensor's progress through the initialization process.0 = Initi...";
CM_ BO_ 2566653694 "Vehicle Electrical Power 11";
CM_ SG_ 2566653694 SLIBatteryPack1Battery3Voltage "SLI Battery Pack 1 Battery 3 Voltage: Voltage of the third battery in the first set of batteries (battery pack) used for starting the engine, for lighting, and for ignition (SLI). The relation to physical location is determined by the equipment manuf...";
CM_ SG_ 2566653694 SLIBttrPk1Bttr3NtCrrnt "SLI Battery Pack 1 Battery 3 Net Current: Net flow of electrical current into/out of the third battery in the first set of batteries (battery pack) used for starting the engine, for lighting, and for ignition (SLI). ";
CM_ SG_ 2566653694 SLIBttrPk1Bttr3Tmprtr "SLI Battery Pack 1 Battery 3 Temperature: Temperature of the third battery in the first set of batteries (battery pack) used for starting the engine, for lighting, and for ignition (SLI). The relation to physical location is determined by the equipme...";
CM_ BO_ 2566653950 "Vehicle Electrical Power 10";
CM_ SG_ 2566653950 SLIBatteryPack1Battery2Capacity "SLI Battery Pack 1 Battery 2 Capacity: Total reserve capacity of the second battery in the first battery pack used for starting the engine, for lighting, and for ignition (SLI).  This value could be the original capacity, rated capacity, or the capac...";
CM_ SG_ 2566653950 SLIBatteryPack1Battery2Health "SLI Battery Pack 1 Battery 2 Health: Capacity of the second battery in the first battery pack relative to its original specification for the battery pack used for starting the engine, for lighting, and for ignition (SLI). 0% means battery pack is not...";
CM_ SG_ 2566653950 SLIBttP1Btt2PdtdMCVt "SLI Battery Pack 1 Battery 2 Predicted Minimum Cranking Voltage: Prediction of the minimum battery voltage of the second battery in the first battery pack used for starting the engine, for lighting, and for ignition (SLI) during a crank event, under ...";
CM_ SG_ 2566653950 SLIBttrPk1Bttr2SttfChrg "SLI Battery Pack 1 Battery 2 State of Charge: Indicates the remaining charge of the second battery in the first battery pack used for starting the engine, for lighting, and for ignition (SLI). 0% means no charge remaining, 100% means full capacity at...";
CM_ SG_ 2566653950 SLIBttrPk1Snsr2IntlztnStts "SLI Battery Pack 1 Sensor 2 Initialization Status: The battery sensor may go through an initialization process when it is first connected to a battery.  This parameter reports the battery sensor's progress through the initialization process.0 = Initi...";
CM_ BO_ 2566654206 "Vehicle Electrical Power 9";
CM_ SG_ 2566654206 SLIBatteryPack1Battery2Voltage "SLI Battery Pack 1 Battery 2 Voltage: Voltage of the second battery in the first set of batteries (battery pack) used for starting the engine, for lighting, and for ignition (SLI). The relation to physical location is determined by the equipment manu...";
CM_ SG_ 2566654206 SLIBttrPk1Bttr2NtCrrnt "SLI Battery Pack 1 Battery 2 Net Current: Net flow of electrical current into/out of the second battery in the first set of batteries (battery pack) used for starting the engine, for lighting, and for ignition (SLI). ";
CM_ SG_ 2566654206 SLIBttrPk1Bttr2Tmprtr "SLI Battery Pack 1 Battery 2 Temperature: Temperature of the second battery in the first set of batteries (battery pack) used for starting the engine, for lighting, and for ignition (SLI). The relation to physical location is determined by the equipm...";
CM_ BO_ 2566654462 "Vehicle Electrical Power 8";
CM_ SG_ 2566654462 SLIBatteryPack1Battery1Capacity "SLI Battery Pack 1 Battery 1 Capacity: Total reserve capacity of the first battery in the first battery pack used for starting the engine, for lighting, and for ignition (SLI).  This value could be the original capacity, rated capacity, or the capaci...";
CM_ SG_ 2566654462 SLIBatteryPack1Battery1Health "SLI Battery Pack 1 Battery 1 Health: Capacity of the first battery in the first battery pack relative to its original specification for the battery pack used for starting the engine, for lighting, and for ignition (SLI). 0% means battery pack is not ...";
CM_ SG_ 2566654462 SLIBttP1Btt1PdtdMCVt "SLI Battery Pack 1 Battery 1 Predicted Minimum Cranking Voltage: Prediction of the minimum battery voltage of the first battery in the first battery pack used for starting the engine, for lighting, and for ignition (SLI) during a crank event, under p...";
CM_ SG_ 2566654462 SLIBttrPk1Bttr1SttfChrg "SLI Battery Pack 1 Battery 1 State of Charge: Indicates the remaining charge of the first battery in the first battery pack used for starting the engine, for lighting, and for ignition (SLI). 0% means no charge remaining, 100% means full capacity at ...";
CM_ SG_ 2566654462 SLIBttrPk1Snsr1IntlztnStts "SLI Battery Pack 1 Sensor 1 Initialization Status: The battery sensor may go through an initialization process when it is first connected to a battery.  This parameter reports the battery sensor's progress through the initialization process.0 = Initi...";
CM_ BO_ 2566654718 "Vehicle Electrical Power 7";
CM_ SG_ 2566654718 SLIBatteryPack1Battery1Voltage "SLI Battery Pack 1 Battery 1 Voltage: Voltage of the first battery in the first set of batteries (battery pack) used for starting the engine, for lighting, and for ignition (SLI). The relation to physical location is determined by the equipment manuf...";
CM_ SG_ 2566654718 SLIBttrPk1Bttr1NtCrrnt "SLI Battery Pack 1 Battery 1 Net Current: Net flow of electrical current into/out of the first battery in the first set of batteries (battery pack) used for starting the engine, for lighting, and for ignition (SLI). ";
CM_ SG_ 2566654718 SLIBttrPk1Bttr1Tmprtr "SLI Battery Pack 1 Battery 1 Temperature: Temperature of the first battery in the first set of batteries (battery pack) used for starting the engine, for lighting, and for ignition (SLI). The relation to physical location is determined by the equipme...";
CM_ BO_ 2566654974 "Electronic Engine Controller 20";
CM_ SG_ 2566654974 AtlMxmmAvllEngnPrntFl "Actual Maximum Available Engine - Percent Fuel: The percent of torque limited fuel relative to the engine standard torque fuel.  The torque limited fuel in the Actual Maximum Available Engine - Percent Fuel shall take into consideration all engine to...";
CM_ SG_ 2566654974 EsttdEPstLsssPtTqHRst "Estimated Engine Parasitic Losses - Percent Torque (High Resolution): Indicates the estimated amount of torque loss due to engine parasitics, such as cooling fan, air compressor, air conditioning, etc. It is expressed as a percent of Engine Reference...";
CM_ SG_ 2566654974 NmnlFrtnPrntTrqHghRsltn "Nominal Friction Percent Torque (High Resolution): Indicates the amount of torque required by the basic engine itself added by the loss torque of accessories. It contains the frictional and thermodynamic loss of the engine itself, pumping torque loss...";
CM_ BO_ 2566655742 "Primary or Rear Hitch Roll and Pitch Sensitivity";
CM_ SG_ 2566655742 RearHitchPitchSensitivity "Rear Hitch Pitch Sensitivity: The current sensitivity of the rear hitch pitch control expressed as a percentage of the maximum gain.  0% indicates minimal gain in the control loop; 100%, the maximum gain. Values near zero may result in no reaction by...";
CM_ SG_ 2566655742 RearHitchRollSensitivity "Rear Hitch Roll Sensitivity: The current sensitivity of the rear hitch roll control expressed as a percentage of the maximum gain.  0% indicates minimal gain in the control loop; 100%, the maximum gain. Values near zero may result in no reaction by t...";
CM_ BO_ 2566656254 "Ambient Conditions 3";
CM_ SG_ 2566656254 BarometricAbsolutePressure2 "Barometric Absolute Pressure 2: Second absolute air pressure measurement of the atmosphere.See SPN 108 or SPN 5685 as the primary barometric pressure measurement.";
CM_ SG_ 2566656254 EngineIntake2AirTemperature "Engine Intake 2 Air Temperature: Temperature of air entering through a second vehicle air induction system.";
CM_ SG_ 2566656254 EngnPwrDrtRltvHmdtDffrn "Engine Power Derate Relative Humidity Difference: Indicates the current relative humidity compared to available relative humidity before engine power derate occurs.Positive values represents how much relative humidity is available before the derate. ...";
CM_ BO_ 2566656510 "Total Gaseous Fuel Information";
CM_ SG_ 2566656510 EngnTtlGssFlVlmUsd "Engine Total Gaseous Fuel Volume Used: Accumulated volume of engine gaseous fuel used during vehicle operation, in standard cubic meters.See SPN 1040 for alternate units.";
CM_ SG_ 2566656510 EngnTtlGssIdlFlVlmUsd "Engine Total Gaseous Idle Fuel Volume Used: Accumulated volume of engine gaseous fuel used during vehicle operation under idle conditions, in standard cubic meters.";
CM_ BO_ 2566658302 "Payload System Totals 2";
CM_ SG_ 2566658302 TotalPayloadTransactionCount "Total Payload Transaction Count: The accumulated number of completed payload delivery transactions over the life of the product.If transaction status monitoring is supported via Payload Delivery Transaction Status (SPN 7702) then total payload transa...";
CM_ BO_ 2566658558 "Payload System Totals 1";
CM_ SG_ 2566658558 TotalDeliveredPayloadWeight "Total Delivered Payload Weight: The accumulated delivered payload mass over the life of the product.This should be a monotonically increasing number that sums delivered payload weights (SPN 6849) If transactions are supported (Payload Delivery Transa...";
CM_ SG_ 2566658558 TotalHaulCycleCount "Total Haul Cycle Count: The total accumulated number of haul cycles over the life of the product.This should be a monotonically increasing number that sums Haul Cycle Count (SPN 6847). If transactions are supported via Payload Delivery Transaction St...";
CM_ BO_ 2566661118 "Fuel Consumption (Liquid) 2";
CM_ SG_ 2566661118 EngineTotalDieselFuelDemand "Engine Total Diesel Fuel Demand: Accumulated amount of liquid fuel that would have been used during engine operation, including actual diesel fuel used and the diesel fuel that was displaced by gaseous fuel.This is the cumulative value of SPN 7596....";
CM_ BO_ 2566661374 "Aftertreatment 2 Diesel Exhaust Fluid Tank 1 Information 2";
CM_ SG_ 2566661374 Aftrtrtmnt2DslExhstFldTnkHtr2 "Aftertreatment 2 Diesel Exhaust Fluid Tank Heater 2: Percentage of heating applied to the second diesel exhaust fluid tank heater on aftertreatment 2. A value of 0% means no heating applied, a value of 100% means full heating applied. The diesel exha...";
CM_ SG_ 2566661374 Aftrtrtmnt2DslExhstFldTnkVlm2 "Aftertreatment 2 Diesel Exhaust Fluid Tank Volume 2: Second measurement of the ratio of volume of diesel exhaust fluid to the total volume of the diesel exhaust fluid storage container for aftertreatment system 2 (exhaust bank 2).  0% is empty and 10...";
CM_ SG_ 2566661374 Atttt2DsExstFdTTpt2 "Aftertreatment 2 Diesel Exhaust Fluid Tank Temperature 2: The second temperature of aftertreatment 2 diesel exhaust fluid in the storage tank.";
CM_ BO_ 2566661630 "Aftertreatment 1 Diesel Exhaust Fluid Tank 1 Information 2";
CM_ SG_ 2566661630 Aftrtrtmnt1DslExhstFldTnkHtr2 "Aftertreatment 1 Diesel Exhaust Fluid Tank Heater 2: Percentage of heating applied to the second diesel exhaust fluid tank heater on aftertreatment 1. A value of 0% means no heating applied, a value of 100% means full heating applied. The diesel exha...";
CM_ SG_ 2566661630 Aftrtrtmnt1DslExhstFldTnkVlm2 "Aftertreatment 1 Diesel Exhaust Fluid Tank Volume 2: Second measurement of the ratio of volume of diesel exhaust fluid to the total volume of the diesel exhaust fluid storage container for aftertreatment system 1 (exhaust bank 1).  0% is empty and 10...";
CM_ SG_ 2566661630 Atttt1DsExstFdTTpt2 "Aftertreatment 1 Diesel Exhaust Fluid Tank Temperature 2: The second temperature of aftertreatment 1 diesel exhaust fluid in the storage tank.";
CM_ BO_ 2566661886 "Aftertreatment 2 Diesel Exhaust Fluid Information 2";
CM_ SG_ 2566661886 Atttt2DsExstFdCt2Tpt "Aftertreatment 2 Diesel Exhaust Fluid Controller 2 Temperature: Temperature of the diesel exhaust fluid at the aftertreatment 2 diesel exhaust fluid controller 2.";
CM_ SG_ 2566661886 Atttt2DsExstFdCtTpt "Aftertreatment 2 Diesel Exhaust Fluid Controller Temperature: Temperature of the diesel exhaust fluid at the aftertreatment 2 diesel exhaust fluid controller.";
CM_ BO_ 2566662142 "Aftertreatment 1 Diesel Exhaust Fluid Information 2";
CM_ SG_ 2566662142 Atttt1DsExstFdCt1Tpt "Aftertreatment 1 Diesel Exhaust Fluid Controller 1 Temperature: Temperature of the diesel exhaust fluid at the aftertreatment 1 diesel exhaust fluid controller.For controllers that have more exhaust emissions control functions than only diesel exhaus...";
CM_ SG_ 2566662142 Atttt1DsExstFdCt2Tpt "Aftertreatment 1 Diesel Exhaust Fluid Controller 2 Temperature: Temperature of the diesel exhaust fluid at the aftertreatment 1 diesel exhaust fluid controller 2.";
CM_ BO_ 2566662654 "Forward Lane Image 3";
CM_ SG_ 2566662654 LaneDepartureAngleLeft "Lane Departure Angle Left: Angle between left lane mark and vehicle driving direction. The angle is positive while vehicle is moving towards the lane marks, and negative if not. Measured values outside the limits are represented by signal value 251.P...";
CM_ SG_ 2566662654 LaneDepartureAngleRight "Lane Departure Angle Right: Angle between right lane mark and vehicle driving direction. The angle is positive while vehicle is moving towards the lane marks, and negative if not. Measured values outside the limits are represented by signal value 251...";
CM_ SG_ 2566662654 LaneMarkQualityontheLeftSide "Lane Mark Quality on the Left Side: The quality of the nearest lane mark on the left side of the vehicle.000b = no lane marks detected001b = low reliablity of detected lane marks010b = good reliablity of detected lane marks011b = perfect recognition ...";
CM_ SG_ 2566662654 LaneMarkQualityontheRightSide "Lane Mark Quality on the Right Side: The quality of the nearest lane mark on the right side of the vehicle.000b = no lane marks detected001b = low reliablity of detected lane marks010b = good reliablity of detected lane marks011b = perfect recognitio...";
CM_ SG_ 2566662654 LeftLaneMarkerType "Left Lane Marker Type: Indicates the type of lane marker detected by the Forward Lane Imager on the left side. 0000b = Processing or not identified0001b = Solid0010b = Road edge0011b = Dashed0100b = Double lane marker0101b = Raised lane marker (e.g. ...";
CM_ SG_ 2566662654 LftDstntLnMrkfrmVhlsMddl "Left Distance to Lane Mark from Vehicle's Middle: Distance between middle of the vehicle front and the inner/right edge of the nearest lane mark on the left side as measured from the Forward Lane Imager. The value represents the lane width at camera ...";
CM_ SG_ 2566662654 RghtDstntLnMrkfrmVhlsMddl "Right Distance to Lane Mark from Vehicle's Middle: Distance between middle of the vehicle front and the inner/left edge of the nearest lane mark on the right side as measured from the Forward Lane Imager. The value represents the lane width at camera...";
CM_ SG_ 2566662654 RightLaneMarkerType "Right Lane Marker Type: Indicates the type of lane marker detected by the Forward Lane Imager on the right side. 0000b = Processing or not identified0001b = Solid0010b = Road edge0011b = Dashed0100b = Double lane marker0101b = Raised lane marker (e.g...";
CM_ SG_ 2566662654 RoadCurvatureBasedonLaneMarks "Road Curvature Based on Lane Marks: The road curvature parameter is based on lane marks as measured by the FLI.  It is the mean value of the road curvature of the lane marks on the left and right side of the lane. In case one of the lane mark is not ...";
CM_ BO_ 2566662910 "Operator Inducement Information";
CM_ SG_ 2566662910 OprtrIndmntTmtFnlIndmntAtn "Operator Inducement Time to Final Inducement Action: Indicates the time until the inducement strategy enforces the final level of engine emissions operator inducement. The final level of inducement can include derating the engine, shutting down the e...";
CM_ SG_ 2566662910 OprtrIndmntTmtTrqDrtLvl1 "Operator Inducement Time to Torque Derate Level 1: This parameter provides the time until Operator Inducement Torque Derate Level 1 (SPN 7425) is activated.When operator inducement is not active, this parameter will be set to FB00h. For systems where...";
CM_ SG_ 2566662910 OprtrIndmntTmtTrqDrtLvl2 "Operator Inducement Time to Torque Derate Level 2: This parameter provides the time until Operator Inducement Torque Derate Level 2 (SPN 7427) is activated.When operator inducement is not active or if a second level of derate does not exist, then thi...";
CM_ SG_ 2566662910 OprtrIndmntTrqDrtLvl1 "Operator Inducement Torque Derate Level 1: This is the first torque derate that will be applied to the engine operation due to operator inducement.  The torque derate indicated in this parameter will be active when the value in Operator Inducement Ti...";
CM_ SG_ 2566662910 OprtrIndmntTrqDrtLvl2 "Operator Inducement Torque Derate Level 2: This is the second torque derate that will be applied to the engine operation due to operator inducement. The torque derate level indicated in this parameter will be applied when the value in Operator Induce...";
CM_ BO_ 2566663166 "Cruise Control / Vehicle Speed 4";
CM_ SG_ 2566663166 AppldVhlSpdLmtHghRsltn "Applied Vehicle Speed Limit (High Resolution): The vehicle speed limit in effect.See SPN 2595 for alternate resolution.Note:  If a maximum vehicle speed limit is not selected, then the first byte of this parameter will be equal to FBh.";
CM_ SG_ 2566663166 CrsCntrlAdjstdMxmmSpd "Cruise Control Adjusted Maximum Speed: Present maximum vehicle velocity at which cruise can be set. This parameter is expected to change during run-time due to functionality that could influence the behavior of the cruise control algorithm. This func...";
CM_ SG_ 2566663166 EngnExtrnlIdlRqstFdk "Engine External Idle Request  Feedback: Indicates that the engine is altering the idle speed due to a request from an external source. 00b = No Idle Alteration Active - standard idle speed01b = Idle Alteration Active10b = Error11b = Not available...";
CM_ SG_ 2566663166 SAddssCtDvSttCsCt "Source Address of Controlling Device for Setting Cruise Control: The source address of the SAE J1939 device that is currently sending the Cruise Control Set Command (SPN 9843).If there are multiple devices sending Cruise Control Set Command with a va...";
CM_ BO_ 2566663422 "Brake Caliper Lining Clearance";
CM_ SG_ 2566663422 TrlrBrkClprLnngClrnAxl1Lft "Trailer Brake Caliper Lining Clearance Axle 1 Left: Brake caliper lining clearance for left brake on trailer axle 1.00b = Caliper lining clearance is adequate01b = Caliper lining clearance is low10b = Error11b = Not available / not applicable...";
CM_ SG_ 2566663422 TrlrBrkClprLnngClrnAxl1Rght "Trailer Brake Caliper Lining Clearance Axle 1 Right: Brake caliper lining clearance for right brake on trailer axle 1.00b = Caliper lining clearance is adequate01b = Caliper lining clearance is low10b = Error11b = Not available / not applicable...";
CM_ SG_ 2566663422 TrlrBrkClprLnngClrnAxl2Lft "Trailer Brake Caliper Lining Clearance Axle 2 Left: Brake caliper lining clearance for left brake on trailer axle 2.00b = Caliper lining clearance is adequate01b = Caliper lining clearance is low10b = Error11b = Not available / not applicable...";
CM_ SG_ 2566663422 TrlrBrkClprLnngClrnAxl2Rght "Trailer Brake Caliper Lining Clearance Axle 2 Right: Brake caliper lining clearance for right brake on trailer axle 2.00b = Caliper lining clearance is adequate01b = Caliper lining clearance is low10b = Error11b = Not available / not applicable...";
CM_ SG_ 2566663422 TrlrBrkClprLnngClrnAxl3Lft "Trailer Brake Caliper Lining Clearance Axle 3 Left: Brake caliper lining clearance for left brake on trailer axle 3.00b = Caliper lining clearance is adequate01b = Caliper lining clearance is low10b = Error11b = Not available / not applicable...";
CM_ SG_ 2566663422 TrlrBrkClprLnngClrnAxl3Rght "Trailer Brake Caliper Lining Clearance Axle 3 Right: Brake caliper lining clearance for right brake on trailer axle 3.00b = Caliper lining clearance is adequate01b = Caliper lining clearance is low10b = Error11b = Not available / not applicable...";
CM_ SG_ 2566663422 TrlrBrkClprLnngClrnAxl4Lft "Trailer Brake Caliper Lining Clearance Axle 4 Left: Brake caliper lining clearance for left brake on trailer axle 4.00b = Caliper lining clearance is adequate01b = Caliper lining clearance is low10b = Error11b = Not available / not applicable...";
CM_ SG_ 2566663422 TrlrBrkClprLnngClrnAxl4Rght "Trailer Brake Caliper Lining Clearance Axle 4 Right: Brake caliper lining clearance for right brake on trailer axle 4.00b = Caliper lining clearance is adequate01b = Caliper lining clearance is low10b = Error11b = Not available / not applicable...";
CM_ SG_ 2566663422 TrlrBrkClprLnngClrnAxl5Lft "Trailer Brake Caliper Lining Clearance Axle 5 Left: Brake caliper lining clearance for left brake on trailer axle 5.00b = Caliper lining clearance is adequate01b = Caliper lining clearance is low10b = Error11b = Not available / not applicable...";
CM_ SG_ 2566663422 TrlrBrkClprLnngClrnAxl5Rght "Trailer Brake Caliper Lining Clearance Axle 5 Right: Brake caliper lining clearance for right brake on trailer axle 5.00b = Caliper lining clearance is adequate01b = Caliper lining clearance is low10b = Error11b = Not available / not applicable...";
CM_ SG_ 2566663422 TrtrBrkClprLnngClrnAxl1Lft "Tractor Brake Caliper Lining Clearance Axle 1 Left: Brake caliper lining clearance for left brake on tractor axle 1.00b = Caliper lining clearance is adequate01b = Caliper lining clearance is low10b = Error11b = Not available / not applicable...";
CM_ SG_ 2566663422 TrtrBrkClprLnngClrnAxl1Rght "Tractor Brake Caliper Lining Clearance Axle 1 Right: Brake caliper lining clearance for right brake on tractor axle 1.00b = Caliper lining clearance is adequate01b = Caliper lining clearance is low10b = Error11b = Not available / not applicable...";
CM_ SG_ 2566663422 TrtrBrkClprLnngClrnAxl2Lft "Tractor Brake Caliper Lining Clearance Axle 2 Left: Brake caliper lining clearance for left brake on tractor axle 2.00b = Caliper lining clearance is adequate01b = Caliper lining clearance is low10b = Error11b = Not available / not applicable...";
CM_ SG_ 2566663422 TrtrBrkClprLnngClrnAxl2Rght "Tractor Brake Caliper Lining Clearance Axle 2 Right: Brake caliper lining clearance for right brake on tractor axle 2.00b = Caliper lining clearance is adequate01b = Caliper lining clearance is low10b = Error11b = Not available / not applicable...";
CM_ SG_ 2566663422 TrtrBrkClprLnngClrnAxl3Lft "Tractor Brake Caliper Lining Clearance Axle 3 Left: Brake caliper lining clearance for left brake on tractor axle 3.00b = Caliper lining clearance is adequate01b = Caliper lining clearance is low10b = Error11b = Not available / not applicable...";
CM_ SG_ 2566663422 TrtrBrkClprLnngClrnAxl3Rght "Tractor Brake Caliper Lining Clearance Axle 3 Right: Brake caliper lining clearance for right brake on tractor axle 3.00b = Caliper lining clearance is adequate01b = Caliper lining clearance is low10b = Error11b = Not available / not applicable...";
CM_ SG_ 2566663422 TrtrBrkClprLnngClrnAxl4Lft "Tractor Brake Caliper Lining Clearance Axle 4 Left: Brake caliper lining clearance for left brake on tractor axle 4.00b = Caliper lining clearance is adequate01b = Caliper lining clearance is low10b = Error11b = Not available / not applicable...";
CM_ SG_ 2566663422 TrtrBrkClprLnngClrnAxl4Rght "Tractor Brake Caliper Lining Clearance Axle 4 Right: Brake caliper lining clearance for right brake on tractor axle 4.00b = Caliper lining clearance is adequate01b = Caliper lining clearance is low10b = Error11b = Not available / not applicable...";
CM_ SG_ 2566663422 TrtrBrkClprLnngClrnAxl5Lft "Tractor Brake Caliper Lining Clearance Axle 5 Left: Brake caliper lining clearance for left brake on tractor axle 5.00b = Caliper lining clearance is adequate01b = Caliper lining clearance is low10b = Error11b = Not available / not applicable...";
CM_ SG_ 2566663422 TrtrBrkClprLnngClrnAxl5Rght "Tractor Brake Caliper Lining Clearance Axle 5 Right: Brake caliper lining clearance for right brake on tractor axle 5.00b = Caliper lining clearance is adequate01b = Caliper lining clearance is low10b = Error11b = Not available / not applicable...";
CM_ BO_ 2566663678 "Alternate Fuel 5";
CM_ SG_ 2566663678 EngnFl2InjtrMtrngRl1Tmprtr2 "Engine Fuel 2 Injector Metering Rail 1 Temperature 2: The second temperature of fuel 2 measured by first rail temperature sensor in the primary, or first, metering rail as delivered from the supply pump to the injector metering intake.";
CM_ SG_ 2566663678 LNGTank1VaporPressure "LNG Tank 1 Vapor Pressure: Gage pressure of the vapor in the first tank in a multi-tank system (or unique tank if single-tank system).";
CM_ SG_ 2566663678 LNGTank2VaporPressure "LNG Tank 2 Vapor Pressure: Gage pressure of the vapor in the second tank in a multi-tank system.";
CM_ BO_ 2566663934 "Engine Turbocharger Control 3";
CM_ SG_ 2566663934 EngnClndrHdBpssAttr1MtrCrrntDsl "Engine Cylinder Head Bypass Actuator 1 Motor Current Disable: Command to disable power to motor in the actuator to prevent unnecessary load on the component.00b = Do Not Disable01b = Disable10b = Reserved11b = Don't Care/Take No Action";
CM_ SG_ 2566663934 EngnThrttlVlv1MtrCrrntDsl "Engine Throttle Valve 1 Motor Current Disable: Command to disable power to motor in the actuator to prevent unnecessary load on the component.00b = Do Not Disable01b = Disable10b = Reserved11b = Don't Care/Take No Action";
CM_ SG_ 2566663934 EngnTrhrgrWstgtAttr1MtrCrrntDsl "Engine Turbocharger Wastegate Actuator 1 Motor Current Disable: Command to disable power to motor in the actuator to prevent unnecessary load on the component.00b = Do Not Disable01b = Disable10b = Reserved11b = Don't Care/Take No Action";
CM_ SG_ 2566663934 EngnTrhrgrWstgtAttr2MtrCrrntDsl "Engine Turbocharger Wastegate Actuator 2 Motor Current Disable: Command to disable power to motor in wastegate actuator 2 to prevent unnecessary load on the component.00b = Do Not Disable01b = Disable10b = Reserved11b = Don't Care/Take No Action...";
CM_ SG_ 2566663934 ETCpssBpssAtt1MtCtDs "Engine Turbocharger Compressor Bypass Actuator 1 Motor Current Disable: Command to disable power to motor in bypass actuator 1 to prevent unnecessary load on the component.00b = Do Not Disable01b = Disable10b = Reserved11b = Don't Care/Take No Action...";
CM_ SG_ 2566663934 ETCpssBpssAtt2MtCtDs "Engine Turbocharger Compressor Bypass Actuator 2 Motor Current Disable: Command to disable power to motor in bypass actuator 2 to prevent unnecessary load on the component.00b = Do Not Disable01b = Disable10b = Reserved11b = Don't Care/Take No Action...";
CM_ SG_ 2566663934 ETCpssBwAtt1MtCtDs "Engine Turbocharger Compressor Blowoff Actuator 1 Motor Current Disable: Command to disable power to motor in the actuator to prevent unnecessary load on the component.00b = Do Not Disable01b = Disable10b = Reserved11b = Don't Care/Take No Action...";
CM_ BO_ 2566664702 "Aftertreatment System Information 1";
CM_ SG_ 2566664702 AftertreatmentEngineLoadRequest "Aftertreatment Engine Load Request: Indicates whether the aftertreatment desires engine load to be applied. This is meant to notify the operator that the aftertreatment is requesting engine load for thermal purposes.The operator is expected to add lo...";
CM_ SG_ 2566664702 AftrtrtmntAmntArTmprtr "Aftertreatment Ambient Air Temperature: Temperature of ambient air near the aftertreatment components such as DEF tank and DEF lines.";
CM_ SG_ 2566664702 AftrtrtmntDslExhstFldHtrCrtBrkr "Aftertreatment Diesel Exhaust Fluid Heater Circuit Breaker: The status of the circuit breaker that is used to heat the diesel exhaust fluid.00b = off01b = on10b = error11b = not available";
CM_ SG_ 2566664702 AftrtrtmntDslExhstFldTnkTmprtr "Aftertreatment Diesel Exhaust Fluid Tank Temperature: The derived diesel exhaust fluid tank temperature in applications with multiple temperature sensors in a single tank. The SP data will be derived from all temperature sensors in the tank.Note: Thi...";
CM_ SG_ 2566664702 AftrtrtmntDslExhstFldTnkVlm "Aftertreatment Diesel Exhaust Fluid Tank Volume: The derived diesel exhaust fluid tank volume in applications with multiple level sensors in a single tank. The SP data will be derived from all level sensors in the tank.Note: This SP can be derived fr...";
CM_ SG_ 2566664702 AftrtrtmntEngnSpdInrsrqst "Aftertreatment Engine Speed Increase request: Indicates whether the aftertreatment desires engine speed control in order to increase the engine speed. This is meant to notify the operator that the aftertreatment is requesting an increase in engine sp...";
CM_ SG_ 2566664702 AftrtrtmntThrmlMngmntStts "Aftertreatment Thermal Management Status: Indicates whether Aftertreatment Thermal Management process is active.Aftertreatment Thermal Management indicates that the exhaust temperatures have been controlled for the normal functioning of the aftertrea...";
CM_ SG_ 2566664702 AttttAtvRtItdDtLwExstPss "Aftertreatment Active Regeneration Inhibited Due to Low Exhaust Pressure: The state of aftertreatment active regeneration inhibition due to low exhaust pressure.Aftertreatment Regeneration is a process of increasing the temperature at the exhaust and...";
CM_ SG_ 2566664702 DslExhstFldQltMlfntnEvltnPrdAtv "Diesel Exhaust Fluid Quality Malfunction Evaluation Period Active: This parameter is used to notify the operator that a DEF Quality and DEF Level evaluation period, also known as a judgement period, is currently active.The judgement period is require...";
CM_ SG_ 2566664702 AftrtrtmntSCRDsngMdStts "Aftertreatment SCR Dosing Mode Status: Indicates that the aftertreatment system is dosing in standard or reduced mode.Standard indicates that the system will dose at maximum capacity where the reduced mode will dose at minimum capacity  (e.g., IMO 3 ...";
CM_ SG_ 2566664702 DPFAtvRgnrtnTmRmnng "DPF Active Regeneration Time Remaining: Indicates approximate remaining time of the parked active DPF Regeneration. This time is not for passive regeneration.If active regeneration is not in progress, this parameter shall respond with FBh.";
CM_ BO_ 2566665726 "Aftertreatment 2 Diesel Exhaust Fluid Pump 1 Information";
CM_ SG_ 2566665726 Aftrtrtmnt2DslExhstFldPmpHtr "Aftertreatment 2 Diesel Exhaust Fluid Pump Heater: Percentage of heating applied to the aftertreatment 2 diesel exhaust fluid pump heater.  A value of 0% means no heating applied, a value of 100% means full heating applied. The diesel exhaust fluid p...";
CM_ SG_ 2566665726 Atttt2DsExstFdPp2MtSpd "Aftertreatment 2 Diesel Exhaust Fluid Pump 2 Motor Speed: Rotational speed of the motor driving the second pump for the diesel exhaust fluid used in aftertreatment system 2 (exhaust bank 2).";
CM_ BO_ 2566667262 "Engine End Bearing Temperature 3";
CM_ SG_ 2566667262 EngineEndBearing17Temperature "Engine End Bearing 17 Temperature: Temperature of end bearing of the connecting rod for cylinder 17 on the engine";
CM_ SG_ 2566667262 EngineEndBearing18Temperature "Engine End Bearing 18 Temperature: Temperature of end bearing of the connecting rod for cylinder 18 on the engine";
CM_ SG_ 2566667262 EngineEndBearing19Temperature "Engine End Bearing 19 Temperature: Temperature of end bearing of the connecting rod for cylinder 19 on the engine";
CM_ SG_ 2566667262 EngineEndBearing20Temperature "Engine End Bearing 20 Temperature: Temperature of end bearing of the connecting rod for cylinder 20 on the engine";
CM_ BO_ 2566667518 "Engine End Bearing Temperature 2";
CM_ SG_ 2566667518 EngineEndBearing10Temperature "Engine End Bearing 10 Temperature: Temperature of end bearing of the connecting rod for cylinder 10 on the engine";
CM_ SG_ 2566667518 EngineEndBearing11Temperature "Engine End Bearing 11 Temperature: Temperature of end bearing of the connecting rod for cylinder 11 on the engine";
CM_ SG_ 2566667518 EngineEndBearing12Temperature "Engine End Bearing 12 Temperature: Temperature of end bearing of the connecting rod for cylinder 12 on the engine";
CM_ SG_ 2566667518 EngineEndBearing13Temperature "Engine End Bearing 13 Temperature: Temperature of end bearing of the connecting rod for cylinder 13 on the engine";
CM_ SG_ 2566667518 EngineEndBearing14Temperature "Engine End Bearing 14 Temperature: Temperature of end bearing of the connecting rod for cylinder 14 on the engine";
CM_ SG_ 2566667518 EngineEndBearing15Temperature "Engine End Bearing 15 Temperature: Temperature of end bearing of the connecting rod for cylinder 15 on the engine";
CM_ SG_ 2566667518 EngineEndBearing16Temperature "Engine End Bearing 16 Temperature: Temperature of end bearing of the connecting rod for cylinder 16 on the engine";
CM_ SG_ 2566667518 EngineEndBearing9Temperature "Engine End Bearing 9 Temperature: Temperature of end bearing of the connecting rod for cylinder 9 on the engine";
CM_ BO_ 2566667774 "Engine End Bearing Temperature 1";
CM_ SG_ 2566667774 EngineEndBearing1Temperature "Engine End Bearing 1 Temperature: Temperature of end bearing of the connecting rod for cylinder 1 on the engine";
CM_ SG_ 2566667774 EngineEndBearing2Temperature "Engine End Bearing 2 Temperature: Temperature of end bearing of the connecting rod for cylinder 2 on the engine";
CM_ SG_ 2566667774 EngineEndBearing3Temperature "Engine End Bearing 3 Temperature: Temperature of end bearing of the connecting rod for cylinder 3 on the engine";
CM_ SG_ 2566667774 EngineEndBearing4Temperature "Engine End Bearing 4 Temperature: Temperature of end bearing of the connecting rod for cylinder 4 on the engine";
CM_ SG_ 2566667774 EngineEndBearing5Temperature "Engine End Bearing 5 Temperature: Temperature of end bearing of the connecting rod for cylinder 5 on the engine";
CM_ SG_ 2566667774 EngineEndBearing6Temperature "Engine End Bearing 6 Temperature: Temperature of end bearing of the connecting rod for cylinder 6 on the engine";
CM_ SG_ 2566667774 EngineEndBearing7Temperature "Engine End Bearing 7 Temperature: Temperature of end bearing of the connecting rod for cylinder 7 on the engine";
CM_ SG_ 2566667774 EngineEndBearing8Temperature "Engine End Bearing 8 Temperature: Temperature of end bearing of the connecting rod for cylinder 8 on the engine";
CM_ BO_ 2566668030 "Heat Exchanger Debris Purge Information";
CM_ SG_ 2566668030 HeatExchangerDebrisPurgeStatus "Heat Exchanger Debris Purge Status: Indicates whether the system is currently purging debris from the heat exchanger.00b = Inactive01b = Active10b = SAE reserved11b = Not available";
CM_ SG_ 2566668030 HtExhngrDrsPrgApprhng "Heat Exchanger Debris Purge Approaching: Status signal which indicates that purging the debris from the heat exchanger is imminent.00b = Not approaching01b = Approaching10b = SAE reserved11b = Not available";
CM_ BO_ 2566668286 "Engine Turbocharger Control 2";
CM_ SG_ 2566668286 EngnStgdTrhrgrSlndStts "Engine Staged Turbocharger Solenoid Status: Current state of the staged turbocharger solenoid, normalized to percent, 0% represents not actuated and 100% represents fully actuated.";
CM_ BO_ 2566668542 "Engine Hydraulic Fuel 2 Pump Status";
CM_ SG_ 2566668542 EngnFl2PmpHdrlDrtnlVlv "Engine Fuel 2 Pump Hydraulic Directional Valve: Position of hydraulic directional valve to control application of hydraulic oil flow.  0% is no flow to the appliance; 100% is full flow to the appliance.";
CM_ SG_ 2566668542 EngnFl2PmpHdrlFlwCntrlVlv "Engine Fuel 2 Pump Hydraulic Flow Control Valve: Position of hydraulic pump flow control valve opening; 0% = fully closed, 100% = fully open.";
CM_ SG_ 2566668542 EngnFl2PmpHdrlPrssr "Engine Fuel 2 Pump Hydraulic Pressure: Hydraulic pressure in the lines of the hydraulically driven fuel 2 pump.";
CM_ SG_ 2566668542 EngnFl2PmpHdrlSwshPltAngl "Engine Fuel 2 Pump Hydraulic Swash Plate Angle: Position of hydraulic swash plate angle within hydraulic pump.  0% represents the lowest possible flow, 100% represents the maximum flow.";
CM_ BO_ 2566668798 "Alternate Fuel 4";
CM_ SG_ 2566668798 EngnFl2InjtrMtrngRl1Prssr "Engine Fuel 2 Injector Metering Rail 1 Pressure: The pressure of fuel 2 measured by first rail pressure sensor in the primary, or first, metering rail as delivered from the supply pump to the injector metering intake.";
CM_ SG_ 2566668798 EngnFl2InjtrMtrngRl1Prssr2 "Engine Fuel 2 Injector Metering Rail 1 Pressure 2: The second pressure of fuel 2 measured by first rail pressure sensor in the primary, or first, metering rail as delivered from the supply pump to the injector metering intake.";
CM_ SG_ 2566668798 EngnFl2InjtrMtrngRl1Tmprtr "Engine Fuel 2 Injector Metering Rail 1 Temperature: The temperature of fuel 2 measured by first rail temperature sensor in the primary, or first, metering rail as delivered from the supply pump to the injector metering intake.";
CM_ SG_ 2566668798 EngnFl2InjtrMtrngRl2Prssr "Engine Fuel 2 Injector Metering Rail 2 Pressure: The pressure of fuel 2 measured by first rail pressure sensor in the metering rail 2 as delivered from the supply pump to the injector metering intake.";
CM_ SG_ 2566668798 EngnFl2InjtrMtrngRl2Tmprtr "Engine Fuel 2 Injector Metering Rail 2 Temperature: The temperature of fuel 2 measured by first rail temperature sensor in the metering rail 2 as delivered from the supply pump to the injector metering intake.";
CM_ BO_ 2566669054 "Tire Condition Message 2";
CM_ SG_ 2566669054 RequiredTirePressure "Required Tire Pressure: The required tire pressure at which air is contained in cavity formed by tire and rim.This pressure of the tire is compensated to meet the specific physical environmental conditions (temperature) of the vehicle.";
CM_ SG_ 2566669054 TireLocation "Tire Location: Identifies which tire is associated with the parametric data in PGN 64578. Refer to SPN 929 for further details and examples. The low order 4 bits represent a position number, counting left to right when facing in the direction of norm...";
CM_ SG_ 2566669054 TirePressureExtendedRange "Tire Pressure (Extended Range): Pressure at which air is contained in cavity formed by tire and rim. See SPN 241 for alternate tire pressure with a lower range and coarser resolution.";
CM_ BO_ 2566669310 "Tire Configuration Status Information";
CM_ SG_ 2566669310 ColdInflationPressure "Cold Inflation Pressure: The cold inflation pressure of the tire. Cold inflation pressure is the default/reference inflation pressure suggested by the manufacturer for a specific tire.";
CM_ SG_ 2566669310 ExtrmUndrPrssrPrntgThrshld "Extreme Under Pressure Percentage Threshold: The percentage deviation from the set cold inflation pressure, for the extreme under tire pressure alert.";
CM_ SG_ 2566669310 OverPressurePercentageThreshold "Over Pressure Percentage Threshold: The percentage deviation from the set cold inflation pressure, for the over tire pressure alert.";
CM_ SG_ 2566669310 OverTemperature "Over Temperature: The temperature above which the over temperature alert will trigger.";
CM_ SG_ 2566669310 TireLocation "Tire Location: The location of monitored tire on the vehicle.The high order 4 bits indicate the vehicle axle position of the tire sensor, counting front to back on the vehicle, with the value 0 representing the front axle on the vehicle.The low order...";
CM_ SG_ 2566669310 UndrPrssrPrntgThrshld "Under Pressure Percentage Threshold: The percentage deviation from the set cold inflation pressure, for the under tire pressure alert.";
CM_ BO_ 2566669822 "Tire Wireless Signal Strength Indicator";
CM_ SG_ 2566669822 AntennaNumber "Antenna Number: Number of the antenna used to communicate signal strength of a group of sensors.  If a single antenna is used this will default to 01h. When multiple antennas are used, the first antenna will have a value of 1, 2nd antenna will be 2, ...";
CM_ SG_ 2566669822 TireLocation "Tire Location: The location of monitored tire on the vehicle.The high order 4 bits indicate the vehicle axle position of the tire sensor, counting front to back on the vehicle, with the value 0 representing the front axle on the vehicle.The low order...";
CM_ SG_ 2566669822 TireSensorNumber "Tire Sensor Number: The number of the monitored tire sensor that corresponds with the tire wireless signal strength indicator. The location of the numbered tire is reported in the tire sensor location SP (SPN 6965). The value FFh indicates this SP is...";
CM_ SG_ 2566669822 TotalNumberofAntennasUsed "Total Number of Antennas Used: Total count of antennas used in the specified vehicle system.";
CM_ SG_ 2566669822 TrWrlssSgnlStrngthIndtr "Tire Wireless Signal Strength Indicator: The wireless signal strength between the tire pressure sensor and the specified antenna, for the tire specified in the tire sensor number or tire sensor Location.";
CM_ SG_ 2566669822 TtlNmrfTrSnsrsMntrd "Total Number of Tire Sensors Monitored: Total number of tire sensors monitored for the specified antenna in this instance of the parameter group.";
CM_ BO_ 2566670078 "Tire Sensor Identification Status";
CM_ SG_ 2566670078 NumberofTireSensors "Number of Tire Sensors: Total count of monitored tire sensor identification numbers represented in this instance of the parameter group.";
CM_ SG_ 2566670078 TireLocation "Tire Location: The location of monitored tire that corresponds with the Tire Sensor Identification Number (SPN 6966). In order to specify the monitored tire by tire number, use the Tire Number SPN 6964.The high order 4 bits indicate the vehicle axle ...";
CM_ SG_ 2566670078 TireNumber "Tire Number: The number of the monitored tire that corresponds with the Tire Sensor Identification Number (SPN 6966).  In order to specify the monitored tire by location, use the Tire Location SPN 6965.The value FFh indicates this SP is not used.";
CM_ SG_ 2566670078 TireSensorIdentificationNumber "Tire Sensor Identification Number: The identification number of the tire specified in the tire number (SPN 6964) or tire location (SPN 6965).";
BA_DEF_ SG_  "SPN" INT 0 524287;
BA_DEF_ BO_  "VFrameFormat" ENUM  "StandardCAN","ExtendedCAN","reserved","J1939PG";
BA_DEF_DEF_  "SPN" 0;
BA_DEF_DEF_  "VFrameFormat" "J1939PG";
BA_ "SPN" SG_ 2566631678 DCACAssIvt5ACSdDtFqCdStt 9557;
BA_ "SPN" SG_ 2566631678 DCACAssIvt5ACSdRMSCtMxLtStt 9364;
BA_ "SPN" SG_ 2566631678 DCACAssIvt5ACSdRMSVtMxLtStt 9363;
BA_ "SPN" SG_ 2566631678 DCACAssIvt5DCSdCtMLtStt 9556;
BA_ "SPN" SG_ 2566631678 DCACAssIvt5DCSdCtMxLtStt 9362;
BA_ "SPN" SG_ 2566631678 DCACAssIvt5DCSdVtMLtStt 9361;
BA_ "SPN" SG_ 2566631678 DCACAssIvt5DCSdVtMxLtStt 9555;
BA_ "SPN" SG_ 2566631934 DCACAssrInvrtr5TtlDCInptChrg 9365;
BA_ "SPN" SG_ 2566631934 DCACAssrInvrtr5TtlDCInptEnrg 9366;
BA_ "SPN" SG_ 2566632190 WllStmltnPmpStnPrssrClrtnStPnt 9193;
BA_ "SPN" SG_ 2566632190 WSttPpDsPssCtStPt 9195;
BA_ "SPN" SG_ 2566632190 WSttPpDsPssCtStPtStts 9196;
BA_ "SPN" SG_ 2566632190 WSttPpStPssCtStPtStts 9194;
BA_ "SPN" SG_ 2566632446 WllStmltnPmpTrpFldPmpd 9192;
BA_ "SPN" SG_ 2566632446 WllStmltnPmpTtlFldPmpd 9191;
BA_ "SPN" SG_ 2566632702 WllStmltnPmpFldEndSrlNmr 9190;
BA_ "SPN" SG_ 2566632702 WllStmltnPmpPwrEndSrlNmr 9189;
BA_ "SPN" SG_ 2566632958 WllStmltnPmpFldEndTrpHrs 9187;
BA_ "SPN" SG_ 2566632958 WllStmltnPmpPwrEndTrpHrs 9188;
BA_ "SPN" SG_ 2566633214 Aftrtrtmnt1OtltOxgnPmpngCrrnt 9178;
BA_ "SPN" SG_ 2566633214 Atttt1OttNOxSsPttAPssAst 12908;
BA_ "SPN" SG_ 2566633470 Aftrtrtmnt1IntkOxgnPmpngCrrnt 9177;
BA_ "SPN" SG_ 2566633470 Atttt1ItNOxSsPttAPssAst 12907;
BA_ "SPN" SG_ 2566633726 DCDC4TotalHighSideCharge 9032;
BA_ "SPN" SG_ 2566633726 DCDC4TotalHighSideEnergy 9030;
BA_ "SPN" SG_ 2566633726 DCDC4TotalLowSideCharge 9033;
BA_ "SPN" SG_ 2566633726 DCDC4TotalLowSideEnergy 9031;
BA_ "SPN" SG_ 2566633982 DCDC4HghSdCrrntMxmmLmtSttng 9036;
BA_ "SPN" SG_ 2566633982 DCDC4HghSdVltgMnmmLmtSttng 9034;
BA_ "SPN" SG_ 2566633982 DCDC4HghSdVltgMxmmLmtSttng 9035;
BA_ "SPN" SG_ 2566633982 DCDC4LwSdCrrntMxmmLmtSttng 9039;
BA_ "SPN" SG_ 2566633982 DCDC4LwSdVltgBkDfltSttng 9522;
BA_ "SPN" SG_ 2566633982 DCDC4LwSdVltgMnmmLmtSttng 9037;
BA_ "SPN" SG_ 2566633982 DCDC4LwSdVltgMxmmLmtSttng 9038;
BA_ "SPN" SG_ 2566633982 DCDC4SLIBttrTmprtrMxmmLmtSttng 9042;
BA_ "SPN" SG_ 2566633982 DCDC4SLIBttTCCtMxLtStt 9041;
BA_ "SPN" SG_ 2566633982 DCDC4SLIBttTVtMxLtStt 9040;
BA_ "SPN" SG_ 2566635262 DCDC3TotalHighSideCharge 8977;
BA_ "SPN" SG_ 2566635262 DCDC3TotalHighSideEnergy 8975;
BA_ "SPN" SG_ 2566635262 DCDC3TotalLowSideCharge 8978;
BA_ "SPN" SG_ 2566635262 DCDC3TotalLowSideEnergy 8976;
BA_ "SPN" SG_ 2566635518 DCDC3HghSdCrrntMxmmLmtSttng 8981;
BA_ "SPN" SG_ 2566635518 DCDC3HghSdVltgMnmmLmtSttng 8979;
BA_ "SPN" SG_ 2566635518 DCDC3HghSdVltgMxmmLmtSttng 8980;
BA_ "SPN" SG_ 2566635518 DCDC3LwSdCrrntMxmmLmtSttng 8984;
BA_ "SPN" SG_ 2566635518 DCDC3LwSdVltgBkDfltSttng 9521;
BA_ "SPN" SG_ 2566635518 DCDC3LwSdVltgMnmmLmtSttng 8982;
BA_ "SPN" SG_ 2566635518 DCDC3LwSdVltgMxmmLmtSttng 8983;
BA_ "SPN" SG_ 2566635518 DCDC3SLIBttrTmprtrMxmmLmtSttng 8987;
BA_ "SPN" SG_ 2566635518 DCDC3SLIBttTCCtMxLtStt 8986;
BA_ "SPN" SG_ 2566635518 DCDC3SLIBttTVtMxLtStt 8985;
BA_ "SPN" SG_ 2566636798 DCDC2TotalHighSideCharge 8922;
BA_ "SPN" SG_ 2566636798 DCDC2TotalHighSideEnergy 8920;
BA_ "SPN" SG_ 2566636798 DCDC2TotalLowSideCharge 8923;
BA_ "SPN" SG_ 2566636798 DCDC2TotalLowSideEnergy 8921;
BA_ "SPN" SG_ 2566637054 DCDC2HghSdCrrntMxmmLmtSttng 8926;
BA_ "SPN" SG_ 2566637054 DCDC2HghSdVltgMnmmLmtSttng 8924;
BA_ "SPN" SG_ 2566637054 DCDC2HghSdVltgMxmmLmtSttng 8925;
BA_ "SPN" SG_ 2566637054 DCDC2LwSdCrrntMxmmLmtSttng 8929;
BA_ "SPN" SG_ 2566637054 DCDC2LwSdVltgBkDfltSttng 9520;
BA_ "SPN" SG_ 2566637054 DCDC2LwSdVltgMnmmLmtSttng 8927;
BA_ "SPN" SG_ 2566637054 DCDC2LwSdVltgMxmmLmtSttng 8928;
BA_ "SPN" SG_ 2566637054 DCDC2SLIBttrTmprtrMxmmLmtSttng 8932;
BA_ "SPN" SG_ 2566637054 DCDC2SLIBttTCCtMxLtStt 8931;
BA_ "SPN" SG_ 2566637054 DCDC2SLIBttTVtMxLtStt 8930;
BA_ "SPN" SG_ 2566638590 ExhstPrtltCntrlSstmDgnstCnt 8888;
BA_ "SPN" SG_ 2566638590 ExhstPrtltCntrlSstmDgnstTm 8887;
BA_ "SPN" SG_ 2566638846 WllStmltnPmpMntnnIntrvlHrs 8882;
BA_ "SPN" SG_ 2566638846 WllStmltnPmpPkngOprtnHrs 8884;
BA_ "SPN" SG_ 2566638846 WllStmltnPmpVlvOprtnHrs 8883;
BA_ "SPN" SG_ 2566638846 WllStmltnPmpVlvStOprtnHrs 8885;
BA_ "SPN" SG_ 2566639102 WllStmltnPmpPlngrFrngOrdrSttng 8881;
BA_ "SPN" SG_ 2566639102 WllStmltnPmpRdLdHghThrshldSttng 8880;
BA_ "SPN" SG_ 2566639102 WSttPpCstSpdHTsdStt 8879;
BA_ "SPN" SG_ 2566639102 WSttPpCstSpdLwTsdStt 8878;
BA_ "SPN" SG_ 2566639102 WSttPpDsPssHTsdStt 8877;
BA_ "SPN" SG_ 2566639102 WSttPpGBxOPssHTsdStt 8872;
BA_ "SPN" SG_ 2566639102 WSttPpGBxOPssLwTsdStt 8871;
BA_ "SPN" SG_ 2566639102 WSttPpGBxOTptHTsdStt 8874;
BA_ "SPN" SG_ 2566639102 WSttPpGBxOTptLwTsdStt 8873;
BA_ "SPN" SG_ 2566639102 WSttPpStPssHTsdStt 8876;
BA_ "SPN" SG_ 2566639102 WSttPpStPssLwTsdStt 8875;
BA_ "SPN" SG_ 2566639614 DCDC1TotalHighSideCharge 8835;
BA_ "SPN" SG_ 2566639614 DCDC1TotalHighSideEnergy 8833;
BA_ "SPN" SG_ 2566639614 DCDC1TotalLowSideCharge 8836;
BA_ "SPN" SG_ 2566639614 DCDC1TotalLowSideEnergy 8834;
BA_ "SPN" SG_ 2566639870 DCDC1HghSdCrrntMxmmLmtSttng 8826;
BA_ "SPN" SG_ 2566639870 DCDC1HghSdVltgMnmmLmtSttng 8824;
BA_ "SPN" SG_ 2566639870 DCDC1HghSdVltgMxmmLmtSttng 8825;
BA_ "SPN" SG_ 2566639870 DCDC1LwSdCrrntMxmmLmtSttng 8829;
BA_ "SPN" SG_ 2566639870 DCDC1LwSdVltgBkDfltSttng 9519;
BA_ "SPN" SG_ 2566639870 DCDC1LwSdVltgMnmmLmtSttng 8827;
BA_ "SPN" SG_ 2566639870 DCDC1LwSdVltgMxmmLmtSttng 8828;
BA_ "SPN" SG_ 2566639870 DCDC1SLIBttrTmprtrMxmmLmtSttng 8832;
BA_ "SPN" SG_ 2566639870 DCDC1SLIBttTCCtMxLtStt 8831;
BA_ "SPN" SG_ 2566639870 DCDC1SLIBttTVtMxLtStt 8830;
BA_ "SPN" SG_ 2566640382 WellStimulationPumpOilDensity 8661;
BA_ "SPN" SG_ 2566640382 WellStimulationPumpOilViscosity 8660;
BA_ "SPN" SG_ 2566640382 WllStmltnPmpOlRltvDltrt 8662;
BA_ "SPN" SG_ 2566640382 WllStmltnPmpOlTmprtr 8663;
BA_ "SPN" SG_ 2566641150 AltrntrBrngHdrIntkPrssr 8635;
BA_ "SPN" SG_ 2566641150 AltrntrOlClrDshrgPmpPrssr 8636;
BA_ "SPN" SG_ 2566641150 EngnOlClrDshrgPmpPrssr 8637;
BA_ "SPN" SG_ 2566641150 EngnOlClrIntkTmprtr 8638;
BA_ "SPN" SG_ 2566641406 EngnExhstMnfldAsltPrssr1 8619;
BA_ "SPN" SG_ 2566641406 EngnExhstMnfldAsltPrssr2 8620;
BA_ "SPN" SG_ 2566642942 EnableStatusofDoor21 8527;
BA_ "SPN" SG_ 2566642942 EnableStatusofDoor22 8530;
BA_ "SPN" SG_ 2566642942 EnableStatusofDoor23 8533;
BA_ "SPN" SG_ 2566642942 EnableStatusofDoor24 8536;
BA_ "SPN" SG_ 2566642942 EnableStatusofDoor25 8539;
BA_ "SPN" SG_ 2566642942 EnableStatusofDoor26 8542;
BA_ "SPN" SG_ 2566642942 EnableStatusofDoor27 8545;
BA_ "SPN" SG_ 2566642942 EnableStatusofDoor28 8548;
BA_ "SPN" SG_ 2566642942 EnableStatusofDoor29 8551;
BA_ "SPN" SG_ 2566642942 EnableStatusofDoor30 8554;
BA_ "SPN" SG_ 2566642942 LockStatusofDoor21 8525;
BA_ "SPN" SG_ 2566642942 LockStatusofDoor22 8528;
BA_ "SPN" SG_ 2566642942 LockStatusofDoor23 8531;
BA_ "SPN" SG_ 2566642942 LockStatusofDoor24 8534;
BA_ "SPN" SG_ 2566642942 LockStatusofDoor25 8537;
BA_ "SPN" SG_ 2566642942 LockStatusofDoor26 8540;
BA_ "SPN" SG_ 2566642942 LockStatusofDoor27 8543;
BA_ "SPN" SG_ 2566642942 LockStatusofDoor28 8546;
BA_ "SPN" SG_ 2566642942 LockStatusofDoor29 8549;
BA_ "SPN" SG_ 2566642942 LockStatusofDoor30 8552;
BA_ "SPN" SG_ 2566642942 OpenStatusofDoor21 8526;
BA_ "SPN" SG_ 2566642942 OpenStatusofDoor22 8529;
BA_ "SPN" SG_ 2566642942 OpenStatusofDoor23 8532;
BA_ "SPN" SG_ 2566642942 OpenStatusofDoor24 8535;
BA_ "SPN" SG_ 2566642942 OpenStatusofDoor25 8538;
BA_ "SPN" SG_ 2566642942 OpenStatusofDoor26 8541;
BA_ "SPN" SG_ 2566642942 OpenStatusofDoor27 8544;
BA_ "SPN" SG_ 2566642942 OpenStatusofDoor28 8547;
BA_ "SPN" SG_ 2566642942 OpenStatusofDoor29 8550;
BA_ "SPN" SG_ 2566642942 OpenStatusofDoor30 8553;
BA_ "SPN" SG_ 2566643198 EnableStatusofDoor11 8497;
BA_ "SPN" SG_ 2566643198 EnableStatusofDoor12 8500;
BA_ "SPN" SG_ 2566643198 EnableStatusofDoor13 8503;
BA_ "SPN" SG_ 2566643198 EnableStatusofDoor14 8506;
BA_ "SPN" SG_ 2566643198 EnableStatusofDoor15 8509;
BA_ "SPN" SG_ 2566643198 EnableStatusofDoor16 8512;
BA_ "SPN" SG_ 2566643198 EnableStatusofDoor17 8515;
BA_ "SPN" SG_ 2566643198 EnableStatusofDoor18 8518;
BA_ "SPN" SG_ 2566643198 EnableStatusofDoor19 8521;
BA_ "SPN" SG_ 2566643198 EnableStatusofDoor20 8524;
BA_ "SPN" SG_ 2566643198 LockStatusofDoor11 8495;
BA_ "SPN" SG_ 2566643198 LockStatusofDoor12 8498;
BA_ "SPN" SG_ 2566643198 LockStatusofDoor13 8501;
BA_ "SPN" SG_ 2566643198 LockStatusofDoor14 8504;
BA_ "SPN" SG_ 2566643198 LockStatusofDoor15 8507;
BA_ "SPN" SG_ 2566643198 LockStatusofDoor16 8510;
BA_ "SPN" SG_ 2566643198 LockStatusofDoor17 8513;
BA_ "SPN" SG_ 2566643198 LockStatusofDoor18 8516;
BA_ "SPN" SG_ 2566643198 LockStatusofDoor19 8519;
BA_ "SPN" SG_ 2566643198 LockStatusofDoor20 8522;
BA_ "SPN" SG_ 2566643198 OpenStatusofDoor11 8496;
BA_ "SPN" SG_ 2566643198 OpenStatusofDoor12 8499;
BA_ "SPN" SG_ 2566643198 OpenStatusofDoor13 8502;
BA_ "SPN" SG_ 2566643198 OpenStatusofDoor14 8505;
BA_ "SPN" SG_ 2566643198 OpenStatusofDoor15 8508;
BA_ "SPN" SG_ 2566643198 OpenStatusofDoor16 8511;
BA_ "SPN" SG_ 2566643198 OpenStatusofDoor17 8514;
BA_ "SPN" SG_ 2566643198 OpenStatusofDoor18 8517;
BA_ "SPN" SG_ 2566643198 OpenStatusofDoor19 8520;
BA_ "SPN" SG_ 2566643198 OpenStatusofDoor20 8523;
BA_ "SPN" SG_ 2566643454 EngineIntakeCoolantTemperature 8489;
BA_ "SPN" SG_ 2566643454 EngnChrgArClrIntkClntTmprtr 8487;
BA_ "SPN" SG_ 2566643454 EngnChrgArClrOtltClntTmprtr 8488;
BA_ "SPN" SG_ 2566643454 EItMdAtSdCtCtCtDtTpt 12306;
BA_ "SPN" SG_ 2566643710 EngineMixer1IntakePressure 8477;
BA_ "SPN" SG_ 2566643710 EngineMixer2IntakePressure 8607;
BA_ "SPN" SG_ 2566643710 EngnIntkMnfld2AsltPrssrHghRsltn 11731;
BA_ "SPN" SG_ 2566643710 DsrdEngnIntkMnfldPrssrHghLmt 12307;
BA_ "SPN" SG_ 2566644990 DrvrSdFlRptl1CvrStts 8415;
BA_ "SPN" SG_ 2566644990 DrvrSdFlRptl2CvrStts 8416;
BA_ "SPN" SG_ 2566644990 FlStrgCmprtmnt1Tmprtr1 8420;
BA_ "SPN" SG_ 2566644990 FlStrgCmprtmnt1Tmprtr2 8421;
BA_ "SPN" SG_ 2566644990 FlStrgCmprtmnt2Tmprtr1 8422;
BA_ "SPN" SG_ 2566644990 FlStrgCmprtmnt2Tmprtr2 8423;
BA_ "SPN" SG_ 2566644990 FlStrgCmprtmnt3Tmprtr1 8424;
BA_ "SPN" SG_ 2566644990 FlStrgCmprtmnt3Tmprtr2 8425;
BA_ "SPN" SG_ 2566644990 FrontFuelReceptacleCoverStatus 8419;
BA_ "SPN" SG_ 2566644990 PssngrSdFlRptl1CvrStts 8417;
BA_ "SPN" SG_ 2566644990 PssngrSdFlRptl2CvrStts 8418;
BA_ "SPN" SG_ 2566645246 HVESSFanEnableStatus 8403;
BA_ "SPN" SG_ 2566645246 HVESSFanStatusReasonCode 8404;
BA_ "SPN" SG_ 2566645246 HVESSFanCommandStatus 8405;
BA_ "SPN" SG_ 2566645246 HVESSFanSpeed 8406;
BA_ "SPN" SG_ 2566645246 HVESSFanMediumTemperature 8407;
BA_ "SPN" SG_ 2566645246 HVESSFanPower 8408;
BA_ "SPN" SG_ 2566645246 HVESSFanServiceIndicator 8409;
BA_ "SPN" SG_ 2566645246 HVESSFanOperatingStatus 8410;
BA_ "SPN" SG_ 2566645246 HVESSFanInstance 8411;
BA_ "SPN" SG_ 2566646782 OlDrsMntrFrrsBn1Cnt 8168;
BA_ "SPN" SG_ 2566646782 OlDrsMntrFrrsBn2Cnt 8169;
BA_ "SPN" SG_ 2566646782 OlDrsMntrFrrsBns1nd2IdntftnNmr 8167;
BA_ "SPN" SG_ 2566647038 OlDrsMntrFrrsBn3Cnt 8171;
BA_ "SPN" SG_ 2566647038 OlDrsMntrFrrsBn4Cnt 8172;
BA_ "SPN" SG_ 2566647038 OlDrsMntrFrrsBns3nd4IdntftnNmr 8170;
BA_ "SPN" SG_ 2566647294 OlDrsMntrFrrsBn5Cnt 8174;
BA_ "SPN" SG_ 2566647294 OlDrsMntrFrrsBn6Cnt 8175;
BA_ "SPN" SG_ 2566647294 OlDrsMntrFrrsBns5nd6IdntftnNmr 8173;
BA_ "SPN" SG_ 2566647550 ODsMtNFsBs1d2IdttN 8176;
BA_ "SPN" SG_ 2566647550 OlDrsMntrNnFrrsBn1Cnt 8177;
BA_ "SPN" SG_ 2566647550 OlDrsMntrNnFrrsBn2Cnt 8178;
BA_ "SPN" SG_ 2566647806 ODsMtNFsBs3d4IdttN 8179;
BA_ "SPN" SG_ 2566647806 OlDrsMntrNnFrrsBn3Cnt 8180;
BA_ "SPN" SG_ 2566647806 OlDrsMntrNnFrrsBn4Cnt 8181;
BA_ "SPN" SG_ 2566648062 ODsMtNFsBs5d6IdttN 8182;
BA_ "SPN" SG_ 2566648062 OlDrsMntrNnFrrsBn5Cnt 8183;
BA_ "SPN" SG_ 2566648062 OlDrsMntrNnFrrsBn6Cnt 8184;
BA_ "SPN" SG_ 2566648318 OlDrsMntrEltrnsTmprtrStts 8190;
BA_ "SPN" SG_ 2566648318 OlDrsMntrEnvrnmntStts 8187;
BA_ "SPN" SG_ 2566648318 OlDrsMntrSgnlPrssngEltrnsStts 8189;
BA_ "SPN" SG_ 2566648318 OlDrsMntrSnsngElmntStts 8188;
BA_ "SPN" SG_ 2566648318 OlDrsMntrSttsIdntftnNmr 8185;
BA_ "SPN" SG_ 2566648318 OlDrsMntrTtlnmrfSnsrs 8186;
BA_ "SPN" SG_ 2566649086 Atttt2DOCIttDPFOttDtPss 8165;
BA_ "SPN" SG_ 2566649086 Atttt2DsOxdtCtstItPss 8163;
BA_ "SPN" SG_ 2566649086 Atttt2DsOxdtCtstOttPss 8164;
BA_ "SPN" SG_ 2566649342 Atttt1DOCIttDPFOttDtPss 8162;
BA_ "SPN" SG_ 2566649342 Atttt1DsOxdtCtstItPss 8160;
BA_ "SPN" SG_ 2566649342 Atttt1DsOxdtCtstOttPss 8161;
BA_ "SPN" SG_ 2566649598 HorizontalDilutionofPrecision 8129;
BA_ "SPN" SG_ 2566649598 PositionDilutionofPrecision 8131;
BA_ "SPN" SG_ 2566649598 TimeDilutionofPrecision 8132;
BA_ "SPN" SG_ 2566649598 TotalNumberofSatellitesinView 8128;
BA_ "SPN" SG_ 2566649598 VerticalDilutionofPrecision 8130;
BA_ "SPN" SG_ 2566649854 PpsMtCtF3CtCdStts 8069;
BA_ "SPN" SG_ 2566649854 PpsMtCtF3CtSttsRsCd 8068;
BA_ "SPN" SG_ 2566649854 PropulsionMotorCoolantFan3Power 8072;
BA_ "SPN" SG_ 2566649854 PrplsnMtrClntFn3CntrlTmprtr 8071;
BA_ "SPN" SG_ 2566649854 PrplsnMtrClntFn3EnlStts 8067;
BA_ "SPN" SG_ 2566649854 PrplsnMtrClntFn3MtrSpd 8070;
BA_ "SPN" SG_ 2566649854 PrplsnMtrClntFn3OprtngStts 8074;
BA_ "SPN" SG_ 2566649854 PrplsnMtrClntFn3SrvIndtr 8073;
BA_ "SPN" SG_ 2566650110 PpsMtCtF2CtCdStts 8057;
BA_ "SPN" SG_ 2566650110 PpsMtCtF2CtSttsRsCd 8056;
BA_ "SPN" SG_ 2566650110 PropulsionMotorCoolantFan2Power 8060;
BA_ "SPN" SG_ 2566650110 PrplsnMtrClntFn2CntrlTmprtr 8059;
BA_ "SPN" SG_ 2566650110 PrplsnMtrClntFn2EnlStts 8055;
BA_ "SPN" SG_ 2566650110 PrplsnMtrClntFn2MtrSpd 8058;
BA_ "SPN" SG_ 2566650110 PrplsnMtrClntFn2OprtngStts 8062;
BA_ "SPN" SG_ 2566650110 PrplsnMtrClntFn2SrvIndtr 8061;
BA_ "SPN" SG_ 2566650366 PpsMtCtF1CtCdStts 8045;
BA_ "SPN" SG_ 2566650366 PpsMtCtF1CtSttsRsCd 8044;
BA_ "SPN" SG_ 2566650366 PropulsionMotorCoolantFan1Power 8048;
BA_ "SPN" SG_ 2566650366 PrplsnMtrClntFn1CntrlTmprtr 8047;
BA_ "SPN" SG_ 2566650366 PrplsnMtrClntFn1EnlStts 8043;
BA_ "SPN" SG_ 2566650366 PrplsnMtrClntFn1MtrSpd 8046;
BA_ "SPN" SG_ 2566650366 PrplsnMtrClntFn1OprtngStts 8050;
BA_ "SPN" SG_ 2566650366 PrplsnMtrClntFn1SrvIndtr 8049;
BA_ "SPN" SG_ 2566650622 PwEtsCtF3CtCdStts 8033;
BA_ "SPN" SG_ 2566650622 PwEtsCtF3CtSttsRsCd 8032;
BA_ "SPN" SG_ 2566650622 PwrEltrnsClntFn3CntrlTmprtr 8035;
BA_ "SPN" SG_ 2566650622 PwrEltrnsClntFn3EnlStts 8031;
BA_ "SPN" SG_ 2566650622 PwrEltrnsClntFn3MtrSpd 8034;
BA_ "SPN" SG_ 2566650622 PwrEltrnsClntFn3OprtngStts 8038;
BA_ "SPN" SG_ 2566650622 PwrEltrnsClntFn3Pwr 8036;
BA_ "SPN" SG_ 2566650622 PwrEltrnsClntFn3SrvIndtr 8037;
BA_ "SPN" SG_ 2566650878 PwEtsCtF2CtCdStts 8021;
BA_ "SPN" SG_ 2566650878 PwEtsCtF2CtSttsRsCd 8020;
BA_ "SPN" SG_ 2566650878 PwrEltrnsClntFn2CntrlTmprtr 8023;
BA_ "SPN" SG_ 2566650878 PwrEltrnsClntFn2EnlStts 8019;
BA_ "SPN" SG_ 2566650878 PwrEltrnsClntFn2MtrSpd 8022;
BA_ "SPN" SG_ 2566650878 PwrEltrnsClntFn2OprtngStts 8026;
BA_ "SPN" SG_ 2566650878 PwrEltrnsClntFn2Pwr 8024;
BA_ "SPN" SG_ 2566650878 PwrEltrnsClntFn2SrvIndtr 8025;
BA_ "SPN" SG_ 2566651134 PwEtsCtF1CtCdStts 8009;
BA_ "SPN" SG_ 2566651134 PwEtsCtF1CtSttsRsCd 8008;
BA_ "SPN" SG_ 2566651134 PwrEltrnsClntFn1CntrlTmprtr 8011;
BA_ "SPN" SG_ 2566651134 PwrEltrnsClntFn1EnlStts 8007;
BA_ "SPN" SG_ 2566651134 PwrEltrnsClntFn1MtrSpd 8010;
BA_ "SPN" SG_ 2566651134 PwrEltrnsClntFn1OprtngStts 8014;
BA_ "SPN" SG_ 2566651134 PwrEltrnsClntFn1Pwr 8012;
BA_ "SPN" SG_ 2566651134 PwrEltrnsClntFn1SrvIndtr 8013;
BA_ "SPN" SG_ 2566651390 PropulsionMotorOilPumpPower 8000;
BA_ "SPN" SG_ 2566651390 PrplsnMtrOlPmpCntrllrCmmndStts 7997;
BA_ "SPN" SG_ 2566651390 PrplsnMtrOlPmpCntrllrSttsRsnCd 7996;
BA_ "SPN" SG_ 2566651390 PrplsnMtrOlPmpCntrlTmprtr 7999;
BA_ "SPN" SG_ 2566651390 PrplsnMtrOlPmpEnlStts 7995;
BA_ "SPN" SG_ 2566651390 PrplsnMtrOlPmpMtrSpd 7998;
BA_ "SPN" SG_ 2566651390 PrplsnMtrOlPmpOprtngStts 8002;
BA_ "SPN" SG_ 2566651390 PrplsnMtrOlPmpSrvIndtr 8001;
BA_ "SPN" SG_ 2566651646 PpsMtCtPpCtCdStts 7985;
BA_ "SPN" SG_ 2566651646 PpsMtCtPpCtSttsRsCd 7984;
BA_ "SPN" SG_ 2566651646 PropulsionMotorCoolantPumpPower 7988;
BA_ "SPN" SG_ 2566651646 PrplsnMtrClntPmpCntrlTmprtr 7987;
BA_ "SPN" SG_ 2566651646 PrplsnMtrClntPmpEnlStts 7983;
BA_ "SPN" SG_ 2566651646 PrplsnMtrClntPmpMtrSpd 7986;
BA_ "SPN" SG_ 2566651646 PrplsnMtrClntPmpOprtngStts 7990;
BA_ "SPN" SG_ 2566651646 PrplsnMtrClntPmpSrvIndtr 7989;
BA_ "SPN" SG_ 2566651902 PwEtsCtPpCtCdStts 7973;
BA_ "SPN" SG_ 2566651902 PwEtsCtPpCtSttsRsCd 7972;
BA_ "SPN" SG_ 2566651902 PwrEltrnsClntPmpCntrlTmprtr 7975;
BA_ "SPN" SG_ 2566651902 PwrEltrnsClntPmpEnlStts 7971;
BA_ "SPN" SG_ 2566651902 PwrEltrnsClntPmpMtrSpd 7974;
BA_ "SPN" SG_ 2566651902 PwrEltrnsClntPmpOprtngStts 7978;
BA_ "SPN" SG_ 2566651902 PwrEltrnsClntPmpPwr 7976;
BA_ "SPN" SG_ 2566651902 PwrEltrnsClntPmpSrvIndtr 7977;
BA_ "SPN" SG_ 2566652414 ElectrifiedAccessoryMotorPower 7952;
BA_ "SPN" SG_ 2566652414 ElectrifiedAccessoryMotorSpeed 7950;
BA_ "SPN" SG_ 2566652414 EltrfdAssrMtrCntrllrCmmndStts 7949;
BA_ "SPN" SG_ 2566652414 EltrfdAssrMtrCntrllrSttsRsnCd 7948;
BA_ "SPN" SG_ 2566652414 EltrfdAssrMtrEnlStts 7947;
BA_ "SPN" SG_ 2566652414 EltrfdAssrMtrInstn 8308;
BA_ "SPN" SG_ 2566652414 EltrfdAssrMtrMdmTmprtr 7951;
BA_ "SPN" SG_ 2566652414 EltrfdAssrMtrOprtngStts 7954;
BA_ "SPN" SG_ 2566652414 EltrfdAssrMtrSrvIndtr 7953;
BA_ "SPN" SG_ 2566652670 Atttt1DsExstFdDsSstFz 6802;
BA_ "SPN" SG_ 2566652670 Atttt2DsExstFdDsSstFz 6803;
BA_ "SPN" SG_ 2566652670 DieselExhaustFluidFrozenTime 7938;
BA_ "SPN" SG_ 2566652670 Aftrtrtmnt1SstmHdrrn 7934;
BA_ "SPN" SG_ 2566652670 Aftrtrtmnt2SstmHdrrn 7935;
BA_ "SPN" SG_ 2566652926 SLIBatteryPack1Battery4Capacity 7928;
BA_ "SPN" SG_ 2566652926 SLIBatteryPack1Battery4Health 7929;
BA_ "SPN" SG_ 2566652926 SLIBttP1Btt4PdtdMCVt 7930;
BA_ "SPN" SG_ 2566652926 SLIBttrPk1Bttr4SttfChrg 7927;
BA_ "SPN" SG_ 2566652926 SLIBttrPk1Snsr4IntlztnStts 7931;
BA_ "SPN" SG_ 2566653182 SLIBatteryPack1Battery4Voltage 7926;
BA_ "SPN" SG_ 2566653182 SLIBttrPk1Bttr4NtCrrnt 7924;
BA_ "SPN" SG_ 2566653182 SLIBttrPk1Bttr4Tmprtr 7925;
BA_ "SPN" SG_ 2566653438 SLIBatteryPack1Battery3Capacity 7920;
BA_ "SPN" SG_ 2566653438 SLIBatteryPack1Battery3Health 7921;
BA_ "SPN" SG_ 2566653438 SLIBttP1Btt3PdtdMCVt 7922;
BA_ "SPN" SG_ 2566653438 SLIBttrPk1Bttr3SttfChrg 7919;
BA_ "SPN" SG_ 2566653438 SLIBttrPk1Snsr3IntlztnStts 7923;
BA_ "SPN" SG_ 2566653694 SLIBatteryPack1Battery3Voltage 7918;
BA_ "SPN" SG_ 2566653694 SLIBttrPk1Bttr3NtCrrnt 7916;
BA_ "SPN" SG_ 2566653694 SLIBttrPk1Bttr3Tmprtr 7917;
BA_ "SPN" SG_ 2566653950 SLIBatteryPack1Battery2Capacity 7912;
BA_ "SPN" SG_ 2566653950 SLIBatteryPack1Battery2Health 7913;
BA_ "SPN" SG_ 2566653950 SLIBttP1Btt2PdtdMCVt 7914;
BA_ "SPN" SG_ 2566653950 SLIBttrPk1Bttr2SttfChrg 7911;
BA_ "SPN" SG_ 2566653950 SLIBttrPk1Snsr2IntlztnStts 7915;
BA_ "SPN" SG_ 2566654206 SLIBatteryPack1Battery2Voltage 7910;
BA_ "SPN" SG_ 2566654206 SLIBttrPk1Bttr2NtCrrnt 7908;
BA_ "SPN" SG_ 2566654206 SLIBttrPk1Bttr2Tmprtr 7909;
BA_ "SPN" SG_ 2566654462 SLIBatteryPack1Battery1Capacity 7904;
BA_ "SPN" SG_ 2566654462 SLIBatteryPack1Battery1Health 7905;
BA_ "SPN" SG_ 2566654462 SLIBttP1Btt1PdtdMCVt 7906;
BA_ "SPN" SG_ 2566654462 SLIBttrPk1Bttr1SttfChrg 7903;
BA_ "SPN" SG_ 2566654462 SLIBttrPk1Snsr1IntlztnStts 7907;
BA_ "SPN" SG_ 2566654718 SLIBatteryPack1Battery1Voltage 7902;
BA_ "SPN" SG_ 2566654718 SLIBttrPk1Bttr1NtCrrnt 7900;
BA_ "SPN" SG_ 2566654718 SLIBttrPk1Bttr1Tmprtr 7901;
BA_ "SPN" SG_ 2566654974 AtlMxmmAvllEngnPrntFl 8630;
BA_ "SPN" SG_ 2566654974 EsttdEPstLsssPtTqHRst 7837;
BA_ "SPN" SG_ 2566654974 NmnlFrtnPrntTrqHghRsltn 12926;
BA_ "SPN" SG_ 2566655742 RearHitchPitchSensitivity 7813;
BA_ "SPN" SG_ 2566655742 RearHitchRollSensitivity 7812;
BA_ "SPN" SG_ 2566656254 BarometricAbsolutePressure2 7781;
BA_ "SPN" SG_ 2566656254 EngineIntake2AirTemperature 7850;
BA_ "SPN" SG_ 2566656254 EngnPwrDrtRltvHmdtDffrn 12852;
BA_ "SPN" SG_ 2566656510 EngnTtlGssFlVlmUsd 7455;
BA_ "SPN" SG_ 2566656510 EngnTtlGssIdlFlVlmUsd 7456;
BA_ "SPN" SG_ 2566658302 TotalPayloadTransactionCount 7701;
BA_ "SPN" SG_ 2566658558 TotalDeliveredPayloadWeight 7699;
BA_ "SPN" SG_ 2566658558 TotalHaulCycleCount 7700;
BA_ "SPN" SG_ 2566661118 EngineTotalDieselFuelDemand 7597;
BA_ "SPN" SG_ 2566661374 Aftrtrtmnt2DslExhstFldTnkHtr2 7575;
BA_ "SPN" SG_ 2566661374 Aftrtrtmnt2DslExhstFldTnkVlm2 7531;
BA_ "SPN" SG_ 2566661374 Atttt2DsExstFdTTpt2 7574;
BA_ "SPN" SG_ 2566661630 Aftrtrtmnt1DslExhstFldTnkHtr2 7573;
BA_ "SPN" SG_ 2566661630 Aftrtrtmnt1DslExhstFldTnkVlm2 7530;
BA_ "SPN" SG_ 2566661630 Atttt1DsExstFdTTpt2 7572;
BA_ "SPN" SG_ 2566661886 Atttt2DsExstFdCt2Tpt 7535;
BA_ "SPN" SG_ 2566661886 Atttt2DsExstFdCtTpt 7529;
BA_ "SPN" SG_ 2566662142 Atttt1DsExstFdCt1Tpt 5480;
BA_ "SPN" SG_ 2566662142 Atttt1DsExstFdCt2Tpt 7528;
BA_ "SPN" SG_ 2566662654 LaneDepartureAngleLeft 7479;
BA_ "SPN" SG_ 2566662654 LaneDepartureAngleRight 7480;
BA_ "SPN" SG_ 2566662654 LaneMarkQualityontheLeftSide 7481;
BA_ "SPN" SG_ 2566662654 LaneMarkQualityontheRightSide 7482;
BA_ "SPN" SG_ 2566662654 LeftLaneMarkerType 8144;
BA_ "SPN" SG_ 2566662654 LftDstntLnMrkfrmVhlsMddl 7476;
BA_ "SPN" SG_ 2566662654 RghtDstntLnMrkfrmVhlsMddl 7477;
BA_ "SPN" SG_ 2566662654 RightLaneMarkerType 8143;
BA_ "SPN" SG_ 2566662654 RoadCurvatureBasedonLaneMarks 7478;
BA_ "SPN" SG_ 2566662910 OprtrIndmntTmtFnlIndmntAtn 7719;
BA_ "SPN" SG_ 2566662910 OprtrIndmntTmtTrqDrtLvl1 7426;
BA_ "SPN" SG_ 2566662910 OprtrIndmntTmtTrqDrtLvl2 7428;
BA_ "SPN" SG_ 2566662910 OprtrIndmntTrqDrtLvl1 7425;
BA_ "SPN" SG_ 2566662910 OprtrIndmntTrqDrtLvl2 7427;
BA_ "SPN" SG_ 2566663166 AppldVhlSpdLmtHghRsltn 7420;
BA_ "SPN" SG_ 2566663166 CrsCntrlAdjstdMxmmSpd 7495;
BA_ "SPN" SG_ 2566663166 EngnExtrnlIdlRqstFdk 8441;
BA_ "SPN" SG_ 2566663166 SAddssCtDvSttCsCt 9844;
BA_ "SPN" SG_ 2566663422 TrlrBrkClprLnngClrnAxl1Lft 7406;
BA_ "SPN" SG_ 2566663422 TrlrBrkClprLnngClrnAxl1Rght 7407;
BA_ "SPN" SG_ 2566663422 TrlrBrkClprLnngClrnAxl2Lft 7408;
BA_ "SPN" SG_ 2566663422 TrlrBrkClprLnngClrnAxl2Rght 7409;
BA_ "SPN" SG_ 2566663422 TrlrBrkClprLnngClrnAxl3Lft 7410;
BA_ "SPN" SG_ 2566663422 TrlrBrkClprLnngClrnAxl3Rght 7411;
BA_ "SPN" SG_ 2566663422 TrlrBrkClprLnngClrnAxl4Lft 7412;
BA_ "SPN" SG_ 2566663422 TrlrBrkClprLnngClrnAxl4Rght 7413;
BA_ "SPN" SG_ 2566663422 TrlrBrkClprLnngClrnAxl5Lft 7414;
BA_ "SPN" SG_ 2566663422 TrlrBrkClprLnngClrnAxl5Rght 7415;
BA_ "SPN" SG_ 2566663422 TrtrBrkClprLnngClrnAxl1Lft 7396;
BA_ "SPN" SG_ 2566663422 TrtrBrkClprLnngClrnAxl1Rght 7397;
BA_ "SPN" SG_ 2566663422 TrtrBrkClprLnngClrnAxl2Lft 7398;
BA_ "SPN" SG_ 2566663422 TrtrBrkClprLnngClrnAxl2Rght 7399;
BA_ "SPN" SG_ 2566663422 TrtrBrkClprLnngClrnAxl3Lft 7400;
BA_ "SPN" SG_ 2566663422 TrtrBrkClprLnngClrnAxl3Rght 7401;
BA_ "SPN" SG_ 2566663422 TrtrBrkClprLnngClrnAxl4Lft 7402;
BA_ "SPN" SG_ 2566663422 TrtrBrkClprLnngClrnAxl4Rght 7403;
BA_ "SPN" SG_ 2566663422 TrtrBrkClprLnngClrnAxl5Lft 7404;
BA_ "SPN" SG_ 2566663422 TrtrBrkClprLnngClrnAxl5Rght 7405;
BA_ "SPN" SG_ 2566663678 EngnFl2InjtrMtrngRl1Tmprtr2 7514;
BA_ "SPN" SG_ 2566663678 LNGTank1VaporPressure 6787;
BA_ "SPN" SG_ 2566663678 LNGTank2VaporPressure 6788;
BA_ "SPN" SG_ 2566663934 EngnClndrHdBpssAttr1MtrCrrntDsl 7382;
BA_ "SPN" SG_ 2566663934 EngnThrttlVlv1MtrCrrntDsl 7383;
BA_ "SPN" SG_ 2566663934 EngnTrhrgrWstgtAttr1MtrCrrntDsl 7381;
BA_ "SPN" SG_ 2566663934 EngnTrhrgrWstgtAttr2MtrCrrntDsl 7710;
BA_ "SPN" SG_ 2566663934 ETCpssBpssAtt1MtCtDs 7708;
BA_ "SPN" SG_ 2566663934 ETCpssBpssAtt2MtCtDs 7709;
BA_ "SPN" SG_ 2566663934 ETCpssBwAtt1MtCtDs 7380;
BA_ "SPN" SG_ 2566664702 AftertreatmentEngineLoadRequest 7503;
BA_ "SPN" SG_ 2566664702 AftrtrtmntAmntArTmprtr 7441;
BA_ "SPN" SG_ 2566664702 AftrtrtmntDslExhstFldHtrCrtBrkr 7588;
BA_ "SPN" SG_ 2566664702 AftrtrtmntDslExhstFldTnkTmprtr 7607;
BA_ "SPN" SG_ 2566664702 AftrtrtmntDslExhstFldTnkVlm 7606;
BA_ "SPN" SG_ 2566664702 AftrtrtmntEngnSpdInrsrqst 7502;
BA_ "SPN" SG_ 2566664702 AftrtrtmntThrmlMngmntStts 7332;
BA_ "SPN" SG_ 2566664702 AttttAtvRtItdDtLwExstPss 7440;
BA_ "SPN" SG_ 2566664702 DslExhstFldQltMlfntnEvltnPrdAtv 7899;
BA_ "SPN" SG_ 2566664702 AftrtrtmntSCRDsngMdStts 9176;
BA_ "SPN" SG_ 2566664702 DPFAtvRgnrtnTmRmnng 10156;
BA_ "SPN" SG_ 2566665726 Aftrtrtmnt2DslExhstFldPmpHtr 7086;
BA_ "SPN" SG_ 2566665726 Atttt2DsExstFdPp2MtSpd 7466;
BA_ "SPN" SG_ 2566667262 EngineEndBearing17Temperature 7059;
BA_ "SPN" SG_ 2566667262 EngineEndBearing18Temperature 7060;
BA_ "SPN" SG_ 2566667262 EngineEndBearing19Temperature 7061;
BA_ "SPN" SG_ 2566667262 EngineEndBearing20Temperature 7062;
BA_ "SPN" SG_ 2566667518 EngineEndBearing10Temperature 7052;
BA_ "SPN" SG_ 2566667518 EngineEndBearing11Temperature 7053;
BA_ "SPN" SG_ 2566667518 EngineEndBearing12Temperature 7054;
BA_ "SPN" SG_ 2566667518 EngineEndBearing13Temperature 7055;
BA_ "SPN" SG_ 2566667518 EngineEndBearing14Temperature 7056;
BA_ "SPN" SG_ 2566667518 EngineEndBearing15Temperature 7057;
BA_ "SPN" SG_ 2566667518 EngineEndBearing16Temperature 7058;
BA_ "SPN" SG_ 2566667518 EngineEndBearing9Temperature 7051;
BA_ "SPN" SG_ 2566667774 EngineEndBearing1Temperature 7043;
BA_ "SPN" SG_ 2566667774 EngineEndBearing2Temperature 7044;
BA_ "SPN" SG_ 2566667774 EngineEndBearing3Temperature 7045;
BA_ "SPN" SG_ 2566667774 EngineEndBearing4Temperature 7046;
BA_ "SPN" SG_ 2566667774 EngineEndBearing5Temperature 7047;
BA_ "SPN" SG_ 2566667774 EngineEndBearing6Temperature 7048;
BA_ "SPN" SG_ 2566667774 EngineEndBearing7Temperature 7049;
BA_ "SPN" SG_ 2566667774 EngineEndBearing8Temperature 7050;
BA_ "SPN" SG_ 2566668030 HeatExchangerDebrisPurgeStatus 7035;
BA_ "SPN" SG_ 2566668030 HtExhngrDrsPrgApprhng 7036;
BA_ "SPN" SG_ 2566668286 EngnStgdTrhrgrSlndStts 7025;
BA_ "SPN" SG_ 2566668542 EngnFl2PmpHdrlDrtnlVlv 7018;
BA_ "SPN" SG_ 2566668542 EngnFl2PmpHdrlFlwCntrlVlv 7016;
BA_ "SPN" SG_ 2566668542 EngnFl2PmpHdrlPrssr 7019;
BA_ "SPN" SG_ 2566668542 EngnFl2PmpHdrlSwshPltAngl 7017;
BA_ "SPN" SG_ 2566668798 EngnFl2InjtrMtrngRl1Prssr 7021;
BA_ "SPN" SG_ 2566668798 EngnFl2InjtrMtrngRl1Prssr2 7513;
BA_ "SPN" SG_ 2566668798 EngnFl2InjtrMtrngRl1Tmprtr 7023;
BA_ "SPN" SG_ 2566668798 EngnFl2InjtrMtrngRl2Prssr 7022;
BA_ "SPN" SG_ 2566668798 EngnFl2InjtrMtrngRl2Tmprtr 7024;
BA_ "SPN" SG_ 2566669054 RequiredTirePressure 6989;
BA_ "SPN" SG_ 2566669054 TireLocation 6987;
BA_ "SPN" SG_ 2566669054 TirePressureExtendedRange 6988;
BA_ "SPN" SG_ 2566669310 ColdInflationPressure 6980;
BA_ "SPN" SG_ 2566669310 ExtrmUndrPrssrPrntgThrshld 6982;
BA_ "SPN" SG_ 2566669310 OverPressurePercentageThreshold 6983;
BA_ "SPN" SG_ 2566669310 OverTemperature 6984;
BA_ "SPN" SG_ 2566669310 TireLocation 6979;
BA_ "SPN" SG_ 2566669310 UndrPrssrPrntgThrshld 6981;
BA_ "SPN" SG_ 2566669822 AntennaNumber 6968;
BA_ "SPN" SG_ 2566669822 TireLocation 6971;
BA_ "SPN" SG_ 2566669822 TireSensorNumber 6970;
BA_ "SPN" SG_ 2566669822 TotalNumberofAntennasUsed 6967;
BA_ "SPN" SG_ 2566669822 TrWrlssSgnlStrngthIndtr 6972;
BA_ "SPN" SG_ 2566669822 TtlNmrfTrSnsrsMntrd 6969;
BA_ "SPN" SG_ 2566670078 NumberofTireSensors 6963;
BA_ "SPN" SG_ 2566670078 TireLocation 6965;
BA_ "SPN" SG_ 2566670078 TireNumber 6964;
BA_ "SPN" SG_ 2566670078 TireSensorIdentificationNumber 6966;
